VERSION "dbc-export 1 2026.26.6.5"

NS_ :

BS_:

BU_: APP APS BMS CC CMP CMPD CP DAS DI DIF DIR EPBL EPBR EVSE FC GTW HCML HCMR HVP ICR PCS PCS2 PLG PM PMF PMR PTC SCCM SCM SCS SDCR TAS UMC V2G VC VCBATT VCBATT0 VCBATT1 VCBATT2 VCFRONT VCFRONT1 VCFRONT2 VCLEFT VCRIGHT VCSEAT2L VCSEAT2R VCSEC

BO_ 1951 ADSP_audioVisualizer: 1 GTW
 SG_ ADSP_audioVisualizerBrightness : 0|8@1+ (1,0) [0|255] "" Vector__XXX

BO_ 909 APP_VC_infoMessage: 8 APP
 SG_ APP_inTunnel : 0|2@1+ (1,0) [1|3] "" Vector__XXX
 SG_ APP_windshieldHeaterOnReason : 2|4@1+ (1,0) [1|15] "" Vector__XXX
 SG_ APP_selfieCameraBlocked : 6|2@1+ (1,0) [1|3] "" Vector__XXX
 SG_ APP_selfieCameraLUX : 8|8@1+ (1,0) [0|253] "lux" Vector__XXX
 SG_ APP_sceneTagClearlyRaining : 16|2@1+ (1,0) [1|3] "" Vector__XXX
 SG_ APP_sceneTagFog : 18|2@1+ (1,0) [1|3] "" Vector__XXX
 SG_ APP_sceneTagFullyBlocked : 20|2@1+ (1,0) [1|3] "" Vector__XXX
 SG_ APP_sceneTagIndoors : 22|2@1+ (1,0) [1|3] "" Vector__XXX
 SG_ APP_sceneTagLensFlare : 24|2@1+ (1,0) [1|3] "" Vector__XXX
 SG_ APP_sceneTagRaining : 26|2@1+ (1,0) [1|3] "" Vector__XXX
 SG_ APP_sceneTagSevereWeather : 28|2@1+ (1,0) [1|3] "" Vector__XXX
 SG_ APP_sceneTagSnowing : 30|2@1+ (1,0) [1|3] "" Vector__XXX
 SG_ APP_sceneTagSnowyRoad : 32|2@1+ (1,0) [1|3] "" Vector__XXX
 SG_ APP_sceneTagSunGlare : 34|2@1+ (1,0) [1|3] "" Vector__XXX
 SG_ APP_sceneTagTunnel : 36|2@1+ (1,0) [1|3] "" Vector__XXX
 SG_ APP_sceneTagWetRoad : 38|2@1+ (1,0) [1|3] "" Vector__XXX
 SG_ APP_fisheyeInPathVisibility : 40|3@1+ (1,0) [1|7] "" Vector__XXX
 SG_ APP_fisheyeOverallVisibility : 43|3@1+ (1,0) [1|7] "" Vector__XXX
 SG_ APP_mainInPathVisibility : 46|3@1+ (1,0) [1|7] "" Vector__XXX
 SG_ APP_mainOverallVisibility : 49|3@1+ (1,0) [1|7] "" Vector__XXX
 SG_ APP_narrowInPathVisibility : 52|3@1+ (1,0) [1|7] "" Vector__XXX
 SG_ APP_narrowOverallVisibility : 55|3@1+ (1,0) [1|7] "" Vector__XXX
 SG_ APP_frontCamOcclusionType : 58|3@1+ (1,0) [0|7] "" Vector__XXX

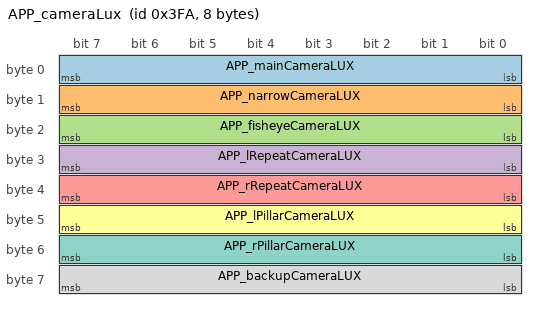
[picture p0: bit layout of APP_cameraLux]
BO_ 1018 APP_cameraLux: 8 APP
 SG_ APP_mainCameraLUX : 0|8@1+ (0.5,0) [0|127] "lux^0.5" Vector__XXX
 SG_ APP_narrowCameraLUX : 8|8@1+ (0.5,0) [0|127] "lux^0.5" Vector__XXX
 SG_ APP_fisheyeCameraLUX : 16|8@1+ (0.5,0) [0|127] "lux^0.5" Vector__XXX
 SG_ APP_lRepeatCameraLUX : 24|8@1+ (0.5,0) [0|127] "lux^0.5" Vector__XXX
 SG_ APP_rRepeatCameraLUX : 32|8@1+ (0.5,0) [0|127] "lux^0.5" Vector__XXX
 SG_ APP_lPillarCameraLUX : 40|8@1+ (0.5,0) [0|127] "lux^0.5" Vector__XXX
 SG_ APP_rPillarCameraLUX : 48|8@1+ (0.5,0) [0|127] "lux^0.5" Vector__XXX
 SG_ APP_backupCameraLUX : 56|8@1+ (0.5,0) [0|127] "lux^0.5" Vector__XXX

BO_ 1056 APS_state: 8 APS
 SG_ APS_primaryTurbo : 0|2@1+ (1,0) [0|3] "" Vector__XXX
 SG_ APS_A_arbState : 2|3@1+ (1,0) [0|7] "" Vector__XXX
 SG_ APS_A_powerState : 5|5@1+ (1,0) [0|31] "" Vector__XXX
 SG_ APS_A_sleepState : 10|4@1+ (1,0) [0|15] "" Vector__XXX
 SG_ APS_A_resetState : 14|3@1+ (1,0) [0|7] "" Vector__XXX
 SG_ APS_A_faultState : 17|5@1+ (1,0) [0|31] "" Vector__XXX
 SG_ APS_secondaryTurbo : 22|2@1+ (1,0) [0|3] "" Vector__XXX
 SG_ APS_B_arbState : 24|3@1+ (1,0) [0|7] "" Vector__XXX
 SG_ APS_B_powerState : 27|5@1+ (1,0) [0|31] "" Vector__XXX
 SG_ APS_B_sleepState : 32|4@1+ (1,0) [0|15] "" Vector__XXX
 SG_ APS_B_resetState : 36|3@1+ (1,0) [0|7] "" Vector__XXX
 SG_ APS_B_faultState : 39|5@1+ (1,0) [0|31] "" Vector__XXX
 SG_ APS_A_autosteerMonitorState : 44|3@1+ (1,0) [0|7] "" Vector__XXX
 SG_ APS_B_autosteerMonitorState : 47|3@1+ (1,0) [0|7] "" Vector__XXX
 SG_ APS_eplannerState : 50|3@1+ (1,0) [0|7] "" Vector__XXX
 SG_ APS_A_faultInduced : 53|1@1+ (1,0) [0|1] "" Vector__XXX
 SG_ APS_B_faultInduced : 54|1@1+ (1,0) [0|1] "" Vector__XXX
 SG_ APS_stateCounter : 55|4@1+ (1,0) [0|15] "" Vector__XXX

BO_ 1343 BMS_alertLog: 8 BMS
 SG_ BMS_alertID M : 0|9@1+ (1,0) [0|511] "" Vector__XXX
 SG_ BMS_alertSet : 15|1@1+ (1,0) [0|1] "" Vector__XXX
 SG_ BMS_a001_gatewayPackEnergy m1 : 16|2@1+ (1,0) [0|3] "" Vector__XXX
 SG_ BMS_a001_expectedPackEnergy m1 : 18|2@1+ (1,0) [0|3] "" Vector__XXX
 SG_ BMS_a002_gatewayPackPerformanceD m2 : 16|3@1+ (1,0) [0|7] "" Vector__XXX
 SG_ BMS_a002_expectedPackPerformance m2 : 19|3@1+ (1,0) [0|7] "" Vector__XXX
 SG_ BMS_a002_bmsPackMass m2 : 24|8@1+ (1,300) [300|555] "kg" Vector__XXX
 SG_ BMS_a003_calBlockData_0 m3 : 16|32@1+ (1,0) [0|4294967295] "" Vector__XXX
 SG_ BMS_a017_packCurrent m17 : 16|8@1+ (8,-1500) [-1500|540] "A" Vector__XXX
 SG_ BMS_a017_ovBrickVID m17 : 24|7@1+ (1,1) [1|128] "" Vector__XXX
 SG_ BMS_a017_ovBrickV m17 : 32|16@1+ (7.62939453125e-05,0) [0|4.99992370605] "V" Vector__XXX
 SG_ BMS_a018_packCurrent m18 : 16|8@1+ (8,-1496) [-1496|544] "A" Vector__XXX
 SG_ BMS_a018_uvBrickVID m18 : 24|7@1+ (1,1) [1|128] "" Vector__XXX
 SG_ BMS_a018_uvBrickV m18 : 32|16@1+ (7.62939453125e-05,0) [0|4.99992370605] "V" Vector__XXX
 SG_ BMS_a019_coolantInletT m19 : 16|8@1+ (0.4,-20) [-20|82] "C" Vector__XXX
 SG_ BMS_a019_activeCoolingTarget m19 : 24|8@1+ (0.4,-20) [-20|82] "C" Vector__XXX
 SG_ BMS_a019_maxBrickT m19 : 32|8@1+ (0.4,-20) [-20|82] "C" Vector__XXX
 SG_ BMS_a019_maxBrickTID m19 : 40|5@1+ (1,1) [1|32] "" Vector__XXX
 SG_ BMS_a021_chargeViolation m21 : 16|1@1+ (1,0) [0|1] "" Vector__XXX
 SG_ BMS_a021_currentLimit m21 : 24|8@1+ (8,-1496) [-1496|544] "A" Vector__XXX
 SG_ BMS_a021_packCurrent m21 : 32|8@1+ (8,-1496) [-1496|544] "A" Vector__XXX
 SG_ BMS_a022_chargeAccumulatorViolat m22 : 16|1@1+ (1,0) [0|1] "" Vector__XXX
 SG_ BMS_a022_chargeAccumulatorValue m22 : 17|23@1+ (10,0) [0|83886070] "A^2s" Vector__XXX
 SG_ BMS_a022_chargeAccumulatorLimit m22 : 40|23@1+ (10,0) [0|83886070] "A^2s" Vector__XXX
 SG_ BMS_a023_ovStackDeviceID m23 : 16|5@1+ (1,1) [1|32] "-" Vector__XXX
 SG_ BMS_a023_ovStackV m23 : 24|16@1+ (0.00128,0) [0|83.8848] "V" Vector__XXX
 SG_ BMS_a024_brickID m24 : 16|8@1+ (1,1) [1|256] "-" Vector__XXX
 SG_ BMS_a024_deltaV m24 : 24|16@1- (0.0001,0) [-3.2768|3.2767] "V" Vector__XXX
 SG_ BMS_a024_avgDvPrev m24 : 40|16@1- (0.0001,0) [-3.2768|3.2767] "V" Vector__XXX
 SG_ BMS_a024_packCurrent m24 : 56|8@1+ (8,-1500) [-1500|540] "A" Vector__XXX
 SG_ BMS_a027_swIsolationCount m27 : 16|8@1+ (1,0) [0|255] "" Vector__XXX
 SG_ BMS_a030_worstBrickID m30 : 16|8@1+ (1,1) [1|256] "" Vector__XXX
 SG_ BMS_a030_maxBrickImpedance m30 : 24|10@1+ (0.1,0) [0|102.3] "mOhm" Vector__XXX
 SG_ BMS_a030_maxNormalizedImpedanceD m30 : 34|7@1+ (0.04,0) [0|5.08] "Ratio" Vector__XXX
 SG_ BMS_a030_faultThreshold m30 : 41|7@1+ (0.04,0) [0|5.08] "Ratio" Vector__XXX
 SG_ BMS_a030_numBricks m30 : 48|8@1+ (1,0) [0|255] "" Vector__XXX
 SG_ BMS_a030_worstBrickSoc m30 : 56|8@1+ (0.5,0) [0|127.5] "PCT" Vector__XXX
 SG_ BMS_a035_isoR m35 : 16|9@1+ (10,0) [0|5110] "kOhm" Vector__XXX
 SG_ BMS_a035_mode m35 : 25|3@1+ (1,0) [0|7] "" Vector__XXX
 SG_ BMS_a035_activeSideVNoR m35 : 28|9@1+ (1,0) [0|511] "V" Vector__XXX
 SG_ BMS_a035_activeSideVWithR m35 : 37|9@1+ (1,0) [0|511] "V" Vector__XXX
 SG_ BMS_a035_passiveSideVNoR m35 : 46|9@1+ (1,0) [0|511] "V" Vector__XXX
 SG_ BMS_a035_passiveSideVWithR m35 : 55|9@1+ (1,0) [0|511] "V" Vector__XXX
 SG_ BMS_a039_dcLinkVoltage m39 : 16|10@1+ (1,0) [0|1023] "V" Vector__XXX
 SG_ BMS_a039_packVoltage m39 : 26|10@1+ (1,0) [0|1023] "V" Vector__XXX
 SG_ BMS_a039_packContactorState m39 : 36|4@1+ (1,0) [1|15] "" Vector__XXX
 SG_ BMS_a039_packCurrent m39 : 40|8@1+ (8,-1496) [-1496|544] "A" Vector__XXX
 SG_ BMS_a039_maxBrickV m39 : 48|8@1+ (0.01,2) [2|4.55] "V" Vector__XXX
 SG_ BMS_a039_state m39 : 56|4@1+ (1,0) [0|15] "" Vector__XXX
 SG_ BMS_a041_resetType m41 : 16|4@1+ (1,0) [0|15] "" Vector__XXX
 SG_ BMS_a050_MIA_numBadReadings m50 : 16|8@1+ (1,0) [0|255] "" Vector__XXX
 SG_ BMS_a050_MIA_numSnaReadings m50 : 24|8@1+ (1,0) [0|255] "" Vector__XXX
 SG_ BMS_a050_MIA_brickId m50 : 32|8@1+ (1,1) [1|256] "" Vector__XXX
 SG_ BMS_a051_hvp1V5Ref m51 : 16|12@1+ (0.001,0) [0|4.095] "V" Vector__XXX
 SG_ BMS_a051_hvp3V0Ref m51 : 28|12@1+ (0.001,0) [0|4.095] "V" Vector__XXX
 SG_ BMS_a051_bms3V0Ref m51 : 40|12@1+ (0.001,0) [0|4.095] "V" Vector__XXX
 SG_ BMS_a059_sumBrickVoltages m59 : 16|16@1+ (0.01,0) [0|655.35] "V" Vector__XXX
 SG_ BMS_a059_packVoltage m59 : 32|16@1+ (0.01,0) [0|655.35] "V" Vector__XXX
 SG_ BMS_a062_state m62 : 16|4@1+ (1,0) [0|15] "" Vector__XXX
 SG_ BMS_a062_minBrickVId m62 : 24|7@1+ (1,1) [1|128] "" Vector__XXX
 SG_ BMS_a062_minBrickVoltage m62 : 32|12@1+ (0.002,0) [0|8.19] "V" Vector__XXX
 SG_ BMS_a062_maxBrickVId m62 : 44|7@1+ (1,1) [1|128] "" Vector__XXX
 SG_ BMS_a062_maxBrickVoltage m62 : 51|12@1+ (0.002,0) [0|8.19] "V" Vector__XXX
 SG_ BMS_a063_cpFaultInV m63 : 16|12@1+ (0.001,0) [0|4.095] "V" Vector__XXX
 SG_ BMS_a064_minBrickSOCID m64 : 16|7@1+ (1,1) [1|128] "" Vector__XXX
 SG_ BMS_a064_minBrickSOC m64 : 24|8@1+ (0.5,0) [0|127.5] "PCT" Vector__XXX
 SG_ BMS_a064_maxBrickSOCID m64 : 32|7@1+ (1,1) [1|128] "" Vector__XXX
 SG_ BMS_a064_maxBrickSOC m64 : 40|8@1+ (0.5,0) [0|127.5] "PCT" Vector__XXX
 SG_ BMS_a064_avgBrickSOC m64 : 48|8@1+ (0.5,0) [0|127.5] "PCT" Vector__XXX
 SG_ BMS_a065_minBrickCacId m65 : 16|7@1+ (1,1) [1|128] "" Vector__XXX
 SG_ BMS_a065_minBrickCac m65 : 24|13@1+ (0.1,0) [0|819.1] "Ah" Vector__XXX
 SG_ BMS_a065_avgBrickCac m65 : 40|13@1+ (0.1,0) [0|819.1] "Ah" Vector__XXX
 SG_ BMS_a065_modCacImbalancePct m65 : 53|10@1+ (0.1,0) [0|102.3] "%" Vector__XXX
 SG_ BMS_a066_minBrickSocId m66 : 16|7@1+ (1,1) [1|128] "" Vector__XXX
 SG_ BMS_a066_minBrickSocByOcvMax m66 : 24|8@1+ (0.5,0) [0|127.5] "PCT" Vector__XXX
 SG_ BMS_a066_maxBrickSocId m66 : 32|7@1+ (1,1) [1|128] "" Vector__XXX
 SG_ BMS_a066_maxBrickSocByOcvMin m66 : 40|8@1+ (0.5,0) [0|127.5] "PCT" Vector__XXX
 SG_ BMS_a066_maxBrickSoc m66 : 48|8@1+ (0.5,0) [0|127.5] "PCT" Vector__XXX
 SG_ BMS_a066_avgBrickSoc m66 : 56|8@1+ (0.5,0) [0|127.5] "PCT" Vector__XXX
 SG_ BMS_a067_minBrickCacId m67 : 16|7@1+ (1,1) [1|128] "" Vector__XXX
 SG_ BMS_a067_minBrickCac m67 : 24|13@1+ (0.1,0) [0|819.1] "Ah" Vector__XXX
 SG_ BMS_a067_avgBrickCac m67 : 40|13@1+ (0.1,0) [0|819.1] "Ah" Vector__XXX
 SG_ BMS_a067_modCacImbalancePct m67 : 53|10@1+ (0.1,0) [0|102.3] "%" Vector__XXX
 SG_ BMS_a068_minBrickCacId m68 : 16|7@1+ (1,1) [1|128] "" Vector__XXX
 SG_ BMS_a068_minBrickCac m68 : 24|13@1+ (0.1,0) [0|819.1] "Ah" Vector__XXX
 SG_ BMS_a068_avgBrickCac m68 : 40|13@1+ (0.1,0) [0|819.1] "Ah" Vector__XXX
 SG_ BMS_a068_modCacImbalancePct m68 : 53|10@1+ (0.1,0) [0|102.3] "%" Vector__XXX
 SG_ BMS_a069_dischargePowerPackVolta m69 : 16|8@1- (0.025,-3.15) [-6.35|0.025] "kW" Vector__XXX
 SG_ BMS_a069_dischargePowerBrickVolt m69 : 24|8@1- (0.005,-0.63) [-1.27|0.005] "kW" Vector__XXX
 SG_ BMS_a069_SOC m69 : 32|8@1+ (0.05,0) [0|12.75] "PCT" Vector__XXX
 SG_ BMS_a069_minBrickT m69 : 40|8@1- (0.5,24) [-40|87.5] "DegC" Vector__XXX
 SG_ BMS_a069_minBrickVLimit m69 : 48|8@1+ (0.01,2) [2|4.55] "V" Vector__XXX
 SG_ BMS_a069_minBrickV m69 : 56|8@1+ (0.01,2) [2|4.55] "V" Vector__XXX
 SG_ BMS_a070_state m70 : 16|4@1+ (1,0) [0|15] "" Vector__XXX
 SG_ BMS_a070_minBrickVId m70 : 24|7@1+ (1,1) [1|128] "" Vector__XXX
 SG_ BMS_a070_minBrickVoltage m70 : 32|12@1+ (0.002,0) [0|8.19] "V" Vector__XXX
 SG_ BMS_a070_maxBrickVId m70 : 44|7@1+ (1,1) [1|128] "" Vector__XXX
 SG_ BMS_a070_maxBrickVoltage m70 : 51|12@1+ (0.002,0) [0|8.19] "V" Vector__XXX
 SG_ BMS_a071_stateRequest m71 : 16|4@1+ (1,0) [0|15] "" Vector__XXX
 SG_ BMS_a071_state m71 : 20|4@1+ (1,0) [0|15] "" Vector__XXX
 SG_ BMS_a071_transitionAlertId m71 : 24|10@1+ (1,0) [0|1023] "" Vector__XXX
 SG_ BMS_a074_maxBrickVTarget m74 : 16|8@1+ (0.01,2) [2|4.55] "V" Vector__XXX
 SG_ BMS_a074_maxBrickV m74 : 24|8@1+ (0.01,2) [2|4.55] "V" Vector__XXX
 SG_ BMS_a075_chargeType m75 : 16|1@1+ (1,0) [0|1] "" Vector__XXX
 SG_ BMS_a076_netAh m76 : 16|21@1- (0.01,0) [-10485.76|10485.75] "Ah" Vector__XXX
 SG_ BMS_a076_tetheringActive m76 : 37|1@1+ (1,0) [0|1] "" Vector__XXX
 SG_ BMS_a077_chargeErrType m77 : 16|1@1+ (1,0) [0|1] "" Vector__XXX
 SG_ BMS_a077_maxBrickVTarget m77 : 24|8@1+ (0.01,2) [2|4.55] "V" Vector__XXX
 SG_ BMS_a077_maxBrickV m77 : 32|8@1+ (0.01,2) [2|4.55] "V" Vector__XXX
 SG_ BMS_a077_packTargetCurrent m77 : 40|8@1+ (8,-1496) [-1496|544] "A" Vector__XXX
 SG_ BMS_a077_packCurrent m77 : 48|8@1+ (8,-1496) [-1496|544] "A" Vector__XXX
 SG_ BMS_a078_peakDchInChg m78 : 16|16@1- (0.1,0) [-3276.8|3276.7] "A" Vector__XXX
 SG_ BMS_a079_maxBrickVTarget m79 : 16|8@1+ (0.01,2) [2|4.55] "V" Vector__XXX
 SG_ BMS_a079_maxBrickV m79 : 24|8@1+ (0.01,2) [2|4.55] "V" Vector__XXX
 SG_ BMS_a081_stateRequest m81 : 16|4@1+ (1,0) [0|15] "" Vector__XXX
 SG_ BMS_a081_firstBlockingAlertId m81 : 20|9@1+ (1,0) [0|511] "" Vector__XXX
 SG_ BMS_a081_secondBlockingAlertId m81 : 29|9@1+ (1,0) [0|511] "" Vector__XXX
 SG_ BMS_a081_thirdBlockingAlertId m81 : 38|9@1+ (1,0) [0|511] "" Vector__XXX
 SG_ BMS_a081_fourthBlockingAlertId m81 : 47|9@1+ (1,0) [0|511] "" Vector__XXX
 SG_ BMS_a081_totalAlertCount m81 : 56|8@1+ (1,0) [0|255] "" Vector__XXX
 SG_ BMS_a082_stateRequest m82 : 16|4@1+ (1,0) [0|15] "" Vector__XXX
 SG_ BMS_a082_firstAlertId m82 : 20|9@1+ (1,0) [0|511] "" Vector__XXX
 SG_ BMS_a082_secondAlertId m82 : 29|9@1+ (1,0) [0|511] "" Vector__XXX
 SG_ BMS_a082_thirdAlertId m82 : 38|9@1+ (1,0) [0|511] "" Vector__XXX
 SG_ BMS_a082_fourthAlertId m82 : 47|9@1+ (1,0) [0|511] "" Vector__XXX
 SG_ BMS_a082_totalAlertCount m82 : 56|8@1+ (1,0) [0|255] "" Vector__XXX
 SG_ BMS_a083_packContactorRequest m83 : 16|3@1+ (1,0) [1|7] "" Vector__XXX
 SG_ BMS_a085_packContactorSetStatePr m85 : 16|4@1+ (1,0) [1|15] "" Vector__XXX
 SG_ BMS_a085_packContactorSetState m85 : 20|4@1+ (1,0) [1|15] "" Vector__XXX
 SG_ BMS_a085_packContactorSetRe_0001 m85 : 24|3@1+ (1,0) [1|7] "" Vector__XXX
 SG_ BMS_a085_packContactorSetRequest m85 : 27|3@1+ (1,0) [1|7] "" Vector__XXX
 SG_ BMS_a086_fcContactorSetStatePrev m86 : 16|4@1+ (1,0) [1|15] "" Vector__XXX
 SG_ BMS_a086_fcContactorSetState m86 : 20|4@1+ (1,0) [1|15] "" Vector__XXX
 SG_ BMS_a086_fcContactorSetRequestPr m86 : 24|3@1+ (1,0) [1|7] "" Vector__XXX
 SG_ BMS_a086_fcContactorSetRequest m86 : 27|3@1+ (1,0) [1|7] "" Vector__XXX
 SG_ BMS_a087_blockingAlert m87 : 16|9@1+ (1,0) [0|511] "" Vector__XXX
 SG_ BMS_a090_GTWmessageTout m90 : 16|4@1+ (1,0) [0|15] "" Vector__XXX
 SG_ BMS_a098_breakLocationA m98 : 16|5@1+ (1,0) [0|31] "" Vector__XXX
 SG_ BMS_a098_bmbCommStatusTypeA m98 : 21|2@1+ (1,0) [0|3] "" Vector__XXX
 SG_ BMS_a098_breakLocationB m98 : 24|5@1+ (1,0) [0|31] "" Vector__XXX
 SG_ BMS_a098_bmbCommStatusTypeB m98 : 29|2@1+ (1,0) [0|3] "" Vector__XXX
 SG_ BMS_a098_alertFromHvp m98 : 31|1@1+ (1,0) [0|1] "" Vector__XXX
 SG_ BMS_a099_breakLocationA m99 : 16|5@1+ (1,0) [0|31] "" Vector__XXX
 SG_ BMS_a099_bmbCommStatusTypeA m99 : 21|2@1+ (1,0) [0|3] "" Vector__XXX
 SG_ BMS_a099_breakLocationB m99 : 24|5@1+ (1,0) [0|31] "" Vector__XXX
 SG_ BMS_a099_bmbCommStatusTypeB m99 : 29|2@1+ (1,0) [0|3] "" Vector__XXX
 SG_ BMS_a099_bmbChainBreakType m99 : 32|3@1+ (1,0) [0|7] "" Vector__XXX
 SG_ BMS_a099_alertFromHvp m99 : 35|1@1+ (1,0) [0|1] "" Vector__XXX
 SG_ BMS_a100_testTrigger m100 : 16|1@1+ (1,0) [0|1] "" Vector__XXX
 SG_ BMS_a100_setFromNvm m100 : 17|1@1+ (1,0) [0|1] "" Vector__XXX
 SG_ BMS_a100_voltageDeviation m100 : 18|1@1+ (1,0) [0|1] "" Vector__XXX
 SG_ BMS_a100_voltageLoss m100 : 19|1@1+ (1,0) [0|1] "" Vector__XXX
 SG_ BMS_a105_tSenseFailedModule1 m105 : 16|1@1+ (1,0) [0|1] "" Vector__XXX
 SG_ BMS_a105_avgBrickTModule1 m105 : 17|8@1+ (0.5,0) [0|127.5] "C" Vector__XXX
 SG_ BMS_a105_tSenseFailedModule2 m105 : 25|1@1+ (1,0) [0|1] "" Vector__XXX
 SG_ BMS_a105_avgBrickTModule2 m105 : 26|8@1+ (0.5,0) [0|127.5] "C" Vector__XXX
 SG_ BMS_a105_tSenseFailedModule3 m105 : 34|1@1+ (1,0) [0|1] "" Vector__XXX
 SG_ BMS_a105_avgBrickTModule3 m105 : 35|8@1+ (0.5,0) [0|127.5] "C" Vector__XXX
 SG_ BMS_a105_tSenseFailedModule4 m105 : 43|1@1+ (1,0) [0|1] "" Vector__XXX
 SG_ BMS_a105_avgBrickTModule4 m105 : 44|8@1+ (0.5,0) [0|127.5] "C" Vector__XXX
 SG_ BMS_a105_inletTemp m105 : 52|8@1+ (0.5,0) [0|127.5] "C" Vector__XXX
 SG_ BMS_a106_minBrickT m106 : 16|8@1+ (0.5,0) [0|127.5] "C" Vector__XXX
 SG_ BMS_a106_maxBrickT m106 : 24|8@1+ (0.5,0) [0|127.5] "C" Vector__XXX
 SG_ BMS_a106_avgBrickT m106 : 32|8@1+ (0.5,0) [0|127.5] "C" Vector__XXX
 SG_ BMS_a106_inletTemp m106 : 40|8@1+ (0.5,0) [0|127.5] "C" Vector__XXX
 SG_ BMS_a107_MIA_numBadReadings m107 : 16|8@1+ (1,0) [0|255] "" Vector__XXX
 SG_ BMS_a107_MIA_numSnaReadings m107 : 24|8@1+ (1,0) [0|255] "" Vector__XXX
 SG_ BMS_a107_MIA_stackId m107 : 32|8@1+ (1,1) [1|256] "" Vector__XXX
 SG_ BMS_a109_muteMask m109 : 16|16@1+ (1,0) [0|65535] "" Vector__XXX
 SG_ BMS_a109_packInBleed m109 : 32|1@1+ (1,0) [0|1] "" Vector__XXX
 SG_ BMS_a117_brickID m117 : 16|7@1+ (1,1) [1|128] "" Vector__XXX
 SG_ BMS_a117_brickSoc2 m117 : 23|10@1+ (0.1,0) [0|102.2] "%" Vector__XXX
 SG_ BMS_a117_dSocAlertThreshold m117 : 33|5@1+ (0.125,-4) [-4|-0.125] "%" Vector__XXX
 SG_ BMS_a117_dSocAlpha m117 : 48|12@1+ (0.0030517578125,-12.4969482422) [-12.4969482422|-0.003051757825] "%" Vector__XXX
 SG_ BMS_a118_brickID m118 : 16|7@1+ (1,1) [1|128] "" Vector__XXX
 SG_ BMS_a118_brickSoc2 m118 : 23|10@1+ (0.1,0) [0|102.2] "%" Vector__XXX
 SG_ BMS_a118_dSocAlertThreshold m118 : 33|5@1+ (0.125,-4) [-4|-0.125] "%" Vector__XXX
 SG_ BMS_a118_dSocAlpha m118 : 48|12@1+ (0.0030517578125,-12.4969482422) [-12.4969482422|-0.003051757825] "%" Vector__XXX
 SG_ BMS_a122_thermistorID m122 : 16|5@1+ (1,1) [1|32] "" Vector__XXX
 SG_ BMS_a122_irrationalThermistorTem m122 : 24|8@1+ (0.5,-40) [-40|87.5] "DegC" Vector__XXX
 SG_ BMS_a122_averageRawThermistorTem m122 : 32|8@1+ (0.5,-40) [-40|87.5] "DegC" Vector__XXX
 SG_ BMS_a122_minRawThermistorTemp m122 : 40|8@1+ (0.5,-40) [-40|87.5] "DegC" Vector__XXX
 SG_ BMS_a122_maxRawThermistorTemp m122 : 48|8@1+ (0.5,-40) [-40|87.5] "DegC" Vector__XXX
 SG_ BMS_a122_numValidThermistors m122 : 56|5@1+ (1,0) [0|31] "" Vector__XXX
 SG_ BMS_a123_packPlus m123 : 32|8@1+ (4,0) [0|1020] "V" Vector__XXX
 SG_ BMS_a123_isoR m123 : 40|10@1+ (10,0) [0|10230] "kOhm" Vector__XXX
 SG_ BMS_a123_packMinus m123 : 56|8@1- (4,0) [-512|508] "V" Vector__XXX
 SG_ BMS_a129_brickID m129 : 16|8@1+ (1,1) [1|256] "-" Vector__XXX
 SG_ BMS_a129_deltaV m129 : 24|16@1- (0.0002,0) [-6.5536|6.5534] "V" Vector__XXX
 SG_ BMS_a129_retryCount m129 : 40|4@1+ (1,0) [0|15] "-" Vector__XXX
 SG_ BMS_a131_brickID m131 : 16|8@1+ (1,1) [1|256] "-" Vector__XXX
 SG_ BMS_a131_deltaV m131 : 24|16@1- (0.0002,0) [-6.5536|6.5534] "V" Vector__XXX
 SG_ BMS_a131_retryCount m131 : 40|4@1+ (1,0) [0|15] "-" Vector__XXX
 SG_ BMS_a132_multiVendorErrorMask m132 : 16|16@1+ (1,0) [0|65535] "" Vector__XXX
 SG_ BMS_a135_bmbDiagnosticsType m135 : 16|2@1+ (1,0) [0|3] "" Vector__XXX
 SG_ BMS_a135_bmbDeviceId m135 : 18|4@1+ (1,1) [1|16] "" Vector__XXX
 SG_ BMS_a135_readCVA m135 : 22|1@1+ (1,0) [0|1] "" Vector__XXX
 SG_ BMS_a135_readCVB m135 : 23|1@1+ (1,0) [0|1] "" Vector__XXX
 SG_ BMS_a135_readCVC m135 : 24|1@1+ (1,0) [0|1] "" Vector__XXX
 SG_ BMS_a135_readCVD m135 : 25|1@1+ (1,0) [0|1] "" Vector__XXX
 SG_ BMS_a135_readCVE m135 : 26|1@1+ (1,0) [0|1] "" Vector__XXX
 SG_ BMS_a135_readCVF m135 : 27|1@1+ (1,0) [0|1] "" Vector__XXX
 SG_ BMS_a135_readSNA m135 : 28|1@1+ (1,0) [0|1] "" Vector__XXX
 SG_ BMS_a135_readSNB m135 : 29|1@1+ (1,0) [0|1] "" Vector__XXX
 SG_ BMS_a135_readSNC m135 : 30|1@1+ (1,0) [0|1] "" Vector__XXX
 SG_ BMS_a135_readSND m135 : 31|1@1+ (1,0) [0|1] "" Vector__XXX
 SG_ BMS_a135_readSNE m135 : 32|1@1+ (1,0) [0|1] "" Vector__XXX
 SG_ BMS_a135_readSNF m135 : 33|1@1+ (1,0) [0|1] "" Vector__XXX
 SG_ BMS_a135_readAUXA m135 : 34|1@1+ (1,0) [0|1] "" Vector__XXX
 SG_ BMS_a135_readAUXB m135 : 35|1@1+ (1,0) [0|1] "" Vector__XXX
 SG_ BMS_a135_readSTAT m135 : 36|1@1+ (1,0) [0|1] "" Vector__XXX
 SG_ BMS_a136_maxBrickTID m136 : 16|5@1+ (1,1) [1|32] "" Vector__XXX
 SG_ BMS_a136_coolantInletT m136 : 24|8@1+ (0.4,-20) [-20|82] "C" Vector__XXX
 SG_ BMS_a136_activeCoolingTarget m136 : 32|8@1+ (0.4,-20) [-20|82] "C" Vector__XXX
 SG_ BMS_a136_maxBrickT m136 : 40|8@1+ (0.4,-20) [-20|82] "C" Vector__XXX
 SG_ BMS_a139_packVoltage m139 : 16|16@1- (0.01,0) [-327.68|327.67] "V" Vector__XXX
 SG_ BMS_a139_dcLinkVoltage m139 : 32|16@1+ (0.01,0) [0|655.35] "V" Vector__XXX
 SG_ BMS_a140_bmbDeviceMask m140 : 16|16@1+ (1,0) [0|65535] "" Vector__XXX
 SG_ BMS_a140_faultType m140 : 32|8@1+ (1,0) [0|255] "" Vector__XXX
 SG_ BMS_a142_isolationResistance m142 : 16|10@1+ (10,0) [0|10230] "kOhm" Vector__XXX
 SG_ BMS_a142_mode m142 : 32|3@1+ (1,0) [0|7] "" Vector__XXX
 SG_ BMS_a143_initialSoc m143 : 16|9@1+ (0.2,0) [0|102.2] "%" Vector__XXX
 SG_ BMS_a143_endingSoc m143 : 25|9@1+ (0.2,0) [0|102.2] "%" Vector__XXX
 SG_ BMS_a143_deltaAh m143 : 34|9@1+ (0.5,0) [0|255.5] "Ah" Vector__XXX
 SG_ BMS_a143_cacChangeBrickID m143 : 48|7@1+ (1,1) [1|128] "" Vector__XXX
 SG_ BMS_a143_cacUpdateError m143 : 56|8@1+ (0.1,0) [0|25.5] "Ah" Vector__XXX
 SG_ BMS_a144_HVP_major_version m144 : 16|16@1+ (1,0) [0|65535] "" Vector__XXX
 SG_ BMS_a144_HVP_minor_version m144 : 32|16@1+ (1,0) [0|65535] "" Vector__XXX
 SG_ BMS_a144_BMS_minor_version m144 : 48|16@1+ (1,0) [0|65535] "" Vector__XXX
 SG_ BMS_a145_maxSocChange m145 : 16|11@1- (0.1,0) [-102.4|102.3] "%" Vector__XXX
 SG_ BMS_a145_maxSocChangeBrickID m145 : 32|7@1+ (1,1) [1|128] "" Vector__XXX
 SG_ BMS_a145_numBricksChanged m145 : 40|7@1+ (1,0) [0|127] "" Vector__XXX
 SG_ BMS_a145_brickChangeHystRatio m145 : 48|10@1+ (0.001,0) [0|1.022] "Ratio" Vector__XXX
 SG_ BMS_a146_maxBrickV m146 : 16|8@1+ (0.01,2) [2|4.55] "V" Vector__XXX
 SG_ BMS_a146_state m146 : 24|4@1+ (1,0) [0|15] "" Vector__XXX
 SG_ BMS_a146_packCurrent m146 : 32|8@1+ (8,-1496) [-1496|544] "A" Vector__XXX
 SG_ BMS_a146_uvBrickVID m146 : 40|7@1+ (1,1) [1|128] "" Vector__XXX
 SG_ BMS_a146_uvBrickV m146 : 48|16@1+ (7.62939453125e-05,0) [0|4.99992370605] "V" Vector__XXX
 SG_ BMS_a151_isoPositiveR m151 : 32|10@1+ (10,0) [0|10230] "kOhm" Vector__XXX
 SG_ BMS_a151_isoNegativeR m151 : 42|10@1+ (10,0) [0|10230] "kOhm" Vector__XXX
 SG_ BMS_a152_isoR m152 : 16|9@1+ (10,0) [0|5110] "kOhm" Vector__XXX
 SG_ BMS_a152_mode m152 : 25|3@1+ (1,0) [0|7] "" Vector__XXX
 SG_ BMS_a152_activeSideVNoR m152 : 28|9@1+ (1,0) [0|511] "V" Vector__XXX
 SG_ BMS_a152_activeSideVWithR m152 : 37|9@1+ (1,0) [0|511] "V" Vector__XXX
 SG_ BMS_a152_passiveSideVNoR m152 : 46|9@1+ (1,0) [0|511] "V" Vector__XXX
 SG_ BMS_a152_passiveSideVWithR m152 : 55|9@1+ (1,0) [0|511] "V" Vector__XXX
 SG_ BMS_a154_packCurrent m154 : 16|8@1+ (4,0) [0|1020] "A" Vector__XXX
 SG_ BMS_a154_ovBrickVID m154 : 24|7@1+ (1,1) [1|128] "" Vector__XXX
 SG_ BMS_a154_ovBrickV m154 : 32|16@1+ (7.62939453125e-05,0) [0|4.99992370605] "V" Vector__XXX
 SG_ BMS_a156_VrefSample m156 : 16|16@1+ (0.0001,0) [0|6.5535] "V" Vector__XXX
 SG_ BMS_a156_bmbDeviceId m156 : 32|4@1+ (1,1) [1|16] "" Vector__XXX
 SG_ BMS_a156_VrefStatus m156 : 36|2@1+ (1,0) [0|3] "" Vector__XXX
 SG_ BMS_a158_shuntCurrentMia m158 : 16|1@1+ (1,0) [0|1] "" Vector__XXX
 SG_ BMS_a158_contactorStateMia m158 : 17|1@1+ (1,0) [0|1] "" Vector__XXX
 SG_ BMS_a158_hvpFaultsMia m158 : 18|1@1+ (1,0) [0|1] "" Vector__XXX
 SG_ BMS_a162_dischargePower_W m162 : 16|16@1- (1,0) [-32768|32767] "W" Vector__XXX
 SG_ BMS_a162_minSoc m162 : 32|16@1+ (1,0) [0|65535] "%" Vector__XXX
 SG_ BMS_a162_socThreshold m162 : 48|16@1+ (1,0) [0|65535] "%" Vector__XXX
 SG_ BMS_a164_regenPower m164 : 16|32@1+ (1,0) [0|4294967295] "W" Vector__XXX
 SG_ BMS_a165_packPositiveV m165 : 16|12@1- (0.25,0) [-512|511.75] "V" Vector__XXX
 SG_ BMS_a165_packNegativeV m165 : 28|12@1- (0.25,0) [-512|511.75] "V" Vector__XXX
 SG_ BMS_a165_dcLinkPositiveV m165 : 40|12@1- (0.25,0) [-512|511.75] "V" Vector__XXX
 SG_ BMS_a165_dcLinkNegativeV m165 : 52|12@1- (0.25,0) [-512|511.75] "V" Vector__XXX
 SG_ BMS_a166_packPositiveV m166 : 16|12@1- (0.25,0) [-512|511.75] "V" Vector__XXX
 SG_ BMS_a166_packNegativeV m166 : 28|12@1- (0.25,0) [-512|511.75] "V" Vector__XXX
 SG_ BMS_a166_dcLinkPositiveV m166 : 40|12@1- (0.25,0) [-512|511.75] "V" Vector__XXX
 SG_ BMS_a166_dcLinkNegativeV m166 : 52|12@1- (0.25,0) [-512|511.75] "V" Vector__XXX
 SG_ BMS_a167_fcContPositiveAuxOpen m167 : 16|1@1+ (1,0) [0|1] "" Vector__XXX
 SG_ BMS_a167_fcContNegativeAuxOpen m167 : 17|1@1+ (1,0) [0|1] "" Vector__XXX
 SG_ BMS_a167_dcLinkPositiveV m167 : 18|11@1- (0.5,0) [-512|511.5] "V" Vector__XXX
 SG_ BMS_a167_dcLinkNegativeV m167 : 29|11@1- (0.5,0) [-512|511.5] "V" Vector__XXX
 SG_ BMS_a167_fcLinkPositiveV m167 : 40|11@1- (0.5,0) [-512|511.5] "V" Vector__XXX
 SG_ BMS_a167_fcLinkNegativeV m167 : 51|11@1- (0.5,0) [-512|511.5] "V" Vector__XXX
 SG_ BMS_a168_fcContPositiveAuxOpen m168 : 16|1@1+ (1,0) [0|1] "" Vector__XXX
 SG_ BMS_a168_fcContNegativeAuxOpen m168 : 17|1@1+ (1,0) [0|1] "" Vector__XXX
 SG_ BMS_a168_dcLinkPositiveV m168 : 18|11@1- (0.5,0) [-512|511.5] "V" Vector__XXX
 SG_ BMS_a168_dcLinkNegativeV m168 : 29|11@1- (0.5,0) [-512|511.5] "V" Vector__XXX
 SG_ BMS_a168_fcLinkPositiveV m168 : 40|11@1- (0.5,0) [-512|511.5] "V" Vector__XXX
 SG_ BMS_a168_fcLinkNegativeV m168 : 51|11@1- (0.5,0) [-512|511.5] "V" Vector__XXX
 SG_ BMS_a169_DCAndFCContactorsWelded m169 : 16|1@1+ (1,0) [0|1] "" Vector__XXX
 SG_ BMS_a170_limpModeActive m170 : 16|1@1+ (1,0) [0|1] "" Vector__XXX
 SG_ BMS_a171_stackVoltage m171 : 16|16@1+ (0.00128,0) [0|83.8848] "V" Vector__XXX
 SG_ BMS_a171_sumBrickVoltage m171 : 32|16@1+ (0.00128,0) [0|83.8848] "V" Vector__XXX
 SG_ BMS_a171_stackId m171 : 48|8@1+ (1,1) [1|256] "" Vector__XXX
 SG_ BMS_a172_swIsolationCount m172 : 16|8@1+ (1,0) [0|255] "" Vector__XXX
 SG_ BMS_a177_energyAlertThreshold m177 : 16|10@1+ (0.1,0) [0|102.3] "KWh" Vector__XXX
 SG_ BMS_a177_energyBuffer m177 : 26|10@1+ (0.1,0) [0|102.3] "KWh" Vector__XXX
 SG_ BMS_a178_diPower m178 : 16|9@1- (4.3137254715,250.196075439) [-854.117645265|1350.19607067] "kW" Vector__XXX
 SG_ BMS_a178_energyError m178 : 25|8@1- (2,0) [-256|254] "kJ" Vector__XXX
 SG_ BMS_a178_powerError m178 : 33|9@1- (1,0) [-256|255] "kW" Vector__XXX
 SG_ BMS_a178_minPowerError m178 : 42|9@1- (1,0) [-256|255] "kW" Vector__XXX
 SG_ BMS_a178_maxPowerError m178 : 51|9@1- (1,0) [-256|255] "kW" Vector__XXX
 SG_ BMS_a178_diMiaCount m178 : 60|2@1+ (1,0) [0|3] "" Vector__XXX
 SG_ BMS_a178_diSnaCount m178 : 62|2@1+ (1,0) [0|3] "" Vector__XXX
 SG_ BMS_a188_currentTripThreshold m188 : 16|16@1+ (0.0025,0) [0|163.8375] "A" Vector__XXX
 SG_ BMS_a188_dcLinkDetectedCurrent m188 : 32|16@1+ (0.0025,0) [0|163.8375] "A" Vector__XXX
 SG_ BMS_a189_currentTripThreshold m189 : 16|16@1- (0.0025,-75) [-156.92|6.9175] "A" Vector__XXX
 SG_ BMS_a189_dcLinkDetectedCurrent m189 : 32|16@1- (0.0025,-75) [-156.92|6.9175] "A" Vector__XXX
 SG_ BMS_a190_voltageTripThreshold m190 : 16|16@1+ (0.025,0) [0|1638.375] "V" Vector__XXX
 SG_ BMS_a190_dcLinkDetectedVoltage m190 : 32|16@1+ (0.025,0) [0|1638.375] "V" Vector__XXX
 SG_ BMS_a191_voltageTripThreshold m191 : 16|16@1+ (0.025,0) [0|1638.375] "V" Vector__XXX
 SG_ BMS_a191_dcLinkDetectedVoltage m191 : 32|16@1+ (0.025,0) [0|1638.375] "V" Vector__XXX
 SG_ BMS_a192_detectedChargeCurrent m192 : 16|16@1+ (0.0025,0) [0|163.8375] "A" Vector__XXX
 SG_ BMS_a193_maxBrickVoltageLimit m193 : 16|12@1+ (0.001,1) [1|5.095] "V" Vector__XXX
 SG_ BMS_a193_detectedMaxBrickVoltage m193 : 28|12@1+ (0.001,1) [1|5.095] "V" Vector__XXX
 SG_ BMS_a201_maxBrickV m201 : 16|16@1+ (7.62939453125e-05,0) [0|4.99992370605] "V" Vector__XXX
 SG_ BMS_a201_maxBrickVIndex m201 : 32|7@1+ (1,1) [1|128] "" Vector__XXX
 SG_ BMS_a227_packCurrent m227 : 16|16@1- (0.1,0) [-3276.8|3276.7] "A" Vector__XXX
 SG_ BMS_a227_dcChargeCurrentRequest m227 : 32|16@1- (0.1,0) [-3276.8|3276.7] "A" Vector__XXX
 SG_ BMS_a256_minBrickT m256 : 16|8@1- (0.5,24) [-40|87.5] "C" Vector__XXX
 SG_ BMS_a256_maxBrickT m256 : 24|8@1- (0.5,24) [-40|87.5] "C" Vector__XXX
 SG_ BMS_a256_minBrickV m256 : 32|8@1+ (0.01,2) [2|4.55] "V" Vector__XXX
 SG_ BMS_a256_maxBrickV m256 : 40|8@1+ (0.01,2) [2|4.55] "V" Vector__XXX
 SG_ BMS_a256_packSoe m256 : 48|8@1+ (0.393700778484,0) [0|100.393698513] "%" Vector__XXX
 SG_ BMS_a256_SOC m256 : 56|8@1+ (0.05,0) [0|12.75] "%" Vector__XXX

BO_TX_BU_ 1951 : GTW;
BO_TX_BU_ 909 : APP;
BO_TX_BU_ 1018 : APP;
BO_TX_BU_ 1056 : APS;
BO_TX_BU_ 1343 : BMS;

CM_ "Tesla Model 3 / Model Y CAN bus database; bus VEH (vehicle CAN); firmware 2026.26.6.5. Decoded CAN signal definitions (layout, scaling, units, value tables).";
CM_ BU_ APP "Driver assistance computer (primary)";
CM_ BU_ APS "Driver assistance computer (secondary)";
CM_ BU_ BMS "High-voltage battery management system";
CM_ BU_ CC "Charge cable controller";
CM_ BU_ CMP "A/C compressor";
CM_ BU_ CMPD "CMPD ECU";
CM_ BU_ CP "Charge port controller";
CM_ BU_ DAS "Driver assistance computer";
CM_ BU_ DI "Drive inverter";
CM_ BU_ DIF "Front drive inverter";
CM_ BU_ DIR "Rear drive inverter";
CM_ BU_ EPBL "Left electric parking brake";
CM_ BU_ EPBR "Right electric parking brake";
CM_ BU_ EVSE "EVSE ECU";
CM_ BU_ FC "FC ECU";
CM_ BU_ GTW "Gateway";
CM_ BU_ HCML "HCML ECU";
CM_ BU_ HCMR "HCMR ECU";
CM_ BU_ HVP "High-voltage processor (pack contactor and isolation controller)";
CM_ BU_ ICR "ICR ECU";
CM_ BU_ PCS "Power conversion system (on-board charger and DC-DC converter)";
CM_ BU_ PCS2 "PCS2 ECU";
CM_ BU_ PLG "PLG ECU";
CM_ BU_ PM "PM ECU";
CM_ BU_ PMF "PMF ECU";
CM_ BU_ PMR "PMR ECU";
CM_ BU_ PTC "Cabin heater";
CM_ BU_ SCCM "Steering column control module";
CM_ BU_ SCM "SCM ECU";
CM_ BU_ SCS "SCS ECU";
CM_ BU_ SDCR "SDCR ECU";
CM_ BU_ TAS "Air suspension controller";
CM_ BU_ UMC "UMC ECU";
CM_ BU_ V2G "V2G ECU";
CM_ BU_ VC "VC ECU";
CM_ BU_ VCBATT "VCBATT ECU";
CM_ BU_ VCBATT0 "VCBATT0 ECU";
CM_ BU_ VCBATT1 "VCBATT1 ECU";
CM_ BU_ VCBATT2 "VCBATT2 ECU";
CM_ BU_ VCFRONT "Front body controller";
CM_ BU_ VCFRONT1 "VCFRONT1 ECU";
CM_ BU_ VCFRONT2 "VCFRONT2 ECU";
CM_ BU_ VCLEFT "Left body controller";
CM_ BU_ VCRIGHT "Right body controller";
CM_ BU_ VCSEAT2L "VCSEAT2L ECU";
CM_ BU_ VCSEAT2R "VCSEAT2R ECU";
CM_ BU_ VCSEC "Vehicle security controller";
CM_ BO_ 1951 "Audio amplifier message: audio visualizer; forwarded onto this bus by the gateway; frame length from the layout, not yet observed on a vehicle bus";
CM_ SG_ 1951 ADSP_audioVisualizerBrightness "Audio amplifier: audio visualizer brightness";
CM_ BO_ 909 "Driver assistance computer (primary) message: VC info message; frame length observed on a vehicle bus";
CM_ SG_ 909 APP_inTunnel "Driver assistance computer (primary): in tunnel; raw 0 = signal not available (SNA)";
CM_ SG_ 909 APP_windshieldHeaterOnReason "Reports the reason why Autopilot (AP) is turning windshield heater on; raw 0 = signal not available (SNA)";
CM_ SG_ 909 APP_selfieCameraBlocked "Indicates if the selfie camera is currently blocked, or if this selfie camera model doesn't report lux; raw 0 = signal not available (SNA)";
CM_ SG_ 909 APP_selfieCameraLUX "Reports lux reading. Note that selfie camera lux is not currently calibrated against other cameras so the range is different; raw 255 = signal not available (SNA)";
CM_ SG_ 909 APP_sceneTagClearlyRaining "Indicates if the vision scene tag is clearly raining; raw 0 = signal not available (SNA)";
CM_ SG_ 909 APP_sceneTagFog "Indicates if the vision scene tag detects fog; raw 0 = signal not available (SNA)";
CM_ SG_ 909 APP_sceneTagFullyBlocked "Indicates if the vision scene tag detects a fully blocked view; raw 0 = signal not available (SNA)";
CM_ SG_ 909 APP_sceneTagIndoors "Indicates if the vision scene tag detects an indoor environment; raw 0 = signal not available (SNA)";
CM_ SG_ 909 APP_sceneTagLensFlare "Indicates if the vision scene tag detects lens flare; raw 0 = signal not available (SNA)";
CM_ SG_ 909 APP_sceneTagRaining "Indicates if the vision scene tag detects raining conditions; raw 0 = signal not available (SNA)";
CM_ SG_ 909 APP_sceneTagSevereWeather "Indicates if the vision scene tag detects severe weather conditions; raw 0 = signal not available (SNA)";
CM_ SG_ 909 APP_sceneTagSnowing "Indicates if the vision scene tag detects snowing conditions; raw 0 = signal not available (SNA)";
CM_ SG_ 909 APP_sceneTagSnowyRoad "Indicates if the vision scene tag detects snowy road conditions; raw 0 = signal not available (SNA)";
CM_ SG_ 909 APP_sceneTagSunGlare "Indicates if the vision scene tag detects sun glare conditions; raw 0 = signal not available (SNA)";
CM_ SG_ 909 APP_sceneTagTunnel "Indicates if the vision scene tag detects a tunnel environment; raw 0 = signal not available (SNA)";
CM_ SG_ 909 APP_sceneTagWetRoad "Indicates if the vision scene tag detects wet road conditions; raw 0 = signal not available (SNA)";
CM_ SG_ 909 APP_fisheyeInPathVisibility "Driver assistance computer (primary): fisheye in path visibility; raw 0 = signal not available (SNA)";
CM_ SG_ 909 APP_fisheyeOverallVisibility "Driver assistance computer (primary): fisheye overall visibility; raw 0 = signal not available (SNA)";
CM_ SG_ 909 APP_mainInPathVisibility "Driver assistance computer (primary): main in path visibility; raw 0 = signal not available (SNA)";
CM_ SG_ 909 APP_mainOverallVisibility "Driver assistance computer (primary): main overall visibility; raw 0 = signal not available (SNA)";
CM_ SG_ 909 APP_narrowInPathVisibility "Driver assistance computer (primary): narrow in path visibility; raw 0 = signal not available (SNA)";
CM_ SG_ 909 APP_narrowOverallVisibility "Driver assistance computer (primary): narrow overall visibility; raw 0 = signal not available (SNA)";
CM_ SG_ 909 APP_frontCamOcclusionType "Reports the current type of what is obstructing the front camera vision.";
CM_ BO_ 1018 "Driver assistance computer (primary) message: camera lux; frame length observed on a vehicle bus";
CM_ SG_ 1018 APP_mainCameraLUX "Amount of illuminance seen by the main camera; raw 255 = signal not available (SNA)";
CM_ SG_ 1018 APP_narrowCameraLUX "Driver assistance computer (primary): narrow camera LUX; raw 255 = signal not available (SNA)";
CM_ SG_ 1018 APP_fisheyeCameraLUX "Driver assistance computer (primary): fisheye camera LUX; raw 255 = signal not available (SNA)";
CM_ SG_ 1018 APP_lRepeatCameraLUX "Driver assistance computer (primary): l repeat camera LUX; raw 255 = signal not available (SNA)";
CM_ SG_ 1018 APP_rRepeatCameraLUX "Driver assistance computer (primary): r repeat camera LUX; raw 255 = signal not available (SNA)";
CM_ SG_ 1018 APP_lPillarCameraLUX "Driver assistance computer (primary): l pillar camera LUX; raw 255 = signal not available (SNA)";
CM_ SG_ 1018 APP_rPillarCameraLUX "Driver assistance computer (primary): r pillar camera LUX; raw 255 = signal not available (SNA)";
CM_ SG_ 1018 APP_backupCameraLUX "Driver assistance computer (primary): backup camera LUX; raw 255 = signal not available (SNA)";
CM_ BO_ 1056 "Driver assistance computer (secondary) message: state; frame length observed on a vehicle bus";
CM_ SG_ 1056 APS_primaryTurbo "Which of the two Turbos currently holds the primary role.";
CM_ SG_ 1056 APS_A_arbState "The state of the arbitration state machine of Turbo A.";
CM_ SG_ 1056 APS_A_powerState "The state of the power state machine of Turbo A.";
CM_ SG_ 1056 APS_A_sleepState "The state of the sleep state machine of Turbo A.";
CM_ SG_ 1056 APS_A_resetState "The state of the reset state machine of Turbo A.";
CM_ SG_ 1056 APS_A_faultState "The state of the fault state machine of Turbo A.";
CM_ SG_ 1056 APS_secondaryTurbo "Which of the two Turbos currently holds the secondary role.";
CM_ SG_ 1056 APS_B_arbState "The state of the arbitration state machine of Turbo B.";
CM_ SG_ 1056 APS_B_powerState "The state of the power state machine of Turbo B.";
CM_ SG_ 1056 APS_B_sleepState "The state of the sleep state machine of Turbo B.";
CM_ SG_ 1056 APS_B_resetState "The state of the reset state machine of Turbo B.";
CM_ SG_ 1056 APS_B_faultState "The state of the fault state machine of Turbo B.";
CM_ SG_ 1056 APS_A_autosteerMonitorState "Driver assistance computer (secondary): a autosteer monitor state";
CM_ SG_ 1056 APS_B_autosteerMonitorState "Driver assistance computer (secondary): b autosteer monitor state";
CM_ SG_ 1056 APS_eplannerState "Driver assistance computer (secondary): eplanner state";
CM_ SG_ 1056 APS_A_faultInduced "Driver assistance computer (secondary): a fault induced";
CM_ SG_ 1056 APS_B_faultInduced "Driver assistance computer (secondary): b fault induced";
CM_ SG_ 1056 APS_stateCounter "Driver assistance computer (secondary): state counter";
CM_ BO_ 1343 "High-voltage battery management system message: alert log; frame length from the layout, not yet observed on a vehicle bus";
CM_ SG_ 1343 BMS_alertID "High-voltage battery management system: alert ID; raw 127 = signal not available (SNA)";
CM_ SG_ 1343 BMS_alertSet "High-voltage battery management system: alert set";
CM_ SG_ 1343 BMS_a001_gatewayPackEnergy "High-voltage battery management system: a001 gateway pack energy";
CM_ SG_ 1343 BMS_a001_expectedPackEnergy "High-voltage battery management system: a001 expected pack energy";
CM_ SG_ 1343 BMS_a002_gatewayPackPerformanceD "High-voltage battery management system: a002 gateway pack performance deviation";
CM_ SG_ 1343 BMS_a002_expectedPackPerformance "High-voltage battery management system: a002 expected pack performance deviation";
CM_ SG_ 1343 BMS_a002_bmsPackMass "High-voltage battery management system: a002 bms pack mass";
CM_ SG_ 1343 BMS_a003_calBlockData_0 "High-voltage battery management system: a003 cal block data 0";
CM_ SG_ 1343 BMS_a017_packCurrent "High-voltage battery management system: a017 pack current";
CM_ SG_ 1343 BMS_a017_ovBrickVID "High-voltage battery management system: a017 ov brick VID";
CM_ SG_ 1343 BMS_a017_ovBrickV "High-voltage battery management system: a017 ov brick v";
CM_ SG_ 1343 BMS_a018_packCurrent "High-voltage battery management system: a018 pack current";
CM_ SG_ 1343 BMS_a018_uvBrickVID "High-voltage battery management system: a018 uv brick VID";
CM_ SG_ 1343 BMS_a018_uvBrickV "High-voltage battery management system: a018 uv brick v";
CM_ SG_ 1343 BMS_a019_coolantInletT "High-voltage battery management system: a019 coolant inlet t";
CM_ SG_ 1343 BMS_a019_activeCoolingTarget "High-voltage battery management system: a019 active cooling target";
CM_ SG_ 1343 BMS_a019_maxBrickT "High-voltage battery management system: a019 max brick t";
CM_ SG_ 1343 BMS_a019_maxBrickTID "High-voltage battery management system: a019 max brick TID";
CM_ SG_ 1343 BMS_a021_chargeViolation "High-voltage battery management system: a021 charge violation";
CM_ SG_ 1343 BMS_a021_currentLimit "High-voltage battery management system: a021 current limit";
CM_ SG_ 1343 BMS_a021_packCurrent "High-voltage battery management system: a021 pack current";
CM_ SG_ 1343 BMS_a022_chargeAccumulatorViolat "High-voltage battery management system: a022 charge accumulator violation";
CM_ SG_ 1343 BMS_a022_chargeAccumulatorValue "High-voltage battery management system: a022 charge accumulator value";
CM_ SG_ 1343 BMS_a022_chargeAccumulatorLimit "High-voltage battery management system: a022 charge accumulator limit";
CM_ SG_ 1343 BMS_a023_ovStackDeviceID "High-voltage battery management system: a023 ov stack device ID";
CM_ SG_ 1343 BMS_a023_ovStackV "High-voltage battery management system: a023 ov stack v";
CM_ SG_ 1343 BMS_a024_brickID "High-voltage battery management system: a024 brick ID";
CM_ SG_ 1343 BMS_a024_deltaV "High-voltage battery management system: a024 delta v";
CM_ SG_ 1343 BMS_a024_avgDvPrev "High-voltage battery management system: a024 avg dv prev";
CM_ SG_ 1343 BMS_a024_packCurrent "High-voltage battery management system: a024 pack current";
CM_ SG_ 1343 BMS_a027_swIsolationCount "High-voltage battery management system: a027 sw isolation count";
CM_ SG_ 1343 BMS_a030_worstBrickID "High-voltage battery management system: a030 worst brick ID";
CM_ SG_ 1343 BMS_a030_maxBrickImpedance "High-voltage battery management system: a030 max brick impedance";
CM_ SG_ 1343 BMS_a030_maxNormalizedImpedanceD "High-voltage battery management system: a030 max normalized impedance dev";
CM_ SG_ 1343 BMS_a030_faultThreshold "High-voltage battery management system: a030 fault threshold";
CM_ SG_ 1343 BMS_a030_numBricks "High-voltage battery management system: a030 num bricks";
CM_ SG_ 1343 BMS_a030_worstBrickSoc "High-voltage battery management system: a030 worst brick soc";
CM_ SG_ 1343 BMS_a035_isoR "High-voltage battery management system: a035 iso r";
CM_ SG_ 1343 BMS_a035_mode "High-voltage battery management system: a035 mode";
CM_ SG_ 1343 BMS_a035_activeSideVNoR "High-voltage battery management system: a035 active side v no r";
CM_ SG_ 1343 BMS_a035_activeSideVWithR "High-voltage battery management system: a035 active side v with r";
CM_ SG_ 1343 BMS_a035_passiveSideVNoR "High-voltage battery management system: a035 passive side v no r";
CM_ SG_ 1343 BMS_a035_passiveSideVWithR "High-voltage battery management system: a035 passive side v with r";
CM_ SG_ 1343 BMS_a039_dcLinkVoltage "High-voltage battery management system: a039 dc link voltage";
CM_ SG_ 1343 BMS_a039_packVoltage "High-voltage battery management system: a039 pack voltage";
CM_ SG_ 1343 BMS_a039_packContactorState "High-voltage battery management system: a039 pack contactor state; raw 0 = signal not available (SNA)";
CM_ SG_ 1343 BMS_a039_packCurrent "High-voltage battery management system: a039 pack current";
CM_ SG_ 1343 BMS_a039_maxBrickV "High-voltage battery management system: a039 max brick v";
CM_ SG_ 1343 BMS_a039_state "High-voltage battery management system: a039 state; raw 9 = signal not available (SNA)";
CM_ SG_ 1343 BMS_a041_resetType "High-voltage battery management system: a041 reset type";
CM_ SG_ 1343 BMS_a050_MIA_numBadReadings "High-voltage battery management system: a050 MIA num bad readings";
CM_ SG_ 1343 BMS_a050_MIA_numSnaReadings "High-voltage battery management system: a050 MIA num sna readings";
CM_ SG_ 1343 BMS_a050_MIA_brickId "High-voltage battery management system: a050 MIA brick id";
CM_ SG_ 1343 BMS_a051_hvp1V5Ref "High-voltage battery management system: a051 hvp1 V5 ref";
CM_ SG_ 1343 BMS_a051_hvp3V0Ref "High-voltage battery management system: a051 hvp3 V0 ref";
CM_ SG_ 1343 BMS_a051_bms3V0Ref "High-voltage battery management system: a051 bms3 V0 ref";
CM_ SG_ 1343 BMS_a059_sumBrickVoltages "High-voltage battery management system: a059 sum brick voltages";
CM_ SG_ 1343 BMS_a059_packVoltage "High-voltage battery management system: a059 pack voltage";
CM_ SG_ 1343 BMS_a062_state "High-voltage battery management system: a062 state; raw 9 = signal not available (SNA)";
CM_ SG_ 1343 BMS_a062_minBrickVId "High-voltage battery management system: a062 min brick v id";
CM_ SG_ 1343 BMS_a062_minBrickVoltage "High-voltage battery management system: a062 min brick voltage";
CM_ SG_ 1343 BMS_a062_maxBrickVId "High-voltage battery management system: a062 max brick v id";
CM_ SG_ 1343 BMS_a062_maxBrickVoltage "High-voltage battery management system: a062 max brick voltage";
CM_ SG_ 1343 BMS_a063_cpFaultInV "High-voltage battery management system: a063 cp fault in v";
CM_ SG_ 1343 BMS_a064_minBrickSOCID "High-voltage battery management system: a064 min brick SOCID";
CM_ SG_ 1343 BMS_a064_minBrickSOC "High-voltage battery management system: a064 min brick SOC";
CM_ SG_ 1343 BMS_a064_maxBrickSOCID "High-voltage battery management system: a064 max brick SOCID";
CM_ SG_ 1343 BMS_a064_maxBrickSOC "High-voltage battery management system: a064 max brick SOC";
CM_ SG_ 1343 BMS_a064_avgBrickSOC "High-voltage battery management system: a064 avg brick SOC";
CM_ SG_ 1343 BMS_a065_minBrickCacId "High-voltage battery management system: a065 min brick cac id";
CM_ SG_ 1343 BMS_a065_minBrickCac "High-voltage battery management system: a065 min brick cac";
CM_ SG_ 1343 BMS_a065_avgBrickCac "High-voltage battery management system: a065 avg brick cac";
CM_ SG_ 1343 BMS_a065_modCacImbalancePct "High-voltage battery management system: a065 mod cac imbalance pct";
CM_ SG_ 1343 BMS_a066_minBrickSocId "High-voltage battery management system: a066 min brick soc id";
CM_ SG_ 1343 BMS_a066_minBrickSocByOcvMax "High-voltage battery management system: a066 min brick soc by ocv max";
CM_ SG_ 1343 BMS_a066_maxBrickSocId "High-voltage battery management system: a066 max brick soc id";
CM_ SG_ 1343 BMS_a066_maxBrickSocByOcvMin "High-voltage battery management system: a066 max brick soc by ocv min";
CM_ SG_ 1343 BMS_a066_maxBrickSoc "High-voltage battery management system: a066 max brick soc";
CM_ SG_ 1343 BMS_a066_avgBrickSoc "High-voltage battery management system: a066 avg brick soc";
CM_ SG_ 1343 BMS_a067_minBrickCacId "High-voltage battery management system: a067 min brick cac id";
CM_ SG_ 1343 BMS_a067_minBrickCac "High-voltage battery management system: a067 min brick cac";
CM_ SG_ 1343 BMS_a067_avgBrickCac "High-voltage battery management system: a067 avg brick cac";
CM_ SG_ 1343 BMS_a067_modCacImbalancePct "High-voltage battery management system: a067 mod cac imbalance pct";
CM_ SG_ 1343 BMS_a068_minBrickCacId "High-voltage battery management system: a068 min brick cac id";
CM_ SG_ 1343 BMS_a068_minBrickCac "High-voltage battery management system: a068 min brick cac";
CM_ SG_ 1343 BMS_a068_avgBrickCac "High-voltage battery management system: a068 avg brick cac";
CM_ SG_ 1343 BMS_a068_modCacImbalancePct "High-voltage battery management system: a068 mod cac imbalance pct";
CM_ SG_ 1343 BMS_a069_dischargePowerPackVolta "High-voltage battery management system: a069 discharge power pack voltage floor";
CM_ SG_ 1343 BMS_a069_dischargePowerBrickVolt "High-voltage battery management system: a069 discharge power brick voltage floor";
CM_ SG_ 1343 BMS_a069_SOC "High-voltage battery management system: a069 SOC";
CM_ SG_ 1343 BMS_a069_minBrickT "High-voltage battery management system: a069 min brick t";
CM_ SG_ 1343 BMS_a069_minBrickVLimit "High-voltage battery management system: a069 min brick v limit";
CM_ SG_ 1343 BMS_a069_minBrickV "High-voltage battery management system: a069 min brick v";
CM_ SG_ 1343 BMS_a070_state "High-voltage battery management system: a070 state; raw 9 = signal not available (SNA)";
CM_ SG_ 1343 BMS_a070_minBrickVId "High-voltage battery management system: a070 min brick v id";
CM_ SG_ 1343 BMS_a070_minBrickVoltage "High-voltage battery management system: a070 min brick voltage";
CM_ SG_ 1343 BMS_a070_maxBrickVId "High-voltage battery management system: a070 max brick v id";
CM_ SG_ 1343 BMS_a070_maxBrickVoltage "High-voltage battery management system: a070 max brick voltage";
CM_ SG_ 1343 BMS_a071_stateRequest "High-voltage battery management system: a071 state request; raw 9 = signal not available (SNA)";
CM_ SG_ 1343 BMS_a071_state "High-voltage battery management system: a071 state; raw 9 = signal not available (SNA)";
CM_ SG_ 1343 BMS_a071_transitionAlertId "High-voltage battery management system: a071 transition alert id";
CM_ SG_ 1343 BMS_a074_maxBrickVTarget "High-voltage battery management system: a074 max brick v target";
CM_ SG_ 1343 BMS_a074_maxBrickV "High-voltage battery management system: a074 max brick v";
CM_ SG_ 1343 BMS_a075_chargeType "High-voltage battery management system: a075 charge type";
CM_ SG_ 1343 BMS_a076_netAh "High-voltage battery management system: a076 net ah";
CM_ SG_ 1343 BMS_a076_tetheringActive "High-voltage battery management system: a076 tethering active";
CM_ SG_ 1343 BMS_a077_chargeErrType "High-voltage battery management system: a077 charge err type";
CM_ SG_ 1343 BMS_a077_maxBrickVTarget "High-voltage battery management system: a077 max brick v target";
CM_ SG_ 1343 BMS_a077_maxBrickV "High-voltage battery management system: a077 max brick v";
CM_ SG_ 1343 BMS_a077_packTargetCurrent "High-voltage battery management system: a077 pack target current";
CM_ SG_ 1343 BMS_a077_packCurrent "High-voltage battery management system: a077 pack current";
CM_ SG_ 1343 BMS_a078_peakDchInChg "High-voltage battery management system: a078 peak dch in chg; raw 32768 = signal not available (SNA)";
CM_ SG_ 1343 BMS_a079_maxBrickVTarget "High-voltage battery management system: a079 max brick v target";
CM_ SG_ 1343 BMS_a079_maxBrickV "High-voltage battery management system: a079 max brick v";
CM_ SG_ 1343 BMS_a081_stateRequest "High-voltage battery management system: a081 state request; raw 9 = signal not available (SNA)";
CM_ SG_ 1343 BMS_a081_firstBlockingAlertId "High-voltage battery management system: a081 first blocking alert id; raw 127 = signal not available (SNA)";
CM_ SG_ 1343 BMS_a081_secondBlockingAlertId "High-voltage battery management system: a081 second blocking alert id; raw 127 = signal not available (SNA)";
CM_ SG_ 1343 BMS_a081_thirdBlockingAlertId "High-voltage battery management system: a081 third blocking alert id; raw 127 = signal not available (SNA)";
CM_ SG_ 1343 BMS_a081_fourthBlockingAlertId "High-voltage battery management system: a081 fourth blocking alert id; raw 127 = signal not available (SNA)";
CM_ SG_ 1343 BMS_a081_totalAlertCount "High-voltage battery management system: a081 total alert count";
CM_ SG_ 1343 BMS_a082_stateRequest "High-voltage battery management system: a082 state request; raw 9 = signal not available (SNA)";
CM_ SG_ 1343 BMS_a082_firstAlertId "High-voltage battery management system: a082 first alert id; raw 127 = signal not available (SNA)";
CM_ SG_ 1343 BMS_a082_secondAlertId "High-voltage battery management system: a082 second alert id; raw 127 = signal not available (SNA)";
CM_ SG_ 1343 BMS_a082_thirdAlertId "High-voltage battery management system: a082 third alert id; raw 127 = signal not available (SNA)";
CM_ SG_ 1343 BMS_a082_fourthAlertId "High-voltage battery management system: a082 fourth alert id; raw 127 = signal not available (SNA)";
CM_ SG_ 1343 BMS_a082_totalAlertCount "High-voltage battery management system: a082 total alert count";
CM_ SG_ 1343 BMS_a083_packContactorRequest "High-voltage battery management system: a083 pack contactor request; raw 0 = signal not available (SNA)";
CM_ SG_ 1343 BMS_a085_packContactorSetStatePr "High-voltage battery management system: a085 pack contactor set state prev; raw 0 = signal not available (SNA)";
CM_ SG_ 1343 BMS_a085_packContactorSetState "High-voltage battery management system: a085 pack contactor set state; raw 0 = signal not available (SNA)";
CM_ SG_ 1343 BMS_a085_packContactorSetRe_0001 "High-voltage battery management system: a085 pack contactor set request prev; raw 0 = signal not available (SNA)";
CM_ SG_ 1343 BMS_a085_packContactorSetRequest "High-voltage battery management system: a085 pack contactor set request; raw 0 = signal not available (SNA)";
CM_ SG_ 1343 BMS_a086_fcContactorSetStatePrev "High-voltage battery management system: a086 fc contactor set state prev; raw 0 = signal not available (SNA)";
CM_ SG_ 1343 BMS_a086_fcContactorSetState "High-voltage battery management system: a086 fc contactor set state; raw 0 = signal not available (SNA)";
CM_ SG_ 1343 BMS_a086_fcContactorSetRequestPr "High-voltage battery management system: a086 fc contactor set request prev; raw 0 = signal not available (SNA)";
CM_ SG_ 1343 BMS_a086_fcContactorSetRequest "High-voltage battery management system: a086 fc contactor set request; raw 0 = signal not available (SNA)";
CM_ SG_ 1343 BMS_a087_blockingAlert "High-voltage battery management system: a087 blocking alert; raw 127 = signal not available (SNA)";
CM_ SG_ 1343 BMS_a090_GTWmessageTout "High-voltage battery management system: a090 GT wmessage tout";
CM_ SG_ 1343 BMS_a098_breakLocationA "High-voltage battery management system: a098 break location a";
CM_ SG_ 1343 BMS_a098_bmbCommStatusTypeA "High-voltage battery management system: a098 bmb comm status type a";
CM_ SG_ 1343 BMS_a098_breakLocationB "High-voltage battery management system: a098 break location b";
CM_ SG_ 1343 BMS_a098_bmbCommStatusTypeB "High-voltage battery management system: a098 bmb comm status type b";
CM_ SG_ 1343 BMS_a098_alertFromHvp "High-voltage battery management system: a098 alert from hvp";
CM_ SG_ 1343 BMS_a099_breakLocationA "High-voltage battery management system: a099 break location a";
CM_ SG_ 1343 BMS_a099_bmbCommStatusTypeA "High-voltage battery management system: a099 bmb comm status type a";
CM_ SG_ 1343 BMS_a099_breakLocationB "High-voltage battery management system: a099 break location b";
CM_ SG_ 1343 BMS_a099_bmbCommStatusTypeB "High-voltage battery management system: a099 bmb comm status type b";
CM_ SG_ 1343 BMS_a099_bmbChainBreakType "High-voltage battery management system: a099 bmb chain break type";
CM_ SG_ 1343 BMS_a099_alertFromHvp "High-voltage battery management system: a099 alert from hvp";
CM_ SG_ 1343 BMS_a100_testTrigger "High-voltage battery management system: a100 test trigger";
CM_ SG_ 1343 BMS_a100_setFromNvm "High-voltage battery management system: a100 set from nvm";
CM_ SG_ 1343 BMS_a100_voltageDeviation "High-voltage battery management system: a100 voltage deviation";
CM_ SG_ 1343 BMS_a100_voltageLoss "High-voltage battery management system: a100 voltage loss";
CM_ SG_ 1343 BMS_a105_tSenseFailedModule1 "High-voltage battery management system: a105 t sense failed module1";
CM_ SG_ 1343 BMS_a105_avgBrickTModule1 "High-voltage battery management system: a105 avg brick t module1";
CM_ SG_ 1343 BMS_a105_tSenseFailedModule2 "High-voltage battery management system: a105 t sense failed module2";
CM_ SG_ 1343 BMS_a105_avgBrickTModule2 "High-voltage battery management system: a105 avg brick t module2";
CM_ SG_ 1343 BMS_a105_tSenseFailedModule3 "High-voltage battery management system: a105 t sense failed module3";
CM_ SG_ 1343 BMS_a105_avgBrickTModule3 "High-voltage battery management system: a105 avg brick t module3";
CM_ SG_ 1343 BMS_a105_tSenseFailedModule4 "High-voltage battery management system: a105 t sense failed module4";
CM_ SG_ 1343 BMS_a105_avgBrickTModule4 "High-voltage battery management system: a105 avg brick t module4";
CM_ SG_ 1343 BMS_a105_inletTemp "High-voltage battery management system: a105 inlet temp";
CM_ SG_ 1343 BMS_a106_minBrickT "High-voltage battery management system: a106 min brick t";
CM_ SG_ 1343 BMS_a106_maxBrickT "High-voltage battery management system: a106 max brick t";
CM_ SG_ 1343 BMS_a106_avgBrickT "High-voltage battery management system: a106 avg brick t";
CM_ SG_ 1343 BMS_a106_inletTemp "High-voltage battery management system: a106 inlet temp";
CM_ SG_ 1343 BMS_a107_MIA_numBadReadings "High-voltage battery management system: a107 MIA num bad readings";
CM_ SG_ 1343 BMS_a107_MIA_numSnaReadings "High-voltage battery management system: a107 MIA num sna readings";
CM_ SG_ 1343 BMS_a107_MIA_stackId "High-voltage battery management system: a107 MIA stack id";
CM_ SG_ 1343 BMS_a109_muteMask "High-voltage battery management system: a109 mute mask";
CM_ SG_ 1343 BMS_a109_packInBleed "High-voltage battery management system: a109 pack in bleed";
CM_ SG_ 1343 BMS_a117_brickID "High-voltage battery management system: a117 brick ID";
CM_ SG_ 1343 BMS_a117_brickSoc2 "High-voltage battery management system: a117 brick soc2; raw 1023 = signal not available (SNA)";
CM_ SG_ 1343 BMS_a117_dSocAlertThreshold "High-voltage battery management system: a117 d soc alert threshold";
CM_ SG_ 1343 BMS_a117_dSocAlpha "High-voltage battery management system: a117 d soc alpha; raw 4095 = signal not available (SNA)";
CM_ SG_ 1343 BMS_a118_brickID "High-voltage battery management system: a118 brick ID";
CM_ SG_ 1343 BMS_a118_brickSoc2 "High-voltage battery management system: a118 brick soc2; raw 1023 = signal not available (SNA)";
CM_ SG_ 1343 BMS_a118_dSocAlertThreshold "High-voltage battery management system: a118 d soc alert threshold";
CM_ SG_ 1343 BMS_a118_dSocAlpha "High-voltage battery management system: a118 d soc alpha; raw 4095 = signal not available (SNA)";
CM_ SG_ 1343 BMS_a122_thermistorID "High-voltage battery management system: a122 thermistor ID";
CM_ SG_ 1343 BMS_a122_irrationalThermistorTem "High-voltage battery management system: a122 irrational thermistor temp";
CM_ SG_ 1343 BMS_a122_averageRawThermistorTem "High-voltage battery management system: a122 average raw thermistor temp";
CM_ SG_ 1343 BMS_a122_minRawThermistorTemp "High-voltage battery management system: a122 min raw thermistor temp";
CM_ SG_ 1343 BMS_a122_maxRawThermistorTemp "High-voltage battery management system: a122 max raw thermistor temp";
CM_ SG_ 1343 BMS_a122_numValidThermistors "High-voltage battery management system: a122 num valid thermistors";
CM_ SG_ 1343 BMS_a123_packPlus "High-voltage battery management system: a123 pack plus";
CM_ SG_ 1343 BMS_a123_isoR "High-voltage battery management system: a123 iso r";
CM_ SG_ 1343 BMS_a123_packMinus "High-voltage battery management system: a123 pack minus";
CM_ SG_ 1343 BMS_a129_brickID "High-voltage battery management system: a129 brick ID";
CM_ SG_ 1343 BMS_a129_deltaV "High-voltage battery management system: a129 delta v";
CM_ SG_ 1343 BMS_a129_retryCount "High-voltage battery management system: a129 retry count";
CM_ SG_ 1343 BMS_a131_brickID "High-voltage battery management system: a131 brick ID";
CM_ SG_ 1343 BMS_a131_deltaV "High-voltage battery management system: a131 delta v";
CM_ SG_ 1343 BMS_a131_retryCount "High-voltage battery management system: a131 retry count";
CM_ SG_ 1343 BMS_a132_multiVendorErrorMask "High-voltage battery management system: a132 multi vendor error mask";
CM_ SG_ 1343 BMS_a135_bmbDiagnosticsType "High-voltage battery management system: a135 bmb diagnostics type";
CM_ SG_ 1343 BMS_a135_bmbDeviceId "High-voltage battery management system: a135 bmb device id";
CM_ SG_ 1343 BMS_a135_readCVA "High-voltage battery management system: a135 read CVA";
CM_ SG_ 1343 BMS_a135_readCVB "High-voltage battery management system: a135 read CVB";
CM_ SG_ 1343 BMS_a135_readCVC "High-voltage battery management system: a135 read CVC";
CM_ SG_ 1343 BMS_a135_readCVD "High-voltage battery management system: a135 read CVD";
CM_ SG_ 1343 BMS_a135_readCVE "High-voltage battery management system: a135 read CVE";
CM_ SG_ 1343 BMS_a135_readCVF "High-voltage battery management system: a135 read CVF";
CM_ SG_ 1343 BMS_a135_readSNA "High-voltage battery management system: a135 read SNA";
CM_ SG_ 1343 BMS_a135_readSNB "High-voltage battery management system: a135 read SNB";
CM_ SG_ 1343 BMS_a135_readSNC "High-voltage battery management system: a135 read SNC";
CM_ SG_ 1343 BMS_a135_readSND "High-voltage battery management system: a135 read SND";
CM_ SG_ 1343 BMS_a135_readSNE "High-voltage battery management system: a135 read SNE";
CM_ SG_ 1343 BMS_a135_readSNF "High-voltage battery management system: a135 read SNF";
CM_ SG_ 1343 BMS_a135_readAUXA "High-voltage battery management system: a135 read AUXA";
CM_ SG_ 1343 BMS_a135_readAUXB "High-voltage battery management system: a135 read AUXB";
CM_ SG_ 1343 BMS_a135_readSTAT "High-voltage battery management system: a135 read STAT";
CM_ SG_ 1343 BMS_a136_maxBrickTID "High-voltage battery management system: a136 max brick TID";
CM_ SG_ 1343 BMS_a136_coolantInletT "High-voltage battery management system: a136 coolant inlet t";
CM_ SG_ 1343 BMS_a136_activeCoolingTarget "High-voltage battery management system: a136 active cooling target";
CM_ SG_ 1343 BMS_a136_maxBrickT "High-voltage battery management system: a136 max brick t";
CM_ SG_ 1343 BMS_a139_packVoltage "High-voltage battery management system: a139 pack voltage";
CM_ SG_ 1343 BMS_a139_dcLinkVoltage "High-voltage battery management system: a139 dc link voltage";
CM_ SG_ 1343 BMS_a140_bmbDeviceMask "High-voltage battery management system: a140 bmb device mask";
CM_ SG_ 1343 BMS_a140_faultType "High-voltage battery management system: a140 fault type";
CM_ SG_ 1343 BMS_a142_isolationResistance "High-voltage battery management system: a142 isolation resistance";
CM_ SG_ 1343 BMS_a142_mode "High-voltage battery management system: a142 mode";
CM_ SG_ 1343 BMS_a143_initialSoc "High-voltage battery management system: a143 initial soc";
CM_ SG_ 1343 BMS_a143_endingSoc "High-voltage battery management system: a143 ending soc";
CM_ SG_ 1343 BMS_a143_deltaAh "High-voltage battery management system: a143 delta ah";
CM_ SG_ 1343 BMS_a143_cacChangeBrickID "High-voltage battery management system: a143 cac change brick ID";
CM_ SG_ 1343 BMS_a143_cacUpdateError "High-voltage battery management system: a143 cac update error";
CM_ SG_ 1343 BMS_a144_HVP_major_version "High-voltage battery management system: a144 HVP major version";
CM_ SG_ 1343 BMS_a144_HVP_minor_version "High-voltage battery management system: a144 HVP minor version";
CM_ SG_ 1343 BMS_a144_BMS_minor_version "High-voltage battery management system: a144 BMS minor version";
CM_ SG_ 1343 BMS_a145_maxSocChange "High-voltage battery management system: a145 max soc change";
CM_ SG_ 1343 BMS_a145_maxSocChangeBrickID "High-voltage battery management system: a145 max soc change brick ID";
CM_ SG_ 1343 BMS_a145_numBricksChanged "High-voltage battery management system: a145 num bricks changed";
CM_ SG_ 1343 BMS_a145_brickChangeHystRatio "High-voltage battery management system: a145 brick change hyst ratio; raw 1023 = signal not available (SNA)";
CM_ SG_ 1343 BMS_a146_maxBrickV "High-voltage battery management system: a146 max brick v";
CM_ SG_ 1343 BMS_a146_state "High-voltage battery management system: a146 state; raw 9 = signal not available (SNA)";
CM_ SG_ 1343 BMS_a146_packCurrent "High-voltage battery management system: a146 pack current";
CM_ SG_ 1343 BMS_a146_uvBrickVID "High-voltage battery management system: a146 uv brick VID";
CM_ SG_ 1343 BMS_a146_uvBrickV "High-voltage battery management system: a146 uv brick v";
CM_ SG_ 1343 BMS_a151_isoPositiveR "High-voltage battery management system: a151 iso positive r";
CM_ SG_ 1343 BMS_a151_isoNegativeR "High-voltage battery management system: a151 iso negative r";
CM_ SG_ 1343 BMS_a152_isoR "High-voltage battery management system: a152 iso r";
CM_ SG_ 1343 BMS_a152_mode "High-voltage battery management system: a152 mode";
CM_ SG_ 1343 BMS_a152_activeSideVNoR "High-voltage battery management system: a152 active side v no r";
CM_ SG_ 1343 BMS_a152_activeSideVWithR "High-voltage battery management system: a152 active side v with r";
CM_ SG_ 1343 BMS_a152_passiveSideVNoR "High-voltage battery management system: a152 passive side v no r";
CM_ SG_ 1343 BMS_a152_passiveSideVWithR "High-voltage battery management system: a152 passive side v with r";
CM_ SG_ 1343 BMS_a154_packCurrent "High-voltage battery management system: a154 pack current";
CM_ SG_ 1343 BMS_a154_ovBrickVID "High-voltage battery management system: a154 ov brick VID";
CM_ SG_ 1343 BMS_a154_ovBrickV "High-voltage battery management system: a154 ov brick v";
CM_ SG_ 1343 BMS_a156_VrefSample "High-voltage battery management system: a156 vref sample";
CM_ SG_ 1343 BMS_a156_bmbDeviceId "High-voltage battery management system: a156 bmb device id";
CM_ SG_ 1343 BMS_a156_VrefStatus "High-voltage battery management system: a156 vref status";
CM_ SG_ 1343 BMS_a158_shuntCurrentMia "High-voltage battery management system: a158 shunt current mia";
CM_ SG_ 1343 BMS_a158_contactorStateMia "High-voltage battery management system: a158 contactor state mia";
CM_ SG_ 1343 BMS_a158_hvpFaultsMia "High-voltage battery management system: a158 hvp faults mia";
CM_ SG_ 1343 BMS_a162_dischargePower_W "High-voltage battery management system: a162 discharge power w";
CM_ SG_ 1343 BMS_a162_minSoc "High-voltage battery management system: a162 min soc";
CM_ SG_ 1343 BMS_a162_socThreshold "High-voltage battery management system: a162 soc threshold";
CM_ SG_ 1343 BMS_a164_regenPower "High-voltage battery management system: a164 regen power";
CM_ SG_ 1343 BMS_a165_packPositiveV "High-voltage battery management system: a165 pack positive v";
CM_ SG_ 1343 BMS_a165_packNegativeV "High-voltage battery management system: a165 pack negative v";
CM_ SG_ 1343 BMS_a165_dcLinkPositiveV "High-voltage battery management system: a165 dc link positive v";
CM_ SG_ 1343 BMS_a165_dcLinkNegativeV "High-voltage battery management system: a165 dc link negative v";
CM_ SG_ 1343 BMS_a166_packPositiveV "High-voltage battery management system: a166 pack positive v";
CM_ SG_ 1343 BMS_a166_packNegativeV "High-voltage battery management system: a166 pack negative v";
CM_ SG_ 1343 BMS_a166_dcLinkPositiveV "High-voltage battery management system: a166 dc link positive v";
CM_ SG_ 1343 BMS_a166_dcLinkNegativeV "High-voltage battery management system: a166 dc link negative v";
CM_ SG_ 1343 BMS_a167_fcContPositiveAuxOpen "High-voltage battery management system: a167 fc cont positive aux open";
CM_ SG_ 1343 BMS_a167_fcContNegativeAuxOpen "High-voltage battery management system: a167 fc cont negative aux open";
CM_ SG_ 1343 BMS_a167_dcLinkPositiveV "High-voltage battery management system: a167 dc link positive v";
CM_ SG_ 1343 BMS_a167_dcLinkNegativeV "High-voltage battery management system: a167 dc link negative v";
CM_ SG_ 1343 BMS_a167_fcLinkPositiveV "High-voltage battery management system: a167 fc link positive v";
CM_ SG_ 1343 BMS_a167_fcLinkNegativeV "High-voltage battery management system: a167 fc link negative v";
CM_ SG_ 1343 BMS_a168_fcContPositiveAuxOpen "High-voltage battery management system: a168 fc cont positive aux open";
CM_ SG_ 1343 BMS_a168_fcContNegativeAuxOpen "High-voltage battery management system: a168 fc cont negative aux open";
CM_ SG_ 1343 BMS_a168_dcLinkPositiveV "High-voltage battery management system: a168 dc link positive v";
CM_ SG_ 1343 BMS_a168_dcLinkNegativeV "High-voltage battery management system: a168 dc link negative v";
CM_ SG_ 1343 BMS_a168_fcLinkPositiveV "High-voltage battery management system: a168 fc link positive v";
CM_ SG_ 1343 BMS_a168_fcLinkNegativeV "High-voltage battery management system: a168 fc link negative v";
CM_ SG_ 1343 BMS_a169_DCAndFCContactorsWelded "High-voltage battery management system: a169 DC and FC contactors welded";
CM_ SG_ 1343 BMS_a170_limpModeActive "High-voltage battery management system: a170 limp mode active";
CM_ SG_ 1343 BMS_a171_stackVoltage "High-voltage battery management system: a171 stack voltage";
CM_ SG_ 1343 BMS_a171_sumBrickVoltage "High-voltage battery management system: a171 sum brick voltage";
CM_ SG_ 1343 BMS_a171_stackId "High-voltage battery management system: a171 stack id";
CM_ SG_ 1343 BMS_a172_swIsolationCount "High-voltage battery management system: a172 sw isolation count";
CM_ SG_ 1343 BMS_a177_energyAlertThreshold "High-voltage battery management system: a177 energy alert threshold";
CM_ SG_ 1343 BMS_a177_energyBuffer "High-voltage battery management system: a177 energy buffer";
CM_ SG_ 1343 BMS_a178_diPower "High-voltage battery management system: a178 di power";
CM_ SG_ 1343 BMS_a178_energyError "High-voltage battery management system: a178 energy error";
CM_ SG_ 1343 BMS_a178_powerError "High-voltage battery management system: a178 power error";
CM_ SG_ 1343 BMS_a178_minPowerError "High-voltage battery management system: a178 min power error";
CM_ SG_ 1343 BMS_a178_maxPowerError "High-voltage battery management system: a178 max power error";
CM_ SG_ 1343 BMS_a178_diMiaCount "High-voltage battery management system: a178 di mia count";
CM_ SG_ 1343 BMS_a178_diSnaCount "High-voltage battery management system: a178 di sna count";
CM_ SG_ 1343 BMS_a188_currentTripThreshold "High-voltage battery management system: a188 current trip threshold";
CM_ SG_ 1343 BMS_a188_dcLinkDetectedCurrent "High-voltage battery management system: a188 dc link detected current";
CM_ SG_ 1343 BMS_a189_currentTripThreshold "High-voltage battery management system: a189 current trip threshold";
CM_ SG_ 1343 BMS_a189_dcLinkDetectedCurrent "High-voltage battery management system: a189 dc link detected current";
CM_ SG_ 1343 BMS_a190_voltageTripThreshold "High-voltage battery management system: a190 voltage trip threshold";
CM_ SG_ 1343 BMS_a190_dcLinkDetectedVoltage "High-voltage battery management system: a190 dc link detected voltage";
CM_ SG_ 1343 BMS_a191_voltageTripThreshold "High-voltage battery management system: a191 voltage trip threshold";
CM_ SG_ 1343 BMS_a191_dcLinkDetectedVoltage "High-voltage battery management system: a191 dc link detected voltage";
CM_ SG_ 1343 BMS_a192_detectedChargeCurrent "High-voltage battery management system: a192 detected charge current";
CM_ SG_ 1343 BMS_a193_maxBrickVoltageLimit "High-voltage battery management system: a193 max brick voltage limit";
CM_ SG_ 1343 BMS_a193_detectedMaxBrickVoltage "High-voltage battery management system: a193 detected max brick voltage";
CM_ SG_ 1343 BMS_a201_maxBrickV "High-voltage battery management system: a201 max brick v";
CM_ SG_ 1343 BMS_a201_maxBrickVIndex "High-voltage battery management system: a201 max brick v index";
CM_ SG_ 1343 BMS_a227_packCurrent "High-voltage battery management system: a227 pack current; raw 32768 = signal not available (SNA)";
CM_ SG_ 1343 BMS_a227_dcChargeCurrentRequest "High-voltage battery management system: a227 dc charge current request; raw 32768 = signal not available (SNA)";
CM_ SG_ 1343 BMS_a256_minBrickT "High-voltage battery management system: a256 min brick t";
CM_ SG_ 1343 BMS_a256_maxBrickT "High-voltage battery management system: a256 max brick t";
CM_ SG_ 1343 BMS_a256_minBrickV "High-voltage battery management system: a256 min brick v";
CM_ SG_ 1343 BMS_a256_maxBrickV "High-voltage battery management system: a256 max brick v";
CM_ SG_ 1343 BMS_a256_packSoe "High-voltage battery management system: a256 pack soe";
CM_ SG_ 1343 BMS_a256_SOC "High-voltage battery management system: a256 SOC";
BA_DEF_ "BusType" STRING;
BA_DEF_ "DBName" STRING;
BA_DEF_ "Baudrate" INT 0 1000000;
BA_DEF_ "BaudrateCANFD" INT 0 16000000;
BA_DEF_ "Manufacturer" STRING;
BA_DEF_ "FirmwareVersion" STRING;
BA_DEF_ "VehicleModel" STRING;
BA_DEF_ BU_ "ECU" STRING;
BA_DEF_ BO_ "GenMsgCycleTime" INT 0 3600000;
BA_DEF_ BO_ "GenMsgSendType" ENUM "Cyclic","NotUsed","NotUsed","NotUsed","NotUsed","NotUsed","NotUsed","IfActive","NoMsgSendType","NotUsed";
BA_DEF_ BO_ "VFrameFormat" ENUM "StandardCAN","ExtendedCAN","reserved","J1939PG","reserved","reserved","reserved","reserved","reserved","reserved","reserved","reserved","reserved","reserved","StandardCAN_FD","ExtendedCAN_FD";
BA_DEF_ BO_ "CANFD_BRS" ENUM "0","1";
BA_DEF_ SG_ "GenSigSNA" STRING;
BA_DEF_ SG_ "SystemSignalLongSymbol" STRING;
BA_DEF_ SG_ "Confidence" ENUM "validated","plausible","layout-only","contradicted";
BA_DEF_DEF_ "BusType" "CAN";
BA_DEF_DEF_ "DBName" "";
BA_DEF_DEF_ "Baudrate" 500000;
BA_DEF_DEF_ "BaudrateCANFD" 2000000;
BA_DEF_DEF_ "Manufacturer" "";
BA_DEF_DEF_ "FirmwareVersion" "";
BA_DEF_DEF_ "VehicleModel" "";
BA_DEF_DEF_ "ECU" "";
BA_DEF_DEF_ "GenMsgCycleTime" 0;
BA_DEF_DEF_ "GenMsgSendType" "NoMsgSendType";
BA_DEF_DEF_ "VFrameFormat" "StandardCAN";
BA_DEF_DEF_ "CANFD_BRS" "1";
BA_DEF_DEF_ "GenSigSNA" "";
BA_DEF_DEF_ "SystemSignalLongSymbol" "";
BA_DEF_DEF_ "Confidence" "layout-only";
BA_ "DBName" "AllModels_VEH";
BA_ "Manufacturer" "Tesla";
BA_ "FirmwareVersion" "2026.26.6.5";
BA_ "VehicleModel" "Model 3 / Model Y";
BA_ "ECU" BU_ APP "APP";
BA_ "ECU" BU_ APS "APS";
BA_ "ECU" BU_ BMS "BMS";
BA_ "ECU" BU_ CC "CC";
BA_ "ECU" BU_ CMP "CMP";
BA_ "ECU" BU_ CMPD "CMPD";
BA_ "ECU" BU_ CP "CP";
BA_ "ECU" BU_ DAS "DAS";
BA_ "ECU" BU_ DI "DI";
BA_ "ECU" BU_ DIF "DIF";
BA_ "ECU" BU_ DIR "DIR";
BA_ "ECU" BU_ EPBL "EPBL";
BA_ "ECU" BU_ EPBR "EPBR";
BA_ "ECU" BU_ EVSE "EVSE";
BA_ "ECU" BU_ FC "FC";
BA_ "ECU" BU_ GTW "GTW";
BA_ "ECU" BU_ HCML "HCML";
BA_ "ECU" BU_ HCMR "HCMR";
BA_ "ECU" BU_ HVP "HVP";
BA_ "ECU" BU_ ICR "ICR";
BA_ "ECU" BU_ PCS "PCS";
BA_ "ECU" BU_ PCS2 "PCS2";
BA_ "ECU" BU_ PLG "PLG";
BA_ "ECU" BU_ PM "PM";
BA_ "ECU" BU_ PMF "PMF";
BA_ "ECU" BU_ PMR "PMR";
BA_ "ECU" BU_ PTC "PTC";
BA_ "ECU" BU_ SCCM "SCCM";
BA_ "ECU" BU_ SCM "SCM";
BA_ "ECU" BU_ SCS "SCS";
BA_ "ECU" BU_ SDCR "SDCR";
BA_ "ECU" BU_ TAS "TAS";
BA_ "ECU" BU_ UMC "UMC";
BA_ "ECU" BU_ V2G "V2G";
BA_ "ECU" BU_ VC "VC";
BA_ "ECU" BU_ VCBATT "VCBATT";
BA_ "ECU" BU_ VCBATT0 "VCBATT0";
BA_ "ECU" BU_ VCBATT1 "VCBATT1";
BA_ "ECU" BU_ VCBATT2 "VCBATT2";
BA_ "ECU" BU_ VCFRONT "VCFRONT";
BA_ "ECU" BU_ VCFRONT1 "VCFRONT1";
BA_ "ECU" BU_ VCFRONT2 "VCFRONT2";
BA_ "ECU" BU_ VCLEFT "VCLEFT";
BA_ "ECU" BU_ VCRIGHT "VCRIGHT";
BA_ "ECU" BU_ VCSEAT2L "VCSEAT2L";
BA_ "ECU" BU_ VCSEAT2R "VCSEAT2R";
BA_ "ECU" BU_ VCSEC "VCSEC";
BA_ "GenMsgCycleTime" BO_ 1951 20;
BA_ "GenMsgSendType" BO_ 1951 0;
BA_ "GenMsgCycleTime" BO_ 909 1000;
BA_ "GenMsgSendType" BO_ 909 0;
BA_ "GenMsgCycleTime" BO_ 1018 500;
BA_ "GenMsgSendType" BO_ 1018 0;
BA_ "GenMsgCycleTime" BO_ 1056 100;
BA_ "GenMsgSendType" BO_ 1056 0;
BA_ "Confidence" SG_ 1951 ADSP_audioVisualizerBrightness 0;
BA_ "Confidence" SG_ 909 APP_inTunnel 0;
BA_ "GenSigSNA" SG_ 909 APP_inTunnel "0";
BA_ "Confidence" SG_ 909 APP_windshieldHeaterOnReason 0;
BA_ "GenSigSNA" SG_ 909 APP_windshieldHeaterOnReason "0";
BA_ "Confidence" SG_ 909 APP_selfieCameraBlocked 0;
BA_ "GenSigSNA" SG_ 909 APP_selfieCameraBlocked "0";
BA_ "Confidence" SG_ 909 APP_selfieCameraLUX 0;
BA_ "GenSigSNA" SG_ 909 APP_selfieCameraLUX "255";
BA_ "Confidence" SG_ 909 APP_sceneTagClearlyRaining 0;
BA_ "GenSigSNA" SG_ 909 APP_sceneTagClearlyRaining "0";
BA_ "Confidence" SG_ 909 APP_sceneTagFog 0;
BA_ "GenSigSNA" SG_ 909 APP_sceneTagFog "0";
BA_ "Confidence" SG_ 909 APP_sceneTagFullyBlocked 0;
BA_ "GenSigSNA" SG_ 909 APP_sceneTagFullyBlocked "0";
BA_ "Confidence" SG_ 909 APP_sceneTagIndoors 0;
BA_ "GenSigSNA" SG_ 909 APP_sceneTagIndoors "0";
BA_ "Confidence" SG_ 909 APP_sceneTagLensFlare 0;
BA_ "GenSigSNA" SG_ 909 APP_sceneTagLensFlare "0";
BA_ "Confidence" SG_ 909 APP_sceneTagRaining 0;
BA_ "GenSigSNA" SG_ 909 APP_sceneTagRaining "0";
BA_ "Confidence" SG_ 909 APP_sceneTagSevereWeather 0;
BA_ "GenSigSNA" SG_ 909 APP_sceneTagSevereWeather "0";
BA_ "Confidence" SG_ 909 APP_sceneTagSnowing 0;
BA_ "GenSigSNA" SG_ 909 APP_sceneTagSnowing "0";
BA_ "Confidence" SG_ 909 APP_sceneTagSnowyRoad 0;
BA_ "GenSigSNA" SG_ 909 APP_sceneTagSnowyRoad "0";
BA_ "Confidence" SG_ 909 APP_sceneTagSunGlare 0;
BA_ "GenSigSNA" SG_ 909 APP_sceneTagSunGlare "0";
BA_ "Confidence" SG_ 909 APP_sceneTagTunnel 0;
BA_ "GenSigSNA" SG_ 909 APP_sceneTagTunnel "0";
BA_ "Confidence" SG_ 909 APP_sceneTagWetRoad 0;
BA_ "GenSigSNA" SG_ 909 APP_sceneTagWetRoad "0";
BA_ "Confidence" SG_ 909 APP_fisheyeInPathVisibility 0;
BA_ "GenSigSNA" SG_ 909 APP_fisheyeInPathVisibility "0";
BA_ "Confidence" SG_ 909 APP_fisheyeOverallVisibility 0;
BA_ "GenSigSNA" SG_ 909 APP_fisheyeOverallVisibility "0";
BA_ "Confidence" SG_ 909 APP_mainInPathVisibility 0;
BA_ "GenSigSNA" SG_ 909 APP_mainInPathVisibility "0";
BA_ "Confidence" SG_ 909 APP_mainOverallVisibility 0;
BA_ "GenSigSNA" SG_ 909 APP_mainOverallVisibility "0";
BA_ "Confidence" SG_ 909 APP_narrowInPathVisibility 0;
BA_ "GenSigSNA" SG_ 909 APP_narrowInPathVisibility "0";
BA_ "Confidence" SG_ 909 APP_narrowOverallVisibility 0;
BA_ "GenSigSNA" SG_ 909 APP_narrowOverallVisibility "0";
BA_ "Confidence" SG_ 909 APP_frontCamOcclusionType 0;
BA_ "Confidence" SG_ 1018 APP_mainCameraLUX 1;
BA_ "GenSigSNA" SG_ 1018 APP_mainCameraLUX "255";
BA_ "Confidence" SG_ 1018 APP_narrowCameraLUX 1;
BA_ "GenSigSNA" SG_ 1018 APP_narrowCameraLUX "255";
BA_ "Confidence" SG_ 1018 APP_fisheyeCameraLUX 1;
BA_ "GenSigSNA" SG_ 1018 APP_fisheyeCameraLUX "255";
BA_ "Confidence" SG_ 1018 APP_lRepeatCameraLUX 1;
BA_ "GenSigSNA" SG_ 1018 APP_lRepeatCameraLUX "255";
BA_ "Confidence" SG_ 1018 APP_rRepeatCameraLUX 1;
BA_ "GenSigSNA" SG_ 1018 APP_rRepeatCameraLUX "255";
BA_ "Confidence" SG_ 1018 APP_lPillarCameraLUX 1;
BA_ "GenSigSNA" SG_ 1018 APP_lPillarCameraLUX "255";
BA_ "Confidence" SG_ 1018 APP_rPillarCameraLUX 1;
BA_ "GenSigSNA" SG_ 1018 APP_rPillarCameraLUX "255";
BA_ "Confidence" SG_ 1018 APP_backupCameraLUX 1;
BA_ "GenSigSNA" SG_ 1018 APP_backupCameraLUX "255";
BA_ "Confidence" SG_ 1056 APS_primaryTurbo 1;
BA_ "Confidence" SG_ 1056 APS_A_arbState 1;
BA_ "Confidence" SG_ 1056 APS_A_powerState 1;
BA_ "Confidence" SG_ 1056 APS_A_sleepState 1;
BA_ "Confidence" SG_ 1056 APS_A_resetState 1;
BA_ "Confidence" SG_ 1056 APS_A_faultState 1;
BA_ "Confidence" SG_ 1056 APS_secondaryTurbo 1;
BA_ "Confidence" SG_ 1056 APS_B_arbState 1;
BA_ "Confidence" SG_ 1056 APS_B_powerState 1;
BA_ "Confidence" SG_ 1056 APS_B_sleepState 1;
BA_ "Confidence" SG_ 1056 APS_B_resetState 1;
BA_ "Confidence" SG_ 1056 APS_B_faultState 1;
BA_ "Confidence" SG_ 1056 APS_A_autosteerMonitorState 1;
BA_ "Confidence" SG_ 1056 APS_B_autosteerMonitorState 1;
BA_ "Confidence" SG_ 1056 APS_eplannerState 1;
BA_ "Confidence" SG_ 1343 BMS_alertID 1;
BA_ "GenSigSNA" SG_ 1343 BMS_alertID "127";
BA_ "Confidence" SG_ 1343 BMS_alertSet 1;
BA_ "Confidence" SG_ 1343 BMS_a001_gatewayPackEnergy 1;
BA_ "Confidence" SG_ 1343 BMS_a001_expectedPackEnergy 1;
BA_ "Confidence" SG_ 1343 BMS_a002_gatewayPackPerformanceD 1;
BA_ "SystemSignalLongSymbol" SG_ 1343 BMS_a002_gatewayPackPerformanceD "BMS_a002_gatewayPackPerformanceDeviation";
BA_ "Confidence" SG_ 1343 BMS_a002_expectedPackPerformance 1;
BA_ "SystemSignalLongSymbol" SG_ 1343 BMS_a002_expectedPackPerformance "BMS_a002_expectedPackPerformanceDeviation";
BA_ "Confidence" SG_ 1343 BMS_a002_bmsPackMass 1;
BA_ "Confidence" SG_ 1343 BMS_a017_packCurrent 1;
BA_ "Confidence" SG_ 1343 BMS_a017_ovBrickV 1;
BA_ "Confidence" SG_ 1343 BMS_a018_packCurrent 1;
BA_ "Confidence" SG_ 1343 BMS_a018_uvBrickV 1;
BA_ "Confidence" SG_ 1343 BMS_a019_coolantInletT 1;
BA_ "Confidence" SG_ 1343 BMS_a019_activeCoolingTarget 1;
BA_ "Confidence" SG_ 1343 BMS_a019_maxBrickT 1;
BA_ "Confidence" SG_ 1343 BMS_a021_currentLimit 1;
BA_ "Confidence" SG_ 1343 BMS_a021_packCurrent 1;
BA_ "SystemSignalLongSymbol" SG_ 1343 BMS_a022_chargeAccumulatorViolat "BMS_a022_chargeAccumulatorViolation";
BA_ "Confidence" SG_ 1343 BMS_a022_chargeAccumulatorValue 1;
BA_ "Confidence" SG_ 1343 BMS_a022_chargeAccumulatorLimit 1;
BA_ "Confidence" SG_ 1343 BMS_a023_ovStackDeviceID 1;
BA_ "Confidence" SG_ 1343 BMS_a023_ovStackV 1;
BA_ "Confidence" SG_ 1343 BMS_a024_brickID 1;
BA_ "Confidence" SG_ 1343 BMS_a024_deltaV 1;
BA_ "Confidence" SG_ 1343 BMS_a024_avgDvPrev 1;
BA_ "Confidence" SG_ 1343 BMS_a024_packCurrent 1;
BA_ "Confidence" SG_ 1343 BMS_a030_maxBrickImpedance 1;
BA_ "Confidence" SG_ 1343 BMS_a030_maxNormalizedImpedanceD 1;
BA_ "SystemSignalLongSymbol" SG_ 1343 BMS_a030_maxNormalizedImpedanceD "BMS_a030_maxNormalizedImpedanceDev";
BA_ "Confidence" SG_ 1343 BMS_a030_faultThreshold 1;
BA_ "Confidence" SG_ 1343 BMS_a030_worstBrickSoc 1;
BA_ "Confidence" SG_ 1343 BMS_a035_isoR 1;
BA_ "Confidence" SG_ 1343 BMS_a035_mode 1;
BA_ "Confidence" SG_ 1343 BMS_a035_activeSideVNoR 1;
BA_ "Confidence" SG_ 1343 BMS_a035_activeSideVWithR 1;
BA_ "Confidence" SG_ 1343 BMS_a035_passiveSideVNoR 1;
BA_ "Confidence" SG_ 1343 BMS_a035_passiveSideVWithR 1;
BA_ "Confidence" SG_ 1343 BMS_a039_dcLinkVoltage 1;
BA_ "Confidence" SG_ 1343 BMS_a039_packVoltage 1;
BA_ "Confidence" SG_ 1343 BMS_a039_packContactorState 1;
BA_ "GenSigSNA" SG_ 1343 BMS_a039_packContactorState "0";
BA_ "Confidence" SG_ 1343 BMS_a039_packCurrent 1;
BA_ "Confidence" SG_ 1343 BMS_a039_maxBrickV 1;
BA_ "Confidence" SG_ 1343 BMS_a039_state 1;
BA_ "GenSigSNA" SG_ 1343 BMS_a039_state "9";
BA_ "Confidence" SG_ 1343 BMS_a041_resetType 1;
BA_ "Confidence" SG_ 1343 BMS_a051_hvp1V5Ref 1;
BA_ "Confidence" SG_ 1343 BMS_a051_hvp3V0Ref 1;
BA_ "Confidence" SG_ 1343 BMS_a051_bms3V0Ref 1;
BA_ "Confidence" SG_ 1343 BMS_a059_sumBrickVoltages 1;
BA_ "Confidence" SG_ 1343 BMS_a059_packVoltage 1;
BA_ "Confidence" SG_ 1343 BMS_a062_state 1;
BA_ "GenSigSNA" SG_ 1343 BMS_a062_state "9";
BA_ "Confidence" SG_ 1343 BMS_a062_minBrickVoltage 1;
BA_ "Confidence" SG_ 1343 BMS_a062_maxBrickVoltage 1;
BA_ "Confidence" SG_ 1343 BMS_a063_cpFaultInV 1;
BA_ "Confidence" SG_ 1343 BMS_a064_minBrickSOC 1;
BA_ "Confidence" SG_ 1343 BMS_a064_maxBrickSOC 1;
BA_ "Confidence" SG_ 1343 BMS_a064_avgBrickSOC 1;
BA_ "Confidence" SG_ 1343 BMS_a065_minBrickCac 1;
BA_ "Confidence" SG_ 1343 BMS_a065_avgBrickCac 1;
BA_ "Confidence" SG_ 1343 BMS_a065_modCacImbalancePct 1;
BA_ "Confidence" SG_ 1343 BMS_a066_minBrickSocByOcvMax 1;
BA_ "Confidence" SG_ 1343 BMS_a066_maxBrickSocByOcvMin 1;
BA_ "Confidence" SG_ 1343 BMS_a066_maxBrickSoc 1;
BA_ "Confidence" SG_ 1343 BMS_a066_avgBrickSoc 1;
BA_ "Confidence" SG_ 1343 BMS_a067_minBrickCac 1;
BA_ "Confidence" SG_ 1343 BMS_a067_avgBrickCac 1;
BA_ "Confidence" SG_ 1343 BMS_a067_modCacImbalancePct 1;
BA_ "Confidence" SG_ 1343 BMS_a068_minBrickCac 1;
BA_ "Confidence" SG_ 1343 BMS_a068_avgBrickCac 1;
BA_ "Confidence" SG_ 1343 BMS_a068_modCacImbalancePct 1;
BA_ "Confidence" SG_ 1343 BMS_a069_dischargePowerPackVolta 1;
BA_ "SystemSignalLongSymbol" SG_ 1343 BMS_a069_dischargePowerPackVolta "BMS_a069_dischargePowerPackVoltageFloor";
BA_ "Confidence" SG_ 1343 BMS_a069_dischargePowerBrickVolt 1;
BA_ "SystemSignalLongSymbol" SG_ 1343 BMS_a069_dischargePowerBrickVolt "BMS_a069_dischargePowerBrickVoltageFloor";
BA_ "Confidence" SG_ 1343 BMS_a069_SOC 1;
BA_ "Confidence" SG_ 1343 BMS_a069_minBrickT 1;
BA_ "Confidence" SG_ 1343 BMS_a069_minBrickVLimit 1;
BA_ "Confidence" SG_ 1343 BMS_a069_minBrickV 1;
BA_ "Confidence" SG_ 1343 BMS_a070_state 1;
BA_ "GenSigSNA" SG_ 1343 BMS_a070_state "9";
BA_ "Confidence" SG_ 1343 BMS_a070_minBrickVoltage 1;
BA_ "Confidence" SG_ 1343 BMS_a070_maxBrickVoltage 1;
BA_ "Confidence" SG_ 1343 BMS_a071_stateRequest 1;
BA_ "GenSigSNA" SG_ 1343 BMS_a071_stateRequest "9";
BA_ "Confidence" SG_ 1343 BMS_a071_state 1;
BA_ "GenSigSNA" SG_ 1343 BMS_a071_state "9";
BA_ "Confidence" SG_ 1343 BMS_a074_maxBrickVTarget 1;
BA_ "Confidence" SG_ 1343 BMS_a074_maxBrickV 1;
BA_ "Confidence" SG_ 1343 BMS_a075_chargeType 1;
BA_ "Confidence" SG_ 1343 BMS_a076_netAh 1;
BA_ "Confidence" SG_ 1343 BMS_a077_chargeErrType 1;
BA_ "Confidence" SG_ 1343 BMS_a077_maxBrickVTarget 1;
BA_ "Confidence" SG_ 1343 BMS_a077_maxBrickV 1;
BA_ "Confidence" SG_ 1343 BMS_a077_packTargetCurrent 1;
BA_ "Confidence" SG_ 1343 BMS_a077_packCurrent 1;
BA_ "Confidence" SG_ 1343 BMS_a078_peakDchInChg 1;
BA_ "GenSigSNA" SG_ 1343 BMS_a078_peakDchInChg "32768";
BA_ "Confidence" SG_ 1343 BMS_a079_maxBrickVTarget 1;
BA_ "Confidence" SG_ 1343 BMS_a079_maxBrickV 1;
BA_ "Confidence" SG_ 1343 BMS_a081_stateRequest 1;
BA_ "GenSigSNA" SG_ 1343 BMS_a081_stateRequest "9";
BA_ "Confidence" SG_ 1343 BMS_a081_firstBlockingAlertId 1;
BA_ "GenSigSNA" SG_ 1343 BMS_a081_firstBlockingAlertId "127";
BA_ "Confidence" SG_ 1343 BMS_a081_secondBlockingAlertId 1;
BA_ "GenSigSNA" SG_ 1343 BMS_a081_secondBlockingAlertId "127";
BA_ "Confidence" SG_ 1343 BMS_a081_thirdBlockingAlertId 1;
BA_ "GenSigSNA" SG_ 1343 BMS_a081_thirdBlockingAlertId "127";
BA_ "Confidence" SG_ 1343 BMS_a081_fourthBlockingAlertId 1;
BA_ "GenSigSNA" SG_ 1343 BMS_a081_fourthBlockingAlertId "127";
BA_ "Confidence" SG_ 1343 BMS_a082_stateRequest 1;
BA_ "GenSigSNA" SG_ 1343 BMS_a082_stateRequest "9";
BA_ "Confidence" SG_ 1343 BMS_a082_firstAlertId 1;
BA_ "GenSigSNA" SG_ 1343 BMS_a082_firstAlertId "127";
BA_ "Confidence" SG_ 1343 BMS_a082_secondAlertId 1;
BA_ "GenSigSNA" SG_ 1343 BMS_a082_secondAlertId "127";
BA_ "Confidence" SG_ 1343 BMS_a082_thirdAlertId 1;
BA_ "GenSigSNA" SG_ 1343 BMS_a082_thirdAlertId "127";
BA_ "Confidence" SG_ 1343 BMS_a082_fourthAlertId 1;
BA_ "GenSigSNA" SG_ 1343 BMS_a082_fourthAlertId "127";
BA_ "Confidence" SG_ 1343 BMS_a083_packContactorRequest 1;
BA_ "GenSigSNA" SG_ 1343 BMS_a083_packContactorRequest "0";
BA_ "Confidence" SG_ 1343 BMS_a085_packContactorSetStatePr 1;
BA_ "GenSigSNA" SG_ 1343 BMS_a085_packContactorSetStatePr "0";
BA_ "SystemSignalLongSymbol" SG_ 1343 BMS_a085_packContactorSetStatePr "BMS_a085_packContactorSetStatePrev";
BA_ "Confidence" SG_ 1343 BMS_a085_packContactorSetState 1;
BA_ "GenSigSNA" SG_ 1343 BMS_a085_packContactorSetState "0";
BA_ "Confidence" SG_ 1343 BMS_a085_packContactorSetRe_0001 1;
BA_ "GenSigSNA" SG_ 1343 BMS_a085_packContactorSetRe_0001 "0";
BA_ "SystemSignalLongSymbol" SG_ 1343 BMS_a085_packContactorSetRe_0001 "BMS_a085_packContactorSetRequestPrev";
BA_ "Confidence" SG_ 1343 BMS_a085_packContactorSetRequest 1;
BA_ "GenSigSNA" SG_ 1343 BMS_a085_packContactorSetRequest "0";
BA_ "Confidence" SG_ 1343 BMS_a086_fcContactorSetStatePrev 1;
BA_ "GenSigSNA" SG_ 1343 BMS_a086_fcContactorSetStatePrev "0";
BA_ "Confidence" SG_ 1343 BMS_a086_fcContactorSetState 1;
BA_ "GenSigSNA" SG_ 1343 BMS_a086_fcContactorSetState "0";
BA_ "Confidence" SG_ 1343 BMS_a086_fcContactorSetRequestPr 1;
BA_ "GenSigSNA" SG_ 1343 BMS_a086_fcContactorSetRequestPr "0";
BA_ "SystemSignalLongSymbol" SG_ 1343 BMS_a086_fcContactorSetRequestPr "BMS_a086_fcContactorSetRequestPrev";
BA_ "Confidence" SG_ 1343 BMS_a086_fcContactorSetRequest 1;
BA_ "GenSigSNA" SG_ 1343 BMS_a086_fcContactorSetRequest "0";
BA_ "Confidence" SG_ 1343 BMS_a087_blockingAlert 1;
BA_ "GenSigSNA" SG_ 1343 BMS_a087_blockingAlert "127";
BA_ "Confidence" SG_ 1343 BMS_a090_GTWmessageTout 1;
BA_ "Confidence" SG_ 1343 BMS_a098_bmbCommStatusTypeA 1;
BA_ "Confidence" SG_ 1343 BMS_a098_bmbCommStatusTypeB 1;
BA_ "Confidence" SG_ 1343 BMS_a099_bmbCommStatusTypeA 1;
BA_ "Confidence" SG_ 1343 BMS_a099_bmbCommStatusTypeB 1;
BA_ "Confidence" SG_ 1343 BMS_a099_bmbChainBreakType 1;
BA_ "Confidence" SG_ 1343 BMS_a105_avgBrickTModule1 1;
BA_ "Confidence" SG_ 1343 BMS_a105_avgBrickTModule2 1;
BA_ "Confidence" SG_ 1343 BMS_a105_avgBrickTModule3 1;
BA_ "Confidence" SG_ 1343 BMS_a105_avgBrickTModule4 1;
BA_ "Confidence" SG_ 1343 BMS_a105_inletTemp 1;
BA_ "Confidence" SG_ 1343 BMS_a106_minBrickT 1;
BA_ "Confidence" SG_ 1343 BMS_a106_maxBrickT 1;
BA_ "Confidence" SG_ 1343 BMS_a106_avgBrickT 1;
BA_ "Confidence" SG_ 1343 BMS_a106_inletTemp 1;
BA_ "Confidence" SG_ 1343 BMS_a117_brickSoc2 1;
BA_ "GenSigSNA" SG_ 1343 BMS_a117_brickSoc2 "1023";
BA_ "Confidence" SG_ 1343 BMS_a117_dSocAlertThreshold 1;
BA_ "Confidence" SG_ 1343 BMS_a117_dSocAlpha 1;
BA_ "GenSigSNA" SG_ 1343 BMS_a117_dSocAlpha "4095";
BA_ "Confidence" SG_ 1343 BMS_a118_brickSoc2 1;
BA_ "GenSigSNA" SG_ 1343 BMS_a118_brickSoc2 "1023";
BA_ "Confidence" SG_ 1343 BMS_a118_dSocAlertThreshold 1;
BA_ "Confidence" SG_ 1343 BMS_a118_dSocAlpha 1;
BA_ "GenSigSNA" SG_ 1343 BMS_a118_dSocAlpha "4095";
BA_ "Confidence" SG_ 1343 BMS_a122_irrationalThermistorTem 1;
BA_ "SystemSignalLongSymbol" SG_ 1343 BMS_a122_irrationalThermistorTem "BMS_a122_irrationalThermistorTemp";
BA_ "Confidence" SG_ 1343 BMS_a122_averageRawThermistorTem 1;
BA_ "SystemSignalLongSymbol" SG_ 1343 BMS_a122_averageRawThermistorTem "BMS_a122_averageRawThermistorTemp";
BA_ "Confidence" SG_ 1343 BMS_a122_minRawThermistorTemp 1;
BA_ "Confidence" SG_ 1343 BMS_a122_maxRawThermistorTemp 1;
BA_ "Confidence" SG_ 1343 BMS_a123_packPlus 1;
BA_ "Confidence" SG_ 1343 BMS_a123_isoR 1;
BA_ "Confidence" SG_ 1343 BMS_a123_packMinus 1;
BA_ "Confidence" SG_ 1343 BMS_a129_brickID 1;
BA_ "Confidence" SG_ 1343 BMS_a129_deltaV 1;
BA_ "Confidence" SG_ 1343 BMS_a129_retryCount 1;
BA_ "Confidence" SG_ 1343 BMS_a131_brickID 1;
BA_ "Confidence" SG_ 1343 BMS_a131_deltaV 1;
BA_ "Confidence" SG_ 1343 BMS_a131_retryCount 1;
BA_ "Confidence" SG_ 1343 BMS_a135_bmbDiagnosticsType 1;
BA_ "Confidence" SG_ 1343 BMS_a136_coolantInletT 1;
BA_ "Confidence" SG_ 1343 BMS_a136_activeCoolingTarget 1;
BA_ "Confidence" SG_ 1343 BMS_a136_maxBrickT 1;
BA_ "Confidence" SG_ 1343 BMS_a139_packVoltage 1;
BA_ "Confidence" SG_ 1343 BMS_a139_dcLinkVoltage 1;
BA_ "Confidence" SG_ 1343 BMS_a140_faultType 1;
BA_ "Confidence" SG_ 1343 BMS_a142_isolationResistance 1;
BA_ "Confidence" SG_ 1343 BMS_a142_mode 1;
BA_ "Confidence" SG_ 1343 BMS_a143_initialSoc 1;
BA_ "Confidence" SG_ 1343 BMS_a143_endingSoc 1;
BA_ "Confidence" SG_ 1343 BMS_a143_deltaAh 1;
BA_ "Confidence" SG_ 1343 BMS_a143_cacUpdateError 1;
BA_ "Confidence" SG_ 1343 BMS_a145_maxSocChange 1;
BA_ "Confidence" SG_ 1343 BMS_a145_brickChangeHystRatio 1;
BA_ "GenSigSNA" SG_ 1343 BMS_a145_brickChangeHystRatio "1023";
BA_ "Confidence" SG_ 1343 BMS_a146_maxBrickV 1;
BA_ "Confidence" SG_ 1343 BMS_a146_state 1;
BA_ "GenSigSNA" SG_ 1343 BMS_a146_state "9";
BA_ "Confidence" SG_ 1343 BMS_a146_packCurrent 1;
BA_ "Confidence" SG_ 1343 BMS_a146_uvBrickV 1;
BA_ "Confidence" SG_ 1343 BMS_a151_isoPositiveR 1;
BA_ "Confidence" SG_ 1343 BMS_a151_isoNegativeR 1;
BA_ "Confidence" SG_ 1343 BMS_a152_isoR 1;
BA_ "Confidence" SG_ 1343 BMS_a152_mode 1;
BA_ "Confidence" SG_ 1343 BMS_a152_activeSideVNoR 1;
BA_ "Confidence" SG_ 1343 BMS_a152_activeSideVWithR 1;
BA_ "Confidence" SG_ 1343 BMS_a152_passiveSideVNoR 1;
BA_ "Confidence" SG_ 1343 BMS_a152_passiveSideVWithR 1;
BA_ "Confidence" SG_ 1343 BMS_a154_packCurrent 1;
BA_ "Confidence" SG_ 1343 BMS_a154_ovBrickV 1;
BA_ "Confidence" SG_ 1343 BMS_a156_VrefSample 1;
BA_ "Confidence" SG_ 1343 BMS_a156_VrefStatus 1;
BA_ "Confidence" SG_ 1343 BMS_a162_dischargePower_W 1;
BA_ "Confidence" SG_ 1343 BMS_a162_minSoc 1;
BA_ "Confidence" SG_ 1343 BMS_a162_socThreshold 1;
BA_ "Confidence" SG_ 1343 BMS_a164_regenPower 1;
BA_ "Confidence" SG_ 1343 BMS_a165_packPositiveV 1;
BA_ "Confidence" SG_ 1343 BMS_a165_packNegativeV 1;
BA_ "Confidence" SG_ 1343 BMS_a165_dcLinkPositiveV 1;
BA_ "Confidence" SG_ 1343 BMS_a165_dcLinkNegativeV 1;
BA_ "Confidence" SG_ 1343 BMS_a166_packPositiveV 1;
BA_ "Confidence" SG_ 1343 BMS_a166_packNegativeV 1;
BA_ "Confidence" SG_ 1343 BMS_a166_dcLinkPositiveV 1;
BA_ "Confidence" SG_ 1343 BMS_a166_dcLinkNegativeV 1;
BA_ "Confidence" SG_ 1343 BMS_a167_dcLinkPositiveV 1;
BA_ "Confidence" SG_ 1343 BMS_a167_dcLinkNegativeV 1;
BA_ "Confidence" SG_ 1343 BMS_a167_fcLinkPositiveV 1;
BA_ "Confidence" SG_ 1343 BMS_a167_fcLinkNegativeV 1;
BA_ "Confidence" SG_ 1343 BMS_a168_dcLinkPositiveV 1;
BA_ "Confidence" SG_ 1343 BMS_a168_dcLinkNegativeV 1;
BA_ "Confidence" SG_ 1343 BMS_a168_fcLinkPositiveV 1;
BA_ "Confidence" SG_ 1343 BMS_a168_fcLinkNegativeV 1;
BA_ "Confidence" SG_ 1343 BMS_a171_stackVoltage 1;
BA_ "Confidence" SG_ 1343 BMS_a171_sumBrickVoltage 1;
BA_ "Confidence" SG_ 1343 BMS_a177_energyAlertThreshold 1;
BA_ "Confidence" SG_ 1343 BMS_a177_energyBuffer 1;
BA_ "Confidence" SG_ 1343 BMS_a178_diPower 1;
BA_ "Confidence" SG_ 1343 BMS_a178_energyError 1;
BA_ "Confidence" SG_ 1343 BMS_a178_powerError 1;
BA_ "Confidence" SG_ 1343 BMS_a178_minPowerError 1;
BA_ "Confidence" SG_ 1343 BMS_a178_maxPowerError 1;
BA_ "Confidence" SG_ 1343 BMS_a188_currentTripThreshold 1;
BA_ "Confidence" SG_ 1343 BMS_a188_dcLinkDetectedCurrent 1;
BA_ "Confidence" SG_ 1343 BMS_a189_currentTripThreshold 1;
BA_ "Confidence" SG_ 1343 BMS_a189_dcLinkDetectedCurrent 1;
BA_ "Confidence" SG_ 1343 BMS_a190_voltageTripThreshold 1;
BA_ "Confidence" SG_ 1343 BMS_a190_dcLinkDetectedVoltage 1;
BA_ "Confidence" SG_ 1343 BMS_a191_voltageTripThreshold 1;
BA_ "Confidence" SG_ 1343 BMS_a191_dcLinkDetectedVoltage 1;
BA_ "Confidence" SG_ 1343 BMS_a192_detectedChargeCurrent 1;
BA_ "Confidence" SG_ 1343 BMS_a193_maxBrickVoltageLimit 1;
BA_ "Confidence" SG_ 1343 BMS_a193_detectedMaxBrickVoltage 1;
BA_ "Confidence" SG_ 1343 BMS_a201_maxBrickV 1;
BA_ "Confidence" SG_ 1343 BMS_a227_packCurrent 1;
BA_ "GenSigSNA" SG_ 1343 BMS_a227_packCurrent "32768";
BA_ "Confidence" SG_ 1343 BMS_a227_dcChargeCurrentRequest 1;
BA_ "GenSigSNA" SG_ 1343 BMS_a227_dcChargeCurrentRequest "32768";
BA_ "Confidence" SG_ 1343 BMS_a256_minBrickT 1;
BA_ "Confidence" SG_ 1343 BMS_a256_maxBrickT 1;
BA_ "Confidence" SG_ 1343 BMS_a256_minBrickV 1;
BA_ "Confidence" SG_ 1343 BMS_a256_maxBrickV 1;
BA_ "Confidence" SG_ 1343 BMS_a256_packSoe 1;
BA_ "Confidence" SG_ 1343 BMS_a256_SOC 1;
VAL_ 909 APP_inTunnel 2 "NOT_IN_TUNNEL" 1 "IN_TUNNEL" 0 "IN_TUNNEL_SNA" ;
VAL_ 909 APP_windshieldHeaterOnReason 8 "WINDSHIELD_HEATER_ON_REASON_WIPERS_ACTIVE" 7 "WINDSHIELD_HEATER_ON_REASON_HVAC_REQUESTED" 6 "WINDSHIELD_HEATER_ON_REASON_OVERRIDE" 5 "WINDSHIELD_HEATER_ON_REASON_OFF" 4 "WINDSHIELD_HEATER_ON_REASON_STARTUP" 3 "WINDSHIELD_HEATER_ON_REASON_CONDENSATION_LIKELY" 2 "WINDSHIELD_HEATER_ON_REASON_OCCLUDED" 1 "WINDSHIELD_HEATER_ON_REASON_DEFROST" 0 "WINDSHIELD_HEATER_ON_REASON_SNA" ;
VAL_ 909 APP_selfieCameraBlocked 2 "SELFIE_CAMERA_BLOCKED" 1 "SELFIE_CAMERA_NOT_BLOCKED" 0 "SELFIE_CAMERA_BLOCKED_SNA" ;
VAL_ 909 APP_selfieCameraLUX 255 "SNA" 254 "SATURATED" ;
VAL_ 909 APP_sceneTagClearlyRaining 2 "NOT_ACTIVATED" 1 "ACTIVATED" 0 "SNA" ;
VAL_ 909 APP_sceneTagFog 2 "NOT_ACTIVATED" 1 "ACTIVATED" 0 "SNA" ;
VAL_ 909 APP_sceneTagFullyBlocked 2 "NOT_ACTIVATED" 1 "ACTIVATED" 0 "SNA" ;
VAL_ 909 APP_sceneTagIndoors 2 "NOT_ACTIVATED" 1 "ACTIVATED" 0 "SNA" ;
VAL_ 909 APP_sceneTagLensFlare 2 "NOT_ACTIVATED" 1 "ACTIVATED" 0 "SNA" ;
VAL_ 909 APP_sceneTagRaining 2 "NOT_ACTIVATED" 1 "ACTIVATED" 0 "SNA" ;
VAL_ 909 APP_sceneTagSevereWeather 2 "NOT_ACTIVATED" 1 "ACTIVATED" 0 "SNA" ;
VAL_ 909 APP_sceneTagSnowing 2 "NOT_ACTIVATED" 1 "ACTIVATED" 0 "SNA" ;
VAL_ 909 APP_sceneTagSnowyRoad 2 "NOT_ACTIVATED" 1 "ACTIVATED" 0 "SNA" ;
VAL_ 909 APP_sceneTagSunGlare 2 "NOT_ACTIVATED" 1 "ACTIVATED" 0 "SNA" ;
VAL_ 909 APP_sceneTagTunnel 2 "NOT_ACTIVATED" 1 "ACTIVATED" 0 "SNA" ;
VAL_ 909 APP_sceneTagWetRoad 2 "NOT_ACTIVATED" 1 "ACTIVATED" 0 "SNA" ;
VAL_ 909 APP_fisheyeInPathVisibility 4 "VISIBILITY_CONDITION_NOMINAL" 3 "VISIBILITY_OCCLUDED_LOW_SEVERITY" 2 "VISIBILITY_OCCLUDED_MEDIUM_SEVERITY" 1 "VISIBILITY_OCCLUDED_HIGH_SEVERITY" 0 "VISIBILITY_CONDITION_SNA" ;
VAL_ 909 APP_fisheyeOverallVisibility 4 "VISIBILITY_CONDITION_NOMINAL" 3 "VISIBILITY_OCCLUDED_LOW_SEVERITY" 2 "VISIBILITY_OCCLUDED_MEDIUM_SEVERITY" 1 "VISIBILITY_OCCLUDED_HIGH_SEVERITY" 0 "VISIBILITY_CONDITION_SNA" ;
VAL_ 909 APP_mainInPathVisibility 4 "VISIBILITY_CONDITION_NOMINAL" 3 "VISIBILITY_OCCLUDED_LOW_SEVERITY" 2 "VISIBILITY_OCCLUDED_MEDIUM_SEVERITY" 1 "VISIBILITY_OCCLUDED_HIGH_SEVERITY" 0 "VISIBILITY_CONDITION_SNA" ;
VAL_ 909 APP_mainOverallVisibility 4 "VISIBILITY_CONDITION_NOMINAL" 3 "VISIBILITY_OCCLUDED_LOW_SEVERITY" 2 "VISIBILITY_OCCLUDED_MEDIUM_SEVERITY" 1 "VISIBILITY_OCCLUDED_HIGH_SEVERITY" 0 "VISIBILITY_CONDITION_SNA" ;
VAL_ 909 APP_narrowInPathVisibility 4 "VISIBILITY_CONDITION_NOMINAL" 3 "VISIBILITY_OCCLUDED_LOW_SEVERITY" 2 "VISIBILITY_OCCLUDED_MEDIUM_SEVERITY" 1 "VISIBILITY_OCCLUDED_HIGH_SEVERITY" 0 "VISIBILITY_CONDITION_SNA" ;
VAL_ 909 APP_narrowOverallVisibility 4 "VISIBILITY_CONDITION_NOMINAL" 3 "VISIBILITY_OCCLUDED_LOW_SEVERITY" 2 "VISIBILITY_OCCLUDED_MEDIUM_SEVERITY" 1 "VISIBILITY_OCCLUDED_HIGH_SEVERITY" 0 "VISIBILITY_CONDITION_SNA" ;
VAL_ 909 APP_frontCamOcclusionType 6 "UNKNOWN_OCCLUSION" 5 "DEW" 4 "STREAK" 3 "SUN_GLARE" 2 "DIRTY_OR_BLOCKED" 1 "CONDENSATION" 0 "OFFGASSING" ;
VAL_ 1018 APP_mainCameraLUX 255 "SNA" 254 "SATURATED" ;
VAL_ 1018 APP_narrowCameraLUX 255 "SNA" 254 "SATURATED" ;
VAL_ 1018 APP_fisheyeCameraLUX 255 "SNA" 254 "SATURATED" ;
VAL_ 1018 APP_lRepeatCameraLUX 255 "SNA" 254 "SATURATED" ;
VAL_ 1018 APP_rRepeatCameraLUX 255 "SNA" 254 "SATURATED" ;
VAL_ 1018 APP_lPillarCameraLUX 255 "SNA" 254 "SATURATED" ;
VAL_ 1018 APP_rPillarCameraLUX 255 "SNA" 254 "SATURATED" ;
VAL_ 1018 APP_backupCameraLUX 255 "SNA" 254 "SATURATED" ;
VAL_ 1056 APS_primaryTurbo 2 "TURBO_UNKNOWN" 1 "TURBO_B" 0 "TURBO_A" ;
VAL_ 1056 APS_A_arbState 7 "ARB_STATE_COUNT" 6 "ARB_STATE_UNKNOWN" 5 "ARB_STATE_MIA" 4 "ARB_STATE_FAULT" 3 "ARB_STATE_SECONDARY" 2 "ARB_STATE_PRIMARY" 1 "ARB_STATE_IDLE" 0 "ARB_STATE_INIT" ;
VAL_ 1056 APS_A_powerState 28 "POWER_STATE_AP_FORCE_POWER_OFF" 27 "POWER_STATE_AP_WAIT_FOR_SHUTDOWN_ABORT" 26 "POWER_STATE_AP_IN_LINUX" 25 "POWER_STATE_AP_IDLE" 24 "POWER_STATE_VEH_BOOTING" 23 "POWER_STATE_UNKNOWN" 22 "POWER_STATE_MIA" 21 "POWER_STATE_FAULT" 20 "POWER_STATE_SOC_OFF_ABORT" 19 "POWER_STATE_SOC_OFF" 18 "POWER_STATE_SOC_OFF_READY" 17 "POWER_STATE_AP_SUSPENDED" 16 "POWER_STATE_AP_OFF_ABORT_WAIT_FOR_ACK" 15 "POWER_STATE_AP_OFF_ABORT" 14 "POWER_STATE_AP_OFF_READY_WAIT_FOR_RESPONSE" 13 "POWER_STATE_AP_OFF_READY_WAIT_FOR_ACK" 12 "POWER_STATE_AP_OFF_READY" 11 "POWER_STATE_AP_OFF_PREPARE" 10 "POWER_STATE_AP_WAIT_FOR_SHUTDOWN" 9 "POWER_STATE_AP_ON" 8 "POWER_STATE_AP_IN_COREBOOT" 7 "POWER_STATE_AP_BOOTING" 6 "POWER_STATE_AP_ON_READY_WAIT_FOR_RESPONSE" 5 "POWER_STATE_AP_ON_READY_WAIT_FOR_ACK" 4 "POWER_STATE_AP_ON_READY" 3 "POWER_STATE_AP_ON_PREPARE_WAIT_FOR_RESPONSE" 2 "POWER_STATE_AP_ON_PREPARE_WAIT_FOR_ACK" 1 "POWER_STATE_AP_ON_PREPARE" 0 "POWER_STATE_IDLE" ;
VAL_ 1056 APS_A_sleepState 9 "SLEEP_STATE_COUNT" 8 "SLEEP_STATE_UNKNOWN" 7 "SLEEP_STATE_MIA" 6 "SLEEP_STATE_FAULT" 5 "SLEEP_STATE_ABORT" 4 "SLEEP_STATE_SLEEPING" 3 "SLEEP_STATE_GOING_TO_SLEEP" 2 "SLEEP_STATE_READY" 1 "SLEEP_STATE_WAIT_FOR_BUS_SILENCE" 0 "SLEEP_STATE_IDLE" ;
VAL_ 1056 APS_A_resetState 5 "RESET_STATE_COUNT" 4 "RESET_STATE_UNKNOWN" 3 "RESET_STATE_MIA" 2 "RESET_STATE_FAULT" 1 "RESET_STATE_RESETTING" 0 "RESET_STATE_NOT_RESETTING" ;
VAL_ 1056 APS_A_faultState 27 "FAULT_STATE_COUNT" 26 "FAULT_STATE_UNKNOWN" 25 "FAULT_STATE_MIA" 24 "FAULT_STATE_UNEXPECTED" 23 "FAULT_STATE_SCS" 22 "FAULT_STATE_SOFTWARE_FAULT" 21 "FAULT_STATE_TRIP1_FAULT" 20 "FAULT_STATE_TRIP0_FAULT" 19 "FAULT_STATE_WDT" 18 "FAULT_STATE_CPU_FAULT" 17 "FAULT_STATE_DROOP_TRIP" 16 "FAULT_STATE_DROOP_GPU" 15 "FAULT_STATE_DROOP_CPUCL2" 14 "FAULT_STATE_DROOP_CPUCL1" 13 "FAULT_STATE_DROOP_CPUCL0" 12 "FAULT_STATE_MIF_ECC_AP" 11 "FAULT_STATE_MIF7_DFI_ALERT" 10 "FAULT_STATE_MIF6_DFI_ALERT" 9 "FAULT_STATE_MIF5_DFI_ALERT" 8 "FAULT_STATE_MIF4_DFI_ALERT" 7 "FAULT_STATE_MIF3_DFI_ALERT" 6 "FAULT_STATE_MIF2_DFI_ALERT" 5 "FAULT_STATE_MIF1_DFI_ALERT" 4 "FAULT_STATE_MIF0_DFI_ALERT" 3 "FAULT_STATE_MIF_ECC_UNCORRECTED" 2 "FAULT_STATE_MIF_ECC_CORRECTED" 1 "FAULT_STATE_GIC" 0 "FAULT_STATE_NONE" ;
VAL_ 1056 APS_secondaryTurbo 2 "TURBO_UNKNOWN" 1 "TURBO_B" 0 "TURBO_A" ;
VAL_ 1056 APS_B_arbState 7 "ARB_STATE_COUNT" 6 "ARB_STATE_UNKNOWN" 5 "ARB_STATE_MIA" 4 "ARB_STATE_FAULT" 3 "ARB_STATE_SECONDARY" 2 "ARB_STATE_PRIMARY" 1 "ARB_STATE_IDLE" 0 "ARB_STATE_INIT" ;
VAL_ 1056 APS_B_powerState 28 "POWER_STATE_AP_FORCE_POWER_OFF" 27 "POWER_STATE_AP_WAIT_FOR_SHUTDOWN_ABORT" 26 "POWER_STATE_AP_IN_LINUX" 25 "POWER_STATE_AP_IDLE" 24 "POWER_STATE_VEH_BOOTING" 23 "POWER_STATE_UNKNOWN" 22 "POWER_STATE_MIA" 21 "POWER_STATE_FAULT" 20 "POWER_STATE_SOC_OFF_ABORT" 19 "POWER_STATE_SOC_OFF" 18 "POWER_STATE_SOC_OFF_READY" 17 "POWER_STATE_AP_SUSPENDED" 16 "POWER_STATE_AP_OFF_ABORT_WAIT_FOR_ACK" 15 "POWER_STATE_AP_OFF_ABORT" 14 "POWER_STATE_AP_OFF_READY_WAIT_FOR_RESPONSE" 13 "POWER_STATE_AP_OFF_READY_WAIT_FOR_ACK" 12 "POWER_STATE_AP_OFF_READY" 11 "POWER_STATE_AP_OFF_PREPARE" 10 "POWER_STATE_AP_WAIT_FOR_SHUTDOWN" 9 "POWER_STATE_AP_ON" 8 "POWER_STATE_AP_IN_COREBOOT" 7 "POWER_STATE_AP_BOOTING" 6 "POWER_STATE_AP_ON_READY_WAIT_FOR_RESPONSE" 5 "POWER_STATE_AP_ON_READY_WAIT_FOR_ACK" 4 "POWER_STATE_AP_ON_READY" 3 "POWER_STATE_AP_ON_PREPARE_WAIT_FOR_RESPONSE" 2 "POWER_STATE_AP_ON_PREPARE_WAIT_FOR_ACK" 1 "POWER_STATE_AP_ON_PREPARE" 0 "POWER_STATE_IDLE" ;
VAL_ 1056 APS_B_sleepState 9 "SLEEP_STATE_COUNT" 8 "SLEEP_STATE_UNKNOWN" 7 "SLEEP_STATE_MIA" 6 "SLEEP_STATE_FAULT" 5 "SLEEP_STATE_ABORT" 4 "SLEEP_STATE_SLEEPING" 3 "SLEEP_STATE_GOING_TO_SLEEP" 2 "SLEEP_STATE_READY" 1 "SLEEP_STATE_WAIT_FOR_BUS_SILENCE" 0 "SLEEP_STATE_IDLE" ;
VAL_ 1056 APS_B_resetState 5 "RESET_STATE_COUNT" 4 "RESET_STATE_UNKNOWN" 3 "RESET_STATE_MIA" 2 "RESET_STATE_FAULT" 1 "RESET_STATE_RESETTING" 0 "RESET_STATE_NOT_RESETTING" ;
VAL_ 1056 APS_B_faultState 27 "FAULT_STATE_COUNT" 26 "FAULT_STATE_UNKNOWN" 25 "FAULT_STATE_MIA" 24 "FAULT_STATE_UNEXPECTED" 23 "FAULT_STATE_SCS" 22 "FAULT_STATE_SOFTWARE_FAULT" 21 "FAULT_STATE_TRIP1_FAULT" 20 "FAULT_STATE_TRIP0_FAULT" 19 "FAULT_STATE_WDT" 18 "FAULT_STATE_CPU_FAULT" 17 "FAULT_STATE_DROOP_TRIP" 16 "FAULT_STATE_DROOP_GPU" 15 "FAULT_STATE_DROOP_CPUCL2" 14 "FAULT_STATE_DROOP_CPUCL1" 13 "FAULT_STATE_DROOP_CPUCL0" 12 "FAULT_STATE_MIF_ECC_AP" 11 "FAULT_STATE_MIF7_DFI_ALERT" 10 "FAULT_STATE_MIF6_DFI_ALERT" 9 "FAULT_STATE_MIF5_DFI_ALERT" 8 "FAULT_STATE_MIF4_DFI_ALERT" 7 "FAULT_STATE_MIF3_DFI_ALERT" 6 "FAULT_STATE_MIF2_DFI_ALERT" 5 "FAULT_STATE_MIF1_DFI_ALERT" 4 "FAULT_STATE_MIF0_DFI_ALERT" 3 "FAULT_STATE_MIF_ECC_UNCORRECTED" 2 "FAULT_STATE_MIF_ECC_CORRECTED" 1 "FAULT_STATE_GIC" 0 "FAULT_STATE_NONE" ;
VAL_ 1056 APS_A_autosteerMonitorState 5 "AUTOSTEER_MONITOR_COUNT" 4 "AUTOSTEER_MONITOR_MIA" 3 "AUTOSTEER_MONITOR_TOI_TRIGGER" 2 "AUTOSTEER_MONITOR_WAIT_FOR_MIA" 1 "AUTOSTEER_MONITOR_ACTIVE" 0 "AUTOSTEER_MONITOR_IDLE" ;
VAL_ 1056 APS_B_autosteerMonitorState 5 "AUTOSTEER_MONITOR_COUNT" 4 "AUTOSTEER_MONITOR_MIA" 3 "AUTOSTEER_MONITOR_TOI_TRIGGER" 2 "AUTOSTEER_MONITOR_WAIT_FOR_MIA" 1 "AUTOSTEER_MONITOR_ACTIVE" 0 "AUTOSTEER_MONITOR_IDLE" ;
VAL_ 1056 APS_eplannerState 6 "APS_EPLANNER_NUM_STATES" 5 "APS_EPLANNER_STATE_EXECUTING_BOOT_FIXED_TRAJ" 4 "APS_EPLANNER_STATE_EXECUTING_FIXED_TRAJ" 3 "APS_EPLANNER_STATE_EXECUTING_PLAN_TRAJ" 2 "APS_EPLANNER_STATE_VALID_PLAN" 1 "APS_EPLANNER_STATE_READY" 0 "APS_EPLANNER_STATE_INIT" ;
VAL_ 1343 BMS_alertID 299 "a299_PowershareFailure" 291 "a291_SOC_Imbalance_By_Delta_Voltage_Over_Delta_SOC" 290 "d290_batteryPackTempSensorACircuitFailure" 289 "d289_batteryPackAOverTemperature" 288 "d288_batteryPackCellVoltageLow" 287 "d287_systemIsolationWarning" 286 "d286_dcLinkVoltageHigh" 285 "d285_packVoltageSensorACircuitFailure" 284 "d284_fastChargeNegContactorAStuckOpen" 283 "d283_fastChargeNegContactorAStuckClosed" 282 "d282_fastChargeNegContactorACircuitFailure" 281 "d281_fastChargePosContactorAStuckOpen" 280 "d280_fastChargePosContactorAStuckClosed" 279 "d279_fastChargePosContactorACircuitFailure" 278 "d278_packNegContactorAStuckClosed" 277 "d277_packNegContactorACircuitFailure" 276 "d276_packPosContactorAStuckClosed" 275 "d275_packPosContactorACircuitFailure" 274 "d274_packCurrentSensorACircuitFailure" 273 "d273_vcFrontCommsLost" 272 "d272_batteryPackSensorCommsLost" 271 "d271_batteryPackSensorFailure" 270 "d270_hvpCommsLost" 269 "d269_highVoltageFuseABlown" 268 "d268_hvpInvalidFirmwareConfig" 267 "d267_batteryPackCellVoltageSenseHarnessFailure" 266 "d266_energyReserveVoltageLow" 265 "d265_replaceBatteryPack" 264 "d264_invalidFirmwareConfig" 263 "d263_batterySystemCurrentHigh" 262 "d262_batteryPackLowStateOfCharge" 261 "d261_batteryPackCellVoltageHigh" 260 "d260_chargePortInterlockFailure" 259 "d259_highVoltageInterlockFailure" 258 "d258_externalIsolationFault" 257 "d257_internalIsolationFault" 256 "a256_SW_Low_Power_Warning" 255 "a255_EstimatedRangeReduced" 254 "a254_LdcsCacImbalance" 227 "a227_ExcessChargeCurrentInCharge" 221 "a221_PcsEmergencyShutdownRequested" 214 "a214_AcChargeAborted" 204 "a204_AcCpEmergencyShutdownRequested" 202 "a202_AcChargeFaulted" 201 "a201_SW_Brick_OV_During_Charge" 200 "a200_GridFollowFaulted" 199 "a199_GridFollowAborted" 198 "a198_SW_SOC_Abrupt_Change" 197 "a197_SW_High_SOC_OV" 196 "a196_SW_PackVoltageUnderThreshold" 195 "a195_SW_DeltaTempOverThreshold" 194 "a194_PowershareLimitViolation" 193 "a193_PowershareMaxBrickVoltageViolation" 192 "a192_PowershareExternalChargeRegulation" 191 "a191_PowershareMinVoltageViolation" 190 "a190_PowershareMaxVoltageViolation" 189 "a189_PowershareDischargeCurrentViolation" 188 "a188_PowershareChargeCurrentViolation" 187 "a187_RippleHeatingEmergencyShutdown" 186 "a186_RippleHeatingChargeFault" 185 "a185_LifeModel_CyclingDcrGrowth_Change" 184 "a184_LifeModel_CyclingLoss_Change" 183 "a183_LifeModel_StoDcrGrowth_Change" 182 "a182_LifeModel_NoCurrentLoss_Change" 181 "a181_SW_Shunt_Over_Temperature" 180 "a180_SW_ECU_reset_blocked" 179 "a179_HvpGpoRequestActive" 178 "a178_SW_Uncontrolled_Regen_PwrB" 177 "a177_SW_Energy_Buffer_Size" 176 "a176_SW_GracefulPowerOff" 175 "a175_Charge_Failure_External" 174 "a174_SW_Charge_Failure" 173 "a173_FullPackEnergyDegraded" 172 "a172_SW_Isolation_Failure_In_Drive_Warning" 171 "a171_SW_Stack_Voltage_Sense" 170 "a170_SW_Limp_Mode" 169 "a169_SW_FC_Pack_Weld" 168 "a168_SW_FC_Full_Weld" 167 "a167_SW_FC_Partial_Weld" 166 "a166_SW_Pack_Full_Weld" 165 "a165_SW_Pack_Partial_Weld" 164 "a164_SW_Uncontrolled_Regen" 163 "a163_GridFormAborted" 162 "a162_SW_No_Power_For_Support" 161 "a161_SW_BMB_Vref_warning" 160 "a160_SW_FC_Ctr_Clean_Failed" 159 "a159_SW_HVP_ECU_Error" 158 "a158_SW_HVP_HVI_Comms" 157 "a157_SW_Hist_Update_Missed" 156 "a156_SW_BMB_Vref_bad" 155 "a155_SW_Weak_short_impedence" 154 "a154_SW_Brick_OV_Warning_Stop_Charge" 153 "a153_GridFormFaulted" 152 "a152_Isolation_In_Dc_Charge" 151 "a151_SW_external_isolation" 150 "a150_SW_Missing_Part_Number" 149 "a149_SW_Missing_Config_Block" 148 "a148_SW_Unsupported_BMB_ASIC_Type" 147 "a147_SW_SOC_High_Ah_Error" 146 "a146_SW_Brick_Overdischarged" 145 "a145_SW_SOC_Change" 144 "a144_Hvp_Config_Mismatch" 143 "a143_SW_CAC_Change" 142 "a142_SW_Isolation_Degradation" 141 "a141_SW_BMB_Status_Warning" 140 "a140_HW_BMB_Status_Fault" 139 "a139_SW_DC_Link_V_Irrational" 138 "a138_SW_Brick_OV_Warning" 137 "a137_SW_Brick_UV_Warning" 136 "a136_SW_Module_OT_Warning" 135 "a135_HW_BMB_Diagnostics_Failure" 134 "a134_SW_Delayed_Ctr_Off" 133 "a133_IO_CAN_Bus_Off" 132 "a132_HW_BMB_OTP_Uncorrctbl" 131 "a131_Bleed_FET_Failure" 130 "a130_IO_CAN_Error" 129 "a129_SW_VSH_Failure" 128 "a128_SW_shunt_MIA" 127 "a127_SW_shunt_SNA" 126 "a126_SW_Thermistor_Failure" 124 "a124_Battery_Coolant_Flood" 123 "a123_SW_Internal_Isolation" 122 "a122_SW_BMS_Therm_Irrational" 121 "a121_SW_NVRAM_Config_Error" 120 "a120_SW_Delta_SOC_User_Warning" 119 "a119_Fast_Open_Vsh_Detected" 118 "a118_SW_Delta_SOC_Weak_Short_Warning" 117 "a117_SW_Delta_SOC_Weak_Short" 115 "a115_Energy_Rubberbanding_Reset" 112 "a112_LifeModel_Discontinuity" 111 "a111_LifeModel_Spread_Change" 110 "a110_LifeModel_AvgOffset_Change" 109 "a109_HW_BMB_Mute_Status_Mismatch" 108 "a108_SW_BMB_Device_OT" 107 "a107_SW_Stack_Voltage_MIA" 106 "a106_SW_All_Module_Tsense" 105 "a105_SW_One_Module_Tsense" 100 "a100_ThermalEventSuspected" 99 "a099_SW_BMB_Communication" 98 "a098_SW_BMB_Data_Integrity_Loss" 97 "a097_SW_BMB_Over_CAN_Communication" 95 "a095_SW_UI_MIA" 94 "a094_SW_Drive_Inverter_MIA" 92 "a092_SW_ChargePort_Mia_On_Hvs" 91 "a091_SW_ChargePort_MIA" 90 "a090_SW_Gateway_MIA" 89 "a089_SW_VcFront_MIA" 88 "a088_SW_VcFront_MIA_InDrive" 87 "a087_SW_Feim_Test_Blocked" 86 "a086_SW_FC_Contactor_Mismatch" 85 "a085_SW_Pack_Contactor_Mismatch" 84 "a084_SW_Sleep_Wake_Aborted" 83 "a083_SW_Ctr_Close_Failure" 82 "a082_SW_Ctr_Force_Open" 81 "a081_SW_Ctr_Close_Blocked" 80 "a080_SW_Pack_Ctr_Impedance" 79 "a079_Max_Charge_Level_Exceeded" 78 "a078_Rapid_Dch_While_Charging" 77 "a077_SW_Charger_Regulation" 76 "a076_SW_Dch_While_Charging" 75 "a075_SW_Chg_Disable_Failure" 74 "a074_Max_Charge_Level_Reduced" 73 "a073_Unexpected_Loss_Of_Lv" 72 "a072_Module_Brick_Split" 71 "a071_SW_SM_TransCon_Not_Met" 70 "a070_BrickV_Imbalance_Limiting" 69 "a069_SW_Low_Power" 68 "a068_CAC_Imbalance_Limp" 67 "a067_CAC_Imbalance_Limiting" 66 "a066_SOC_Imbalance_Warning" 65 "a065_SW_CAC_Imbalance" 64 "a064_SW_SOC_Imbalance" 63 "a063_SW_ChargePort_Fault" 62 "a062_SW_BrickV_Imbalance" 61 "a061_SW_BrickV_Change" 60 "a060_SW_Leakage_Test_Failure" 59 "a059_SW_Pack_Voltage_Sensing" 58 "a058_SW_Bandolier_Model_Reset" 57 "a057_SW_Bandolier_Model_Warning" 56 "a056_SW_Standby_Supply_Fault" 55 "a055_SW_HvChain_Model_Fault" 54 "a054_SW_Ver_Supply_Fault" 52 "a052_SW_PCS_MIA" 51 "a051_SW_HVC_Vref_Bad" 50 "a050_SW_Brick_Voltage_MIA" 49 "a049_SW_Thermal_Event" 48 "a048_SW_Watch_Dog_Warning" 47 "a047_SW_Task_Stack_Overflow" 46 "a046_SW_Task_Stack_Usage" 45 "a045_SW_Exception" 44 "a044_SW_Assertion" 43 "a043_SW_Watch_Dog_Reset" 42 "a042_SW_MPU_Error" 41 "a041_SW_Destructive_Reset_Source" 40 "a040_SW_Watch_Dog_HW_Triggered" 39 "a039_SW_DC_Link_Over_Voltage" 37 "a037_SW_Flood_Port_Open" 36 "a036_SW_HvpHvilFault" 35 "a035_SW_Isolation" 34 "a034_SW_Passive_Isolation" 33 "a033_VoltageDeviation" 32 "a032_VoltageLoss" 31 "a031_AlertsSetDuringSleep" 30 "a030_Impedance_Deviation" 29 "a029_dSoc_Limiting" 28 "a028_ShuntAsicCurrentOffsetDeviation" 27 "a027_SW_Repeated_Isolation_Failure_In_Drive" 26 "a026_SW_HFCurrent_Anomaly" 25 "a025_SW_PwrBalance_Anomaly" 24 "a024_SW_Islanded_Brick" 23 "a023_SW_Stack_OV" 22 "a022_SW_Over_Current" 21 "a021_SW_Dr_Limits_Regulation" 20 "a020_SW_Brick_Instability" 19 "a019_SW_Module_OT" 18 "a018_SW_Brick_UV" 17 "a017_SW_Brick_OV" 16 "a016_Pack_Module_Id_Mismatch" 4 "a004_Cal_Vs_Serial_Birth_Date_Mismatch" 3 "a003_SW_Pack_Birth_Date_Missing" 2 "a002_Pack_Performance_Config_Mismatch" 1 "a001_Pack_Config_Mismatch" 0 "ALERT_DO_NOT_USE_ZERO" ;
VAL_ 1343 BMS_alertSet 1 "SET" 0 "CLEARED" ;
VAL_ 1343 BMS_a001_gatewayPackEnergy 2 "MR" 1 "LR" 0 "SR" ;
VAL_ 1343 BMS_a001_expectedPackEnergy 2 "MR" 1 "LR" 0 "SR" ;
VAL_ 1343 BMS_a002_gatewayPackPerformanceD 5 "PACK_POWER_DEVIATION_2" 4 "PACK_MASS_DEVIATION_2" 3 "PACK_STRUCTURAL_DEVIATION_1" 2 "PACK_POWER_DEVIATION_1" 1 "PACK_MASS_DEVIATION_1" 0 "NO_DEVIATION" ;
VAL_ 1343 BMS_a002_expectedPackPerformance 5 "PACK_POWER_DEVIATION_2" 4 "PACK_MASS_DEVIATION_2" 3 "PACK_STRUCTURAL_DEVIATION_1" 2 "PACK_POWER_DEVIATION_1" 1 "PACK_MASS_DEVIATION_1" 0 "NO_DEVIATION" ;
VAL_ 1343 BMS_a035_mode 4 "VOLTAGE_SETTLING_MODE" 3 "FEIM_POSITIVE_MODE" 2 "FEIM_NEGATIVE_MODE" 1 "VEHICLE_ISOLATION_MODE" 0 "MODE_RESET" ;
VAL_ 1343 BMS_a039_packContactorState 9 "NEGATIVE_CLOSED" 8 "POSITIVE_CLOSED" 7 "WELDED" 6 "PARTIAL_WELD" 5 "CLOSED" 4 "OPENING" 3 "BLOCKED" 2 "CLOSING" 1 "OPEN" 0 "SNA" ;
VAL_ 1343 BMS_a039_state 10 "DIAG" 9 "SNA" 8 "TEST" 7 "WELD" 6 "FAULT" 5 "CLEAR_FAULT" 4 "FEIM" 3 "CHARGE" 2 "SUPPORT" 1 "DRIVE" 0 "STANDBY" ;
VAL_ 1343 BMS_a041_resetType 8 "SWT1_RES" 7 "SWT0_RES" 6 "SUF" 5 "FUNC_ESC" 4 "SSCM_SEC" 3 "SOFT_DEST" 2 "HSM_DEST" 1 "POR" 0 "NONE" ;
VAL_ 1343 BMS_a062_state 10 "DIAG" 9 "SNA" 8 "TEST" 7 "WELD" 6 "FAULT" 5 "CLEAR_FAULT" 4 "FEIM" 3 "CHARGE" 2 "SUPPORT" 1 "DRIVE" 0 "STANDBY" ;
VAL_ 1343 BMS_a070_state 10 "DIAG" 9 "SNA" 8 "TEST" 7 "WELD" 6 "FAULT" 5 "CLEAR_FAULT" 4 "FEIM" 3 "CHARGE" 2 "SUPPORT" 1 "DRIVE" 0 "STANDBY" ;
VAL_ 1343 BMS_a071_stateRequest 10 "DIAG" 9 "SNA" 8 "TEST" 7 "WELD" 6 "FAULT" 5 "CLEAR_FAULT" 4 "FEIM" 3 "CHARGE" 2 "SUPPORT" 1 "DRIVE" 0 "STANDBY" ;
VAL_ 1343 BMS_a071_state 10 "DIAG" 9 "SNA" 8 "TEST" 7 "WELD" 6 "FAULT" 5 "CLEAR_FAULT" 4 "FEIM" 3 "CHARGE" 2 "SUPPORT" 1 "DRIVE" 0 "STANDBY" ;
VAL_ 1343 BMS_a075_chargeType 1 "AC_CHARGE_SESSION" 0 "DC_CHARGE_SESSION" ;
VAL_ 1343 BMS_a077_chargeErrType 1 "OVERCHARGE" 0 "CURRENT_HIGH" ;
VAL_ 1343 BMS_a078_peakDchInChg -32768 "SNA" ;
VAL_ 1343 BMS_a081_stateRequest 10 "DIAG" 9 "SNA" 8 "TEST" 7 "WELD" 6 "FAULT" 5 "CLEAR_FAULT" 4 "FEIM" 3 "CHARGE" 2 "SUPPORT" 1 "DRIVE" 0 "STANDBY" ;
VAL_ 1343 BMS_a081_firstBlockingAlertId 299 "a299_PowershareFailure" 291 "a291_SOC_Imbalance_By_Delta_Voltage_Over_Delta_SOC" 290 "d290_batteryPackTempSensorACircuitFailure" 289 "d289_batteryPackAOverTemperature" 288 "d288_batteryPackCellVoltageLow" 287 "d287_systemIsolationWarning" 286 "d286_dcLinkVoltageHigh" 285 "d285_packVoltageSensorACircuitFailure" 284 "d284_fastChargeNegContactorAStuckOpen" 283 "d283_fastChargeNegContactorAStuckClosed" 282 "d282_fastChargeNegContactorACircuitFailure" 281 "d281_fastChargePosContactorAStuckOpen" 280 "d280_fastChargePosContactorAStuckClosed" 279 "d279_fastChargePosContactorACircuitFailure" 278 "d278_packNegContactorAStuckClosed" 277 "d277_packNegContactorACircuitFailure" 276 "d276_packPosContactorAStuckClosed" 275 "d275_packPosContactorACircuitFailure" 274 "d274_packCurrentSensorACircuitFailure" 273 "d273_vcFrontCommsLost" 272 "d272_batteryPackSensorCommsLost" 271 "d271_batteryPackSensorFailure" 270 "d270_hvpCommsLost" 269 "d269_highVoltageFuseABlown" 268 "d268_hvpInvalidFirmwareConfig" 267 "d267_batteryPackCellVoltageSenseHarnessFailure" 266 "d266_energyReserveVoltageLow" 265 "d265_replaceBatteryPack" 264 "d264_invalidFirmwareConfig" 263 "d263_batterySystemCurrentHigh" 262 "d262_batteryPackLowStateOfCharge" 261 "d261_batteryPackCellVoltageHigh" 260 "d260_chargePortInterlockFailure" 259 "d259_highVoltageInterlockFailure" 258 "d258_externalIsolationFault" 257 "d257_internalIsolationFault" 256 "a256_SW_Low_Power_Warning" 255 "a255_EstimatedRangeReduced" 254 "a254_LdcsCacImbalance" 227 "a227_ExcessChargeCurrentInCharge" 221 "a221_PcsEmergencyShutdownRequested" 214 "a214_AcChargeAborted" 204 "a204_AcCpEmergencyShutdownRequested" 202 "a202_AcChargeFaulted" 201 "a201_SW_Brick_OV_During_Charge" 200 "a200_GridFollowFaulted" 199 "a199_GridFollowAborted" 198 "a198_SW_SOC_Abrupt_Change" 197 "a197_SW_High_SOC_OV" 196 "a196_SW_PackVoltageUnderThreshold" 195 "a195_SW_DeltaTempOverThreshold" 194 "a194_PowershareLimitViolation" 193 "a193_PowershareMaxBrickVoltageViolation" 192 "a192_PowershareExternalChargeRegulation" 191 "a191_PowershareMinVoltageViolation" 190 "a190_PowershareMaxVoltageViolation" 189 "a189_PowershareDischargeCurrentViolation" 188 "a188_PowershareChargeCurrentViolation" 187 "a187_RippleHeatingEmergencyShutdown" 186 "a186_RippleHeatingChargeFault" 185 "a185_LifeModel_CyclingDcrGrowth_Change" 184 "a184_LifeModel_CyclingLoss_Change" 183 "a183_LifeModel_StoDcrGrowth_Change" 182 "a182_LifeModel_NoCurrentLoss_Change" 181 "a181_SW_Shunt_Over_Temperature" 180 "a180_SW_ECU_reset_blocked" 179 "a179_HvpGpoRequestActive" 178 "a178_SW_Uncontrolled_Regen_PwrB" 177 "a177_SW_Energy_Buffer_Size" 176 "a176_SW_GracefulPowerOff" 175 "a175_Charge_Failure_External" 174 "a174_SW_Charge_Failure" 173 "a173_FullPackEnergyDegraded" 172 "a172_SW_Isolation_Failure_In_Drive_Warning" 171 "a171_SW_Stack_Voltage_Sense" 170 "a170_SW_Limp_Mode" 169 "a169_SW_FC_Pack_Weld" 168 "a168_SW_FC_Full_Weld" 167 "a167_SW_FC_Partial_Weld" 166 "a166_SW_Pack_Full_Weld" 165 "a165_SW_Pack_Partial_Weld" 164 "a164_SW_Uncontrolled_Regen" 163 "a163_GridFormAborted" 162 "a162_SW_No_Power_For_Support" 161 "a161_SW_BMB_Vref_warning" 160 "a160_SW_FC_Ctr_Clean_Failed" 159 "a159_SW_HVP_ECU_Error" 158 "a158_SW_HVP_HVI_Comms" 157 "a157_SW_Hist_Update_Missed" 156 "a156_SW_BMB_Vref_bad" 155 "a155_SW_Weak_short_impedence" 154 "a154_SW_Brick_OV_Warning_Stop_Charge" 153 "a153_GridFormFaulted" 152 "a152_Isolation_In_Dc_Charge" 151 "a151_SW_external_isolation" 150 "a150_SW_Missing_Part_Number" 149 "a149_SW_Missing_Config_Block" 148 "a148_SW_Unsupported_BMB_ASIC_Type" 147 "a147_SW_SOC_High_Ah_Error" 146 "a146_SW_Brick_Overdischarged" 145 "a145_SW_SOC_Change" 144 "a144_Hvp_Config_Mismatch" 143 "a143_SW_CAC_Change" 142 "a142_SW_Isolation_Degradation" 141 "a141_SW_BMB_Status_Warning" 140 "a140_HW_BMB_Status_Fault" 139 "a139_SW_DC_Link_V_Irrational" 138 "a138_SW_Brick_OV_Warning" 137 "a137_SW_Brick_UV_Warning" 136 "a136_SW_Module_OT_Warning" 135 "a135_HW_BMB_Diagnostics_Failure" 134 "a134_SW_Delayed_Ctr_Off" 133 "a133_IO_CAN_Bus_Off" 132 "a132_HW_BMB_OTP_Uncorrctbl" 131 "a131_Bleed_FET_Failure" 130 "a130_IO_CAN_Error" 129 "a129_SW_VSH_Failure" 128 "a128_SW_shunt_MIA" 127 "a127_SW_shunt_SNA" 126 "a126_SW_Thermistor_Failure" 124 "a124_Battery_Coolant_Flood" 123 "a123_SW_Internal_Isolation" 122 "a122_SW_BMS_Therm_Irrational" 121 "a121_SW_NVRAM_Config_Error" 120 "a120_SW_Delta_SOC_User_Warning" 119 "a119_Fast_Open_Vsh_Detected" 118 "a118_SW_Delta_SOC_Weak_Short_Warning" 117 "a117_SW_Delta_SOC_Weak_Short" 115 "a115_Energy_Rubberbanding_Reset" 112 "a112_LifeModel_Discontinuity" 111 "a111_LifeModel_Spread_Change" 110 "a110_LifeModel_AvgOffset_Change" 109 "a109_HW_BMB_Mute_Status_Mismatch" 108 "a108_SW_BMB_Device_OT" 107 "a107_SW_Stack_Voltage_MIA" 106 "a106_SW_All_Module_Tsense" 105 "a105_SW_One_Module_Tsense" 100 "a100_ThermalEventSuspected" 99 "a099_SW_BMB_Communication" 98 "a098_SW_BMB_Data_Integrity_Loss" 97 "a097_SW_BMB_Over_CAN_Communication" 95 "a095_SW_UI_MIA" 94 "a094_SW_Drive_Inverter_MIA" 92 "a092_SW_ChargePort_Mia_On_Hvs" 91 "a091_SW_ChargePort_MIA" 90 "a090_SW_Gateway_MIA" 89 "a089_SW_VcFront_MIA" 88 "a088_SW_VcFront_MIA_InDrive" 87 "a087_SW_Feim_Test_Blocked" 86 "a086_SW_FC_Contactor_Mismatch" 85 "a085_SW_Pack_Contactor_Mismatch" 84 "a084_SW_Sleep_Wake_Aborted" 83 "a083_SW_Ctr_Close_Failure" 82 "a082_SW_Ctr_Force_Open" 81 "a081_SW_Ctr_Close_Blocked" 80 "a080_SW_Pack_Ctr_Impedance" 79 "a079_Max_Charge_Level_Exceeded" 78 "a078_Rapid_Dch_While_Charging" 77 "a077_SW_Charger_Regulation" 76 "a076_SW_Dch_While_Charging" 75 "a075_SW_Chg_Disable_Failure" 74 "a074_Max_Charge_Level_Reduced" 73 "a073_Unexpected_Loss_Of_Lv" 72 "a072_Module_Brick_Split" 71 "a071_SW_SM_TransCon_Not_Met" 70 "a070_BrickV_Imbalance_Limiting" 69 "a069_SW_Low_Power" 68 "a068_CAC_Imbalance_Limp" 67 "a067_CAC_Imbalance_Limiting" 66 "a066_SOC_Imbalance_Warning" 65 "a065_SW_CAC_Imbalance" 64 "a064_SW_SOC_Imbalance" 63 "a063_SW_ChargePort_Fault" 62 "a062_SW_BrickV_Imbalance" 61 "a061_SW_BrickV_Change" 60 "a060_SW_Leakage_Test_Failure" 59 "a059_SW_Pack_Voltage_Sensing" 58 "a058_SW_Bandolier_Model_Reset" 57 "a057_SW_Bandolier_Model_Warning" 56 "a056_SW_Standby_Supply_Fault" 55 "a055_SW_HvChain_Model_Fault" 54 "a054_SW_Ver_Supply_Fault" 52 "a052_SW_PCS_MIA" 51 "a051_SW_HVC_Vref_Bad" 50 "a050_SW_Brick_Voltage_MIA" 49 "a049_SW_Thermal_Event" 48 "a048_SW_Watch_Dog_Warning" 47 "a047_SW_Task_Stack_Overflow" 46 "a046_SW_Task_Stack_Usage" 45 "a045_SW_Exception" 44 "a044_SW_Assertion" 43 "a043_SW_Watch_Dog_Reset" 42 "a042_SW_MPU_Error" 41 "a041_SW_Destructive_Reset_Source" 40 "a040_SW_Watch_Dog_HW_Triggered" 39 "a039_SW_DC_Link_Over_Voltage" 37 "a037_SW_Flood_Port_Open" 36 "a036_SW_HvpHvilFault" 35 "a035_SW_Isolation" 34 "a034_SW_Passive_Isolation" 33 "a033_VoltageDeviation" 32 "a032_VoltageLoss" 31 "a031_AlertsSetDuringSleep" 30 "a030_Impedance_Deviation" 29 "a029_dSoc_Limiting" 28 "a028_ShuntAsicCurrentOffsetDeviation" 27 "a027_SW_Repeated_Isolation_Failure_In_Drive" 26 "a026_SW_HFCurrent_Anomaly" 25 "a025_SW_PwrBalance_Anomaly" 24 "a024_SW_Islanded_Brick" 23 "a023_SW_Stack_OV" 22 "a022_SW_Over_Current" 21 "a021_SW_Dr_Limits_Regulation" 20 "a020_SW_Brick_Instability" 19 "a019_SW_Module_OT" 18 "a018_SW_Brick_UV" 17 "a017_SW_Brick_OV" 16 "a016_Pack_Module_Id_Mismatch" 4 "a004_Cal_Vs_Serial_Birth_Date_Mismatch" 3 "a003_SW_Pack_Birth_Date_Missing" 2 "a002_Pack_Performance_Config_Mismatch" 1 "a001_Pack_Config_Mismatch" 0 "ALERT_DO_NOT_USE_ZERO" ;
VAL_ 1343 BMS_a081_secondBlockingAlertId 299 "a299_PowershareFailure" 291 "a291_SOC_Imbalance_By_Delta_Voltage_Over_Delta_SOC" 290 "d290_batteryPackTempSensorACircuitFailure" 289 "d289_batteryPackAOverTemperature" 288 "d288_batteryPackCellVoltageLow" 287 "d287_systemIsolationWarning" 286 "d286_dcLinkVoltageHigh" 285 "d285_packVoltageSensorACircuitFailure" 284 "d284_fastChargeNegContactorAStuckOpen" 283 "d283_fastChargeNegContactorAStuckClosed" 282 "d282_fastChargeNegContactorACircuitFailure" 281 "d281_fastChargePosContactorAStuckOpen" 280 "d280_fastChargePosContactorAStuckClosed" 279 "d279_fastChargePosContactorACircuitFailure" 278 "d278_packNegContactorAStuckClosed" 277 "d277_packNegContactorACircuitFailure" 276 "d276_packPosContactorAStuckClosed" 275 "d275_packPosContactorACircuitFailure" 274 "d274_packCurrentSensorACircuitFailure" 273 "d273_vcFrontCommsLost" 272 "d272_batteryPackSensorCommsLost" 271 "d271_batteryPackSensorFailure" 270 "d270_hvpCommsLost" 269 "d269_highVoltageFuseABlown" 268 "d268_hvpInvalidFirmwareConfig" 267 "d267_batteryPackCellVoltageSenseHarnessFailure" 266 "d266_energyReserveVoltageLow" 265 "d265_replaceBatteryPack" 264 "d264_invalidFirmwareConfig" 263 "d263_batterySystemCurrentHigh" 262 "d262_batteryPackLowStateOfCharge" 261 "d261_batteryPackCellVoltageHigh" 260 "d260_chargePortInterlockFailure" 259 "d259_highVoltageInterlockFailure" 258 "d258_externalIsolationFault" 257 "d257_internalIsolationFault" 256 "a256_SW_Low_Power_Warning" 255 "a255_EstimatedRangeReduced" 254 "a254_LdcsCacImbalance" 227 "a227_ExcessChargeCurrentInCharge" 221 "a221_PcsEmergencyShutdownRequested" 214 "a214_AcChargeAborted" 204 "a204_AcCpEmergencyShutdownRequested" 202 "a202_AcChargeFaulted" 201 "a201_SW_Brick_OV_During_Charge" 200 "a200_GridFollowFaulted" 199 "a199_GridFollowAborted" 198 "a198_SW_SOC_Abrupt_Change" 197 "a197_SW_High_SOC_OV" 196 "a196_SW_PackVoltageUnderThreshold" 195 "a195_SW_DeltaTempOverThreshold" 194 "a194_PowershareLimitViolation" 193 "a193_PowershareMaxBrickVoltageViolation" 192 "a192_PowershareExternalChargeRegulation" 191 "a191_PowershareMinVoltageViolation" 190 "a190_PowershareMaxVoltageViolation" 189 "a189_PowershareDischargeCurrentViolation" 188 "a188_PowershareChargeCurrentViolation" 187 "a187_RippleHeatingEmergencyShutdown" 186 "a186_RippleHeatingChargeFault" 185 "a185_LifeModel_CyclingDcrGrowth_Change" 184 "a184_LifeModel_CyclingLoss_Change" 183 "a183_LifeModel_StoDcrGrowth_Change" 182 "a182_LifeModel_NoCurrentLoss_Change" 181 "a181_SW_Shunt_Over_Temperature" 180 "a180_SW_ECU_reset_blocked" 179 "a179_HvpGpoRequestActive" 178 "a178_SW_Uncontrolled_Regen_PwrB" 177 "a177_SW_Energy_Buffer_Size" 176 "a176_SW_GracefulPowerOff" 175 "a175_Charge_Failure_External" 174 "a174_SW_Charge_Failure" 173 "a173_FullPackEnergyDegraded" 172 "a172_SW_Isolation_Failure_In_Drive_Warning" 171 "a171_SW_Stack_Voltage_Sense" 170 "a170_SW_Limp_Mode" 169 "a169_SW_FC_Pack_Weld" 168 "a168_SW_FC_Full_Weld" 167 "a167_SW_FC_Partial_Weld" 166 "a166_SW_Pack_Full_Weld" 165 "a165_SW_Pack_Partial_Weld" 164 "a164_SW_Uncontrolled_Regen" 163 "a163_GridFormAborted" 162 "a162_SW_No_Power_For_Support" 161 "a161_SW_BMB_Vref_warning" 160 "a160_SW_FC_Ctr_Clean_Failed" 159 "a159_SW_HVP_ECU_Error" 158 "a158_SW_HVP_HVI_Comms" 157 "a157_SW_Hist_Update_Missed" 156 "a156_SW_BMB_Vref_bad" 155 "a155_SW_Weak_short_impedence" 154 "a154_SW_Brick_OV_Warning_Stop_Charge" 153 "a153_GridFormFaulted" 152 "a152_Isolation_In_Dc_Charge" 151 "a151_SW_external_isolation" 150 "a150_SW_Missing_Part_Number" 149 "a149_SW_Missing_Config_Block" 148 "a148_SW_Unsupported_BMB_ASIC_Type" 147 "a147_SW_SOC_High_Ah_Error" 146 "a146_SW_Brick_Overdischarged" 145 "a145_SW_SOC_Change" 144 "a144_Hvp_Config_Mismatch" 143 "a143_SW_CAC_Change" 142 "a142_SW_Isolation_Degradation" 141 "a141_SW_BMB_Status_Warning" 140 "a140_HW_BMB_Status_Fault" 139 "a139_SW_DC_Link_V_Irrational" 138 "a138_SW_Brick_OV_Warning" 137 "a137_SW_Brick_UV_Warning" 136 "a136_SW_Module_OT_Warning" 135 "a135_HW_BMB_Diagnostics_Failure" 134 "a134_SW_Delayed_Ctr_Off" 133 "a133_IO_CAN_Bus_Off" 132 "a132_HW_BMB_OTP_Uncorrctbl" 131 "a131_Bleed_FET_Failure" 130 "a130_IO_CAN_Error" 129 "a129_SW_VSH_Failure" 128 "a128_SW_shunt_MIA" 127 "a127_SW_shunt_SNA" 126 "a126_SW_Thermistor_Failure" 124 "a124_Battery_Coolant_Flood" 123 "a123_SW_Internal_Isolation" 122 "a122_SW_BMS_Therm_Irrational" 121 "a121_SW_NVRAM_Config_Error" 120 "a120_SW_Delta_SOC_User_Warning" 119 "a119_Fast_Open_Vsh_Detected" 118 "a118_SW_Delta_SOC_Weak_Short_Warning" 117 "a117_SW_Delta_SOC_Weak_Short" 115 "a115_Energy_Rubberbanding_Reset" 112 "a112_LifeModel_Discontinuity" 111 "a111_LifeModel_Spread_Change" 110 "a110_LifeModel_AvgOffset_Change" 109 "a109_HW_BMB_Mute_Status_Mismatch" 108 "a108_SW_BMB_Device_OT" 107 "a107_SW_Stack_Voltage_MIA" 106 "a106_SW_All_Module_Tsense" 105 "a105_SW_One_Module_Tsense" 100 "a100_ThermalEventSuspected" 99 "a099_SW_BMB_Communication" 98 "a098_SW_BMB_Data_Integrity_Loss" 97 "a097_SW_BMB_Over_CAN_Communication" 95 "a095_SW_UI_MIA" 94 "a094_SW_Drive_Inverter_MIA" 92 "a092_SW_ChargePort_Mia_On_Hvs" 91 "a091_SW_ChargePort_MIA" 90 "a090_SW_Gateway_MIA" 89 "a089_SW_VcFront_MIA" 88 "a088_SW_VcFront_MIA_InDrive" 87 "a087_SW_Feim_Test_Blocked" 86 "a086_SW_FC_Contactor_Mismatch" 85 "a085_SW_Pack_Contactor_Mismatch" 84 "a084_SW_Sleep_Wake_Aborted" 83 "a083_SW_Ctr_Close_Failure" 82 "a082_SW_Ctr_Force_Open" 81 "a081_SW_Ctr_Close_Blocked" 80 "a080_SW_Pack_Ctr_Impedance" 79 "a079_Max_Charge_Level_Exceeded" 78 "a078_Rapid_Dch_While_Charging" 77 "a077_SW_Charger_Regulation" 76 "a076_SW_Dch_While_Charging" 75 "a075_SW_Chg_Disable_Failure" 74 "a074_Max_Charge_Level_Reduced" 73 "a073_Unexpected_Loss_Of_Lv" 72 "a072_Module_Brick_Split" 71 "a071_SW_SM_TransCon_Not_Met" 70 "a070_BrickV_Imbalance_Limiting" 69 "a069_SW_Low_Power" 68 "a068_CAC_Imbalance_Limp" 67 "a067_CAC_Imbalance_Limiting" 66 "a066_SOC_Imbalance_Warning" 65 "a065_SW_CAC_Imbalance" 64 "a064_SW_SOC_Imbalance" 63 "a063_SW_ChargePort_Fault" 62 "a062_SW_BrickV_Imbalance" 61 "a061_SW_BrickV_Change" 60 "a060_SW_Leakage_Test_Failure" 59 "a059_SW_Pack_Voltage_Sensing" 58 "a058_SW_Bandolier_Model_Reset" 57 "a057_SW_Bandolier_Model_Warning" 56 "a056_SW_Standby_Supply_Fault" 55 "a055_SW_HvChain_Model_Fault" 54 "a054_SW_Ver_Supply_Fault" 52 "a052_SW_PCS_MIA" 51 "a051_SW_HVC_Vref_Bad" 50 "a050_SW_Brick_Voltage_MIA" 49 "a049_SW_Thermal_Event" 48 "a048_SW_Watch_Dog_Warning" 47 "a047_SW_Task_Stack_Overflow" 46 "a046_SW_Task_Stack_Usage" 45 "a045_SW_Exception" 44 "a044_SW_Assertion" 43 "a043_SW_Watch_Dog_Reset" 42 "a042_SW_MPU_Error" 41 "a041_SW_Destructive_Reset_Source" 40 "a040_SW_Watch_Dog_HW_Triggered" 39 "a039_SW_DC_Link_Over_Voltage" 37 "a037_SW_Flood_Port_Open" 36 "a036_SW_HvpHvilFault" 35 "a035_SW_Isolation" 34 "a034_SW_Passive_Isolation" 33 "a033_VoltageDeviation" 32 "a032_VoltageLoss" 31 "a031_AlertsSetDuringSleep" 30 "a030_Impedance_Deviation" 29 "a029_dSoc_Limiting" 28 "a028_ShuntAsicCurrentOffsetDeviation" 27 "a027_SW_Repeated_Isolation_Failure_In_Drive" 26 "a026_SW_HFCurrent_Anomaly" 25 "a025_SW_PwrBalance_Anomaly" 24 "a024_SW_Islanded_Brick" 23 "a023_SW_Stack_OV" 22 "a022_SW_Over_Current" 21 "a021_SW_Dr_Limits_Regulation" 20 "a020_SW_Brick_Instability" 19 "a019_SW_Module_OT" 18 "a018_SW_Brick_UV" 17 "a017_SW_Brick_OV" 16 "a016_Pack_Module_Id_Mismatch" 4 "a004_Cal_Vs_Serial_Birth_Date_Mismatch" 3 "a003_SW_Pack_Birth_Date_Missing" 2 "a002_Pack_Performance_Config_Mismatch" 1 "a001_Pack_Config_Mismatch" 0 "ALERT_DO_NOT_USE_ZERO" ;
VAL_ 1343 BMS_a081_thirdBlockingAlertId 299 "a299_PowershareFailure" 291 "a291_SOC_Imbalance_By_Delta_Voltage_Over_Delta_SOC" 290 "d290_batteryPackTempSensorACircuitFailure" 289 "d289_batteryPackAOverTemperature" 288 "d288_batteryPackCellVoltageLow" 287 "d287_systemIsolationWarning" 286 "d286_dcLinkVoltageHigh" 285 "d285_packVoltageSensorACircuitFailure" 284 "d284_fastChargeNegContactorAStuckOpen" 283 "d283_fastChargeNegContactorAStuckClosed" 282 "d282_fastChargeNegContactorACircuitFailure" 281 "d281_fastChargePosContactorAStuckOpen" 280 "d280_fastChargePosContactorAStuckClosed" 279 "d279_fastChargePosContactorACircuitFailure" 278 "d278_packNegContactorAStuckClosed" 277 "d277_packNegContactorACircuitFailure" 276 "d276_packPosContactorAStuckClosed" 275 "d275_packPosContactorACircuitFailure" 274 "d274_packCurrentSensorACircuitFailure" 273 "d273_vcFrontCommsLost" 272 "d272_batteryPackSensorCommsLost" 271 "d271_batteryPackSensorFailure" 270 "d270_hvpCommsLost" 269 "d269_highVoltageFuseABlown" 268 "d268_hvpInvalidFirmwareConfig" 267 "d267_batteryPackCellVoltageSenseHarnessFailure" 266 "d266_energyReserveVoltageLow" 265 "d265_replaceBatteryPack" 264 "d264_invalidFirmwareConfig" 263 "d263_batterySystemCurrentHigh" 262 "d262_batteryPackLowStateOfCharge" 261 "d261_batteryPackCellVoltageHigh" 260 "d260_chargePortInterlockFailure" 259 "d259_highVoltageInterlockFailure" 258 "d258_externalIsolationFault" 257 "d257_internalIsolationFault" 256 "a256_SW_Low_Power_Warning" 255 "a255_EstimatedRangeReduced" 254 "a254_LdcsCacImbalance" 227 "a227_ExcessChargeCurrentInCharge" 221 "a221_PcsEmergencyShutdownRequested" 214 "a214_AcChargeAborted" 204 "a204_AcCpEmergencyShutdownRequested" 202 "a202_AcChargeFaulted" 201 "a201_SW_Brick_OV_During_Charge" 200 "a200_GridFollowFaulted" 199 "a199_GridFollowAborted" 198 "a198_SW_SOC_Abrupt_Change" 197 "a197_SW_High_SOC_OV" 196 "a196_SW_PackVoltageUnderThreshold" 195 "a195_SW_DeltaTempOverThreshold" 194 "a194_PowershareLimitViolation" 193 "a193_PowershareMaxBrickVoltageViolation" 192 "a192_PowershareExternalChargeRegulation" 191 "a191_PowershareMinVoltageViolation" 190 "a190_PowershareMaxVoltageViolation" 189 "a189_PowershareDischargeCurrentViolation" 188 "a188_PowershareChargeCurrentViolation" 187 "a187_RippleHeatingEmergencyShutdown" 186 "a186_RippleHeatingChargeFault" 185 "a185_LifeModel_CyclingDcrGrowth_Change" 184 "a184_LifeModel_CyclingLoss_Change" 183 "a183_LifeModel_StoDcrGrowth_Change" 182 "a182_LifeModel_NoCurrentLoss_Change" 181 "a181_SW_Shunt_Over_Temperature" 180 "a180_SW_ECU_reset_blocked" 179 "a179_HvpGpoRequestActive" 178 "a178_SW_Uncontrolled_Regen_PwrB" 177 "a177_SW_Energy_Buffer_Size" 176 "a176_SW_GracefulPowerOff" 175 "a175_Charge_Failure_External" 174 "a174_SW_Charge_Failure" 173 "a173_FullPackEnergyDegraded" 172 "a172_SW_Isolation_Failure_In_Drive_Warning" 171 "a171_SW_Stack_Voltage_Sense" 170 "a170_SW_Limp_Mode" 169 "a169_SW_FC_Pack_Weld" 168 "a168_SW_FC_Full_Weld" 167 "a167_SW_FC_Partial_Weld" 166 "a166_SW_Pack_Full_Weld" 165 "a165_SW_Pack_Partial_Weld" 164 "a164_SW_Uncontrolled_Regen" 163 "a163_GridFormAborted" 162 "a162_SW_No_Power_For_Support" 161 "a161_SW_BMB_Vref_warning" 160 "a160_SW_FC_Ctr_Clean_Failed" 159 "a159_SW_HVP_ECU_Error" 158 "a158_SW_HVP_HVI_Comms" 157 "a157_SW_Hist_Update_Missed" 156 "a156_SW_BMB_Vref_bad" 155 "a155_SW_Weak_short_impedence" 154 "a154_SW_Brick_OV_Warning_Stop_Charge" 153 "a153_GridFormFaulted" 152 "a152_Isolation_In_Dc_Charge" 151 "a151_SW_external_isolation" 150 "a150_SW_Missing_Part_Number" 149 "a149_SW_Missing_Config_Block" 148 "a148_SW_Unsupported_BMB_ASIC_Type" 147 "a147_SW_SOC_High_Ah_Error" 146 "a146_SW_Brick_Overdischarged" 145 "a145_SW_SOC_Change" 144 "a144_Hvp_Config_Mismatch" 143 "a143_SW_CAC_Change" 142 "a142_SW_Isolation_Degradation" 141 "a141_SW_BMB_Status_Warning" 140 "a140_HW_BMB_Status_Fault" 139 "a139_SW_DC_Link_V_Irrational" 138 "a138_SW_Brick_OV_Warning" 137 "a137_SW_Brick_UV_Warning" 136 "a136_SW_Module_OT_Warning" 135 "a135_HW_BMB_Diagnostics_Failure" 134 "a134_SW_Delayed_Ctr_Off" 133 "a133_IO_CAN_Bus_Off" 132 "a132_HW_BMB_OTP_Uncorrctbl" 131 "a131_Bleed_FET_Failure" 130 "a130_IO_CAN_Error" 129 "a129_SW_VSH_Failure" 128 "a128_SW_shunt_MIA" 127 "a127_SW_shunt_SNA" 126 "a126_SW_Thermistor_Failure" 124 "a124_Battery_Coolant_Flood" 123 "a123_SW_Internal_Isolation" 122 "a122_SW_BMS_Therm_Irrational" 121 "a121_SW_NVRAM_Config_Error" 120 "a120_SW_Delta_SOC_User_Warning" 119 "a119_Fast_Open_Vsh_Detected" 118 "a118_SW_Delta_SOC_Weak_Short_Warning" 117 "a117_SW_Delta_SOC_Weak_Short" 115 "a115_Energy_Rubberbanding_Reset" 112 "a112_LifeModel_Discontinuity" 111 "a111_LifeModel_Spread_Change" 110 "a110_LifeModel_AvgOffset_Change" 109 "a109_HW_BMB_Mute_Status_Mismatch" 108 "a108_SW_BMB_Device_OT" 107 "a107_SW_Stack_Voltage_MIA" 106 "a106_SW_All_Module_Tsense" 105 "a105_SW_One_Module_Tsense" 100 "a100_ThermalEventSuspected" 99 "a099_SW_BMB_Communication" 98 "a098_SW_BMB_Data_Integrity_Loss" 97 "a097_SW_BMB_Over_CAN_Communication" 95 "a095_SW_UI_MIA" 94 "a094_SW_Drive_Inverter_MIA" 92 "a092_SW_ChargePort_Mia_On_Hvs" 91 "a091_SW_ChargePort_MIA" 90 "a090_SW_Gateway_MIA" 89 "a089_SW_VcFront_MIA" 88 "a088_SW_VcFront_MIA_InDrive" 87 "a087_SW_Feim_Test_Blocked" 86 "a086_SW_FC_Contactor_Mismatch" 85 "a085_SW_Pack_Contactor_Mismatch" 84 "a084_SW_Sleep_Wake_Aborted" 83 "a083_SW_Ctr_Close_Failure" 82 "a082_SW_Ctr_Force_Open" 81 "a081_SW_Ctr_Close_Blocked" 80 "a080_SW_Pack_Ctr_Impedance" 79 "a079_Max_Charge_Level_Exceeded" 78 "a078_Rapid_Dch_While_Charging" 77 "a077_SW_Charger_Regulation" 76 "a076_SW_Dch_While_Charging" 75 "a075_SW_Chg_Disable_Failure" 74 "a074_Max_Charge_Level_Reduced" 73 "a073_Unexpected_Loss_Of_Lv" 72 "a072_Module_Brick_Split" 71 "a071_SW_SM_TransCon_Not_Met" 70 "a070_BrickV_Imbalance_Limiting" 69 "a069_SW_Low_Power" 68 "a068_CAC_Imbalance_Limp" 67 "a067_CAC_Imbalance_Limiting" 66 "a066_SOC_Imbalance_Warning" 65 "a065_SW_CAC_Imbalance" 64 "a064_SW_SOC_Imbalance" 63 "a063_SW_ChargePort_Fault" 62 "a062_SW_BrickV_Imbalance" 61 "a061_SW_BrickV_Change" 60 "a060_SW_Leakage_Test_Failure" 59 "a059_SW_Pack_Voltage_Sensing" 58 "a058_SW_Bandolier_Model_Reset" 57 "a057_SW_Bandolier_Model_Warning" 56 "a056_SW_Standby_Supply_Fault" 55 "a055_SW_HvChain_Model_Fault" 54 "a054_SW_Ver_Supply_Fault" 52 "a052_SW_PCS_MIA" 51 "a051_SW_HVC_Vref_Bad" 50 "a050_SW_Brick_Voltage_MIA" 49 "a049_SW_Thermal_Event" 48 "a048_SW_Watch_Dog_Warning" 47 "a047_SW_Task_Stack_Overflow" 46 "a046_SW_Task_Stack_Usage" 45 "a045_SW_Exception" 44 "a044_SW_Assertion" 43 "a043_SW_Watch_Dog_Reset" 42 "a042_SW_MPU_Error" 41 "a041_SW_Destructive_Reset_Source" 40 "a040_SW_Watch_Dog_HW_Triggered" 39 "a039_SW_DC_Link_Over_Voltage" 37 "a037_SW_Flood_Port_Open" 36 "a036_SW_HvpHvilFault" 35 "a035_SW_Isolation" 34 "a034_SW_Passive_Isolation" 33 "a033_VoltageDeviation" 32 "a032_VoltageLoss" 31 "a031_AlertsSetDuringSleep" 30 "a030_Impedance_Deviation" 29 "a029_dSoc_Limiting" 28 "a028_ShuntAsicCurrentOffsetDeviation" 27 "a027_SW_Repeated_Isolation_Failure_In_Drive" 26 "a026_SW_HFCurrent_Anomaly" 25 "a025_SW_PwrBalance_Anomaly" 24 "a024_SW_Islanded_Brick" 23 "a023_SW_Stack_OV" 22 "a022_SW_Over_Current" 21 "a021_SW_Dr_Limits_Regulation" 20 "a020_SW_Brick_Instability" 19 "a019_SW_Module_OT" 18 "a018_SW_Brick_UV" 17 "a017_SW_Brick_OV" 16 "a016_Pack_Module_Id_Mismatch" 4 "a004_Cal_Vs_Serial_Birth_Date_Mismatch" 3 "a003_SW_Pack_Birth_Date_Missing" 2 "a002_Pack_Performance_Config_Mismatch" 1 "a001_Pack_Config_Mismatch" 0 "ALERT_DO_NOT_USE_ZERO" ;
VAL_ 1343 BMS_a081_fourthBlockingAlertId 299 "a299_PowershareFailure" 291 "a291_SOC_Imbalance_By_Delta_Voltage_Over_Delta_SOC" 290 "d290_batteryPackTempSensorACircuitFailure" 289 "d289_batteryPackAOverTemperature" 288 "d288_batteryPackCellVoltageLow" 287 "d287_systemIsolationWarning" 286 "d286_dcLinkVoltageHigh" 285 "d285_packVoltageSensorACircuitFailure" 284 "d284_fastChargeNegContactorAStuckOpen" 283 "d283_fastChargeNegContactorAStuckClosed" 282 "d282_fastChargeNegContactorACircuitFailure" 281 "d281_fastChargePosContactorAStuckOpen" 280 "d280_fastChargePosContactorAStuckClosed" 279 "d279_fastChargePosContactorACircuitFailure" 278 "d278_packNegContactorAStuckClosed" 277 "d277_packNegContactorACircuitFailure" 276 "d276_packPosContactorAStuckClosed" 275 "d275_packPosContactorACircuitFailure" 274 "d274_packCurrentSensorACircuitFailure" 273 "d273_vcFrontCommsLost" 272 "d272_batteryPackSensorCommsLost" 271 "d271_batteryPackSensorFailure" 270 "d270_hvpCommsLost" 269 "d269_highVoltageFuseABlown" 268 "d268_hvpInvalidFirmwareConfig" 267 "d267_batteryPackCellVoltageSenseHarnessFailure" 266 "d266_energyReserveVoltageLow" 265 "d265_replaceBatteryPack" 264 "d264_invalidFirmwareConfig" 263 "d263_batterySystemCurrentHigh" 262 "d262_batteryPackLowStateOfCharge" 261 "d261_batteryPackCellVoltageHigh" 260 "d260_chargePortInterlockFailure" 259 "d259_highVoltageInterlockFailure" 258 "d258_externalIsolationFault" 257 "d257_internalIsolationFault" 256 "a256_SW_Low_Power_Warning" 255 "a255_EstimatedRangeReduced" 254 "a254_LdcsCacImbalance" 227 "a227_ExcessChargeCurrentInCharge" 221 "a221_PcsEmergencyShutdownRequested" 214 "a214_AcChargeAborted" 204 "a204_AcCpEmergencyShutdownRequested" 202 "a202_AcChargeFaulted" 201 "a201_SW_Brick_OV_During_Charge" 200 "a200_GridFollowFaulted" 199 "a199_GridFollowAborted" 198 "a198_SW_SOC_Abrupt_Change" 197 "a197_SW_High_SOC_OV" 196 "a196_SW_PackVoltageUnderThreshold" 195 "a195_SW_DeltaTempOverThreshold" 194 "a194_PowershareLimitViolation" 193 "a193_PowershareMaxBrickVoltageViolation" 192 "a192_PowershareExternalChargeRegulation" 191 "a191_PowershareMinVoltageViolation" 190 "a190_PowershareMaxVoltageViolation" 189 "a189_PowershareDischargeCurrentViolation" 188 "a188_PowershareChargeCurrentViolation" 187 "a187_RippleHeatingEmergencyShutdown" 186 "a186_RippleHeatingChargeFault" 185 "a185_LifeModel_CyclingDcrGrowth_Change" 184 "a184_LifeModel_CyclingLoss_Change" 183 "a183_LifeModel_StoDcrGrowth_Change" 182 "a182_LifeModel_NoCurrentLoss_Change" 181 "a181_SW_Shunt_Over_Temperature" 180 "a180_SW_ECU_reset_blocked" 179 "a179_HvpGpoRequestActive" 178 "a178_SW_Uncontrolled_Regen_PwrB" 177 "a177_SW_Energy_Buffer_Size" 176 "a176_SW_GracefulPowerOff" 175 "a175_Charge_Failure_External" 174 "a174_SW_Charge_Failure" 173 "a173_FullPackEnergyDegraded" 172 "a172_SW_Isolation_Failure_In_Drive_Warning" 171 "a171_SW_Stack_Voltage_Sense" 170 "a170_SW_Limp_Mode" 169 "a169_SW_FC_Pack_Weld" 168 "a168_SW_FC_Full_Weld" 167 "a167_SW_FC_Partial_Weld" 166 "a166_SW_Pack_Full_Weld" 165 "a165_SW_Pack_Partial_Weld" 164 "a164_SW_Uncontrolled_Regen" 163 "a163_GridFormAborted" 162 "a162_SW_No_Power_For_Support" 161 "a161_SW_BMB_Vref_warning" 160 "a160_SW_FC_Ctr_Clean_Failed" 159 "a159_SW_HVP_ECU_Error" 158 "a158_SW_HVP_HVI_Comms" 157 "a157_SW_Hist_Update_Missed" 156 "a156_SW_BMB_Vref_bad" 155 "a155_SW_Weak_short_impedence" 154 "a154_SW_Brick_OV_Warning_Stop_Charge" 153 "a153_GridFormFaulted" 152 "a152_Isolation_In_Dc_Charge" 151 "a151_SW_external_isolation" 150 "a150_SW_Missing_Part_Number" 149 "a149_SW_Missing_Config_Block" 148 "a148_SW_Unsupported_BMB_ASIC_Type" 147 "a147_SW_SOC_High_Ah_Error" 146 "a146_SW_Brick_Overdischarged" 145 "a145_SW_SOC_Change" 144 "a144_Hvp_Config_Mismatch" 143 "a143_SW_CAC_Change" 142 "a142_SW_Isolation_Degradation" 141 "a141_SW_BMB_Status_Warning" 140 "a140_HW_BMB_Status_Fault" 139 "a139_SW_DC_Link_V_Irrational" 138 "a138_SW_Brick_OV_Warning" 137 "a137_SW_Brick_UV_Warning" 136 "a136_SW_Module_OT_Warning" 135 "a135_HW_BMB_Diagnostics_Failure" 134 "a134_SW_Delayed_Ctr_Off" 133 "a133_IO_CAN_Bus_Off" 132 "a132_HW_BMB_OTP_Uncorrctbl" 131 "a131_Bleed_FET_Failure" 130 "a130_IO_CAN_Error" 129 "a129_SW_VSH_Failure" 128 "a128_SW_shunt_MIA" 127 "a127_SW_shunt_SNA" 126 "a126_SW_Thermistor_Failure" 124 "a124_Battery_Coolant_Flood" 123 "a123_SW_Internal_Isolation" 122 "a122_SW_BMS_Therm_Irrational" 121 "a121_SW_NVRAM_Config_Error" 120 "a120_SW_Delta_SOC_User_Warning" 119 "a119_Fast_Open_Vsh_Detected" 118 "a118_SW_Delta_SOC_Weak_Short_Warning" 117 "a117_SW_Delta_SOC_Weak_Short" 115 "a115_Energy_Rubberbanding_Reset" 112 "a112_LifeModel_Discontinuity" 111 "a111_LifeModel_Spread_Change" 110 "a110_LifeModel_AvgOffset_Change" 109 "a109_HW_BMB_Mute_Status_Mismatch" 108 "a108_SW_BMB_Device_OT" 107 "a107_SW_Stack_Voltage_MIA" 106 "a106_SW_All_Module_Tsense" 105 "a105_SW_One_Module_Tsense" 100 "a100_ThermalEventSuspected" 99 "a099_SW_BMB_Communication" 98 "a098_SW_BMB_Data_Integrity_Loss" 97 "a097_SW_BMB_Over_CAN_Communication" 95 "a095_SW_UI_MIA" 94 "a094_SW_Drive_Inverter_MIA" 92 "a092_SW_ChargePort_Mia_On_Hvs" 91 "a091_SW_ChargePort_MIA" 90 "a090_SW_Gateway_MIA" 89 "a089_SW_VcFront_MIA" 88 "a088_SW_VcFront_MIA_InDrive" 87 "a087_SW_Feim_Test_Blocked" 86 "a086_SW_FC_Contactor_Mismatch" 85 "a085_SW_Pack_Contactor_Mismatch" 84 "a084_SW_Sleep_Wake_Aborted" 83 "a083_SW_Ctr_Close_Failure" 82 "a082_SW_Ctr_Force_Open" 81 "a081_SW_Ctr_Close_Blocked" 80 "a080_SW_Pack_Ctr_Impedance" 79 "a079_Max_Charge_Level_Exceeded" 78 "a078_Rapid_Dch_While_Charging" 77 "a077_SW_Charger_Regulation" 76 "a076_SW_Dch_While_Charging" 75 "a075_SW_Chg_Disable_Failure" 74 "a074_Max_Charge_Level_Reduced" 73 "a073_Unexpected_Loss_Of_Lv" 72 "a072_Module_Brick_Split" 71 "a071_SW_SM_TransCon_Not_Met" 70 "a070_BrickV_Imbalance_Limiting" 69 "a069_SW_Low_Power" 68 "a068_CAC_Imbalance_Limp" 67 "a067_CAC_Imbalance_Limiting" 66 "a066_SOC_Imbalance_Warning" 65 "a065_SW_CAC_Imbalance" 64 "a064_SW_SOC_Imbalance" 63 "a063_SW_ChargePort_Fault" 62 "a062_SW_BrickV_Imbalance" 61 "a061_SW_BrickV_Change" 60 "a060_SW_Leakage_Test_Failure" 59 "a059_SW_Pack_Voltage_Sensing" 58 "a058_SW_Bandolier_Model_Reset" 57 "a057_SW_Bandolier_Model_Warning" 56 "a056_SW_Standby_Supply_Fault" 55 "a055_SW_HvChain_Model_Fault" 54 "a054_SW_Ver_Supply_Fault" 52 "a052_SW_PCS_MIA" 51 "a051_SW_HVC_Vref_Bad" 50 "a050_SW_Brick_Voltage_MIA" 49 "a049_SW_Thermal_Event" 48 "a048_SW_Watch_Dog_Warning" 47 "a047_SW_Task_Stack_Overflow" 46 "a046_SW_Task_Stack_Usage" 45 "a045_SW_Exception" 44 "a044_SW_Assertion" 43 "a043_SW_Watch_Dog_Reset" 42 "a042_SW_MPU_Error" 41 "a041_SW_Destructive_Reset_Source" 40 "a040_SW_Watch_Dog_HW_Triggered" 39 "a039_SW_DC_Link_Over_Voltage" 37 "a037_SW_Flood_Port_Open" 36 "a036_SW_HvpHvilFault" 35 "a035_SW_Isolation" 34 "a034_SW_Passive_Isolation" 33 "a033_VoltageDeviation" 32 "a032_VoltageLoss" 31 "a031_AlertsSetDuringSleep" 30 "a030_Impedance_Deviation" 29 "a029_dSoc_Limiting" 28 "a028_ShuntAsicCurrentOffsetDeviation" 27 "a027_SW_Repeated_Isolation_Failure_In_Drive" 26 "a026_SW_HFCurrent_Anomaly" 25 "a025_SW_PwrBalance_Anomaly" 24 "a024_SW_Islanded_Brick" 23 "a023_SW_Stack_OV" 22 "a022_SW_Over_Current" 21 "a021_SW_Dr_Limits_Regulation" 20 "a020_SW_Brick_Instability" 19 "a019_SW_Module_OT" 18 "a018_SW_Brick_UV" 17 "a017_SW_Brick_OV" 16 "a016_Pack_Module_Id_Mismatch" 4 "a004_Cal_Vs_Serial_Birth_Date_Mismatch" 3 "a003_SW_Pack_Birth_Date_Missing" 2 "a002_Pack_Performance_Config_Mismatch" 1 "a001_Pack_Config_Mismatch" 0 "ALERT_DO_NOT_USE_ZERO" ;
VAL_ 1343 BMS_a082_stateRequest 10 "DIAG" 9 "SNA" 8 "TEST" 7 "WELD" 6 "FAULT" 5 "CLEAR_FAULT" 4 "FEIM" 3 "CHARGE" 2 "SUPPORT" 1 "DRIVE" 0 "STANDBY" ;
VAL_ 1343 BMS_a082_firstAlertId 299 "a299_PowershareFailure" 291 "a291_SOC_Imbalance_By_Delta_Voltage_Over_Delta_SOC" 290 "d290_batteryPackTempSensorACircuitFailure" 289 "d289_batteryPackAOverTemperature" 288 "d288_batteryPackCellVoltageLow" 287 "d287_systemIsolationWarning" 286 "d286_dcLinkVoltageHigh" 285 "d285_packVoltageSensorACircuitFailure" 284 "d284_fastChargeNegContactorAStuckOpen" 283 "d283_fastChargeNegContactorAStuckClosed" 282 "d282_fastChargeNegContactorACircuitFailure" 281 "d281_fastChargePosContactorAStuckOpen" 280 "d280_fastChargePosContactorAStuckClosed" 279 "d279_fastChargePosContactorACircuitFailure" 278 "d278_packNegContactorAStuckClosed" 277 "d277_packNegContactorACircuitFailure" 276 "d276_packPosContactorAStuckClosed" 275 "d275_packPosContactorACircuitFailure" 274 "d274_packCurrentSensorACircuitFailure" 273 "d273_vcFrontCommsLost" 272 "d272_batteryPackSensorCommsLost" 271 "d271_batteryPackSensorFailure" 270 "d270_hvpCommsLost" 269 "d269_highVoltageFuseABlown" 268 "d268_hvpInvalidFirmwareConfig" 267 "d267_batteryPackCellVoltageSenseHarnessFailure" 266 "d266_energyReserveVoltageLow" 265 "d265_replaceBatteryPack" 264 "d264_invalidFirmwareConfig" 263 "d263_batterySystemCurrentHigh" 262 "d262_batteryPackLowStateOfCharge" 261 "d261_batteryPackCellVoltageHigh" 260 "d260_chargePortInterlockFailure" 259 "d259_highVoltageInterlockFailure" 258 "d258_externalIsolationFault" 257 "d257_internalIsolationFault" 256 "a256_SW_Low_Power_Warning" 255 "a255_EstimatedRangeReduced" 254 "a254_LdcsCacImbalance" 227 "a227_ExcessChargeCurrentInCharge" 221 "a221_PcsEmergencyShutdownRequested" 214 "a214_AcChargeAborted" 204 "a204_AcCpEmergencyShutdownRequested" 202 "a202_AcChargeFaulted" 201 "a201_SW_Brick_OV_During_Charge" 200 "a200_GridFollowFaulted" 199 "a199_GridFollowAborted" 198 "a198_SW_SOC_Abrupt_Change" 197 "a197_SW_High_SOC_OV" 196 "a196_SW_PackVoltageUnderThreshold" 195 "a195_SW_DeltaTempOverThreshold" 194 "a194_PowershareLimitViolation" 193 "a193_PowershareMaxBrickVoltageViolation" 192 "a192_PowershareExternalChargeRegulation" 191 "a191_PowershareMinVoltageViolation" 190 "a190_PowershareMaxVoltageViolation" 189 "a189_PowershareDischargeCurrentViolation" 188 "a188_PowershareChargeCurrentViolation" 187 "a187_RippleHeatingEmergencyShutdown" 186 "a186_RippleHeatingChargeFault" 185 "a185_LifeModel_CyclingDcrGrowth_Change" 184 "a184_LifeModel_CyclingLoss_Change" 183 "a183_LifeModel_StoDcrGrowth_Change" 182 "a182_LifeModel_NoCurrentLoss_Change" 181 "a181_SW_Shunt_Over_Temperature" 180 "a180_SW_ECU_reset_blocked" 179 "a179_HvpGpoRequestActive" 178 "a178_SW_Uncontrolled_Regen_PwrB" 177 "a177_SW_Energy_Buffer_Size" 176 "a176_SW_GracefulPowerOff" 175 "a175_Charge_Failure_External" 174 "a174_SW_Charge_Failure" 173 "a173_FullPackEnergyDegraded" 172 "a172_SW_Isolation_Failure_In_Drive_Warning" 171 "a171_SW_Stack_Voltage_Sense" 170 "a170_SW_Limp_Mode" 169 "a169_SW_FC_Pack_Weld" 168 "a168_SW_FC_Full_Weld" 167 "a167_SW_FC_Partial_Weld" 166 "a166_SW_Pack_Full_Weld" 165 "a165_SW_Pack_Partial_Weld" 164 "a164_SW_Uncontrolled_Regen" 163 "a163_GridFormAborted" 162 "a162_SW_No_Power_For_Support" 161 "a161_SW_BMB_Vref_warning" 160 "a160_SW_FC_Ctr_Clean_Failed" 159 "a159_SW_HVP_ECU_Error" 158 "a158_SW_HVP_HVI_Comms" 157 "a157_SW_Hist_Update_Missed" 156 "a156_SW_BMB_Vref_bad" 155 "a155_SW_Weak_short_impedence" 154 "a154_SW_Brick_OV_Warning_Stop_Charge" 153 "a153_GridFormFaulted" 152 "a152_Isolation_In_Dc_Charge" 151 "a151_SW_external_isolation" 150 "a150_SW_Missing_Part_Number" 149 "a149_SW_Missing_Config_Block" 148 "a148_SW_Unsupported_BMB_ASIC_Type" 147 "a147_SW_SOC_High_Ah_Error" 146 "a146_SW_Brick_Overdischarged" 145 "a145_SW_SOC_Change" 144 "a144_Hvp_Config_Mismatch" 143 "a143_SW_CAC_Change" 142 "a142_SW_Isolation_Degradation" 141 "a141_SW_BMB_Status_Warning" 140 "a140_HW_BMB_Status_Fault" 139 "a139_SW_DC_Link_V_Irrational" 138 "a138_SW_Brick_OV_Warning" 137 "a137_SW_Brick_UV_Warning" 136 "a136_SW_Module_OT_Warning" 135 "a135_HW_BMB_Diagnostics_Failure" 134 "a134_SW_Delayed_Ctr_Off" 133 "a133_IO_CAN_Bus_Off" 132 "a132_HW_BMB_OTP_Uncorrctbl" 131 "a131_Bleed_FET_Failure" 130 "a130_IO_CAN_Error" 129 "a129_SW_VSH_Failure" 128 "a128_SW_shunt_MIA" 127 "a127_SW_shunt_SNA" 126 "a126_SW_Thermistor_Failure" 124 "a124_Battery_Coolant_Flood" 123 "a123_SW_Internal_Isolation" 122 "a122_SW_BMS_Therm_Irrational" 121 "a121_SW_NVRAM_Config_Error" 120 "a120_SW_Delta_SOC_User_Warning" 119 "a119_Fast_Open_Vsh_Detected" 118 "a118_SW_Delta_SOC_Weak_Short_Warning" 117 "a117_SW_Delta_SOC_Weak_Short" 115 "a115_Energy_Rubberbanding_Reset" 112 "a112_LifeModel_Discontinuity" 111 "a111_LifeModel_Spread_Change" 110 "a110_LifeModel_AvgOffset_Change" 109 "a109_HW_BMB_Mute_Status_Mismatch" 108 "a108_SW_BMB_Device_OT" 107 "a107_SW_Stack_Voltage_MIA" 106 "a106_SW_All_Module_Tsense" 105 "a105_SW_One_Module_Tsense" 100 "a100_ThermalEventSuspected" 99 "a099_SW_BMB_Communication" 98 "a098_SW_BMB_Data_Integrity_Loss" 97 "a097_SW_BMB_Over_CAN_Communication" 95 "a095_SW_UI_MIA" 94 "a094_SW_Drive_Inverter_MIA" 92 "a092_SW_ChargePort_Mia_On_Hvs" 91 "a091_SW_ChargePort_MIA" 90 "a090_SW_Gateway_MIA" 89 "a089_SW_VcFront_MIA" 88 "a088_SW_VcFront_MIA_InDrive" 87 "a087_SW_Feim_Test_Blocked" 86 "a086_SW_FC_Contactor_Mismatch" 85 "a085_SW_Pack_Contactor_Mismatch" 84 "a084_SW_Sleep_Wake_Aborted" 83 "a083_SW_Ctr_Close_Failure" 82 "a082_SW_Ctr_Force_Open" 81 "a081_SW_Ctr_Close_Blocked" 80 "a080_SW_Pack_Ctr_Impedance" 79 "a079_Max_Charge_Level_Exceeded" 78 "a078_Rapid_Dch_While_Charging" 77 "a077_SW_Charger_Regulation" 76 "a076_SW_Dch_While_Charging" 75 "a075_SW_Chg_Disable_Failure" 74 "a074_Max_Charge_Level_Reduced" 73 "a073_Unexpected_Loss_Of_Lv" 72 "a072_Module_Brick_Split" 71 "a071_SW_SM_TransCon_Not_Met" 70 "a070_BrickV_Imbalance_Limiting" 69 "a069_SW_Low_Power" 68 "a068_CAC_Imbalance_Limp" 67 "a067_CAC_Imbalance_Limiting" 66 "a066_SOC_Imbalance_Warning" 65 "a065_SW_CAC_Imbalance" 64 "a064_SW_SOC_Imbalance" 63 "a063_SW_ChargePort_Fault" 62 "a062_SW_BrickV_Imbalance" 61 "a061_SW_BrickV_Change" 60 "a060_SW_Leakage_Test_Failure" 59 "a059_SW_Pack_Voltage_Sensing" 58 "a058_SW_Bandolier_Model_Reset" 57 "a057_SW_Bandolier_Model_Warning" 56 "a056_SW_Standby_Supply_Fault" 55 "a055_SW_HvChain_Model_Fault" 54 "a054_SW_Ver_Supply_Fault" 52 "a052_SW_PCS_MIA" 51 "a051_SW_HVC_Vref_Bad" 50 "a050_SW_Brick_Voltage_MIA" 49 "a049_SW_Thermal_Event" 48 "a048_SW_Watch_Dog_Warning" 47 "a047_SW_Task_Stack_Overflow" 46 "a046_SW_Task_Stack_Usage" 45 "a045_SW_Exception" 44 "a044_SW_Assertion" 43 "a043_SW_Watch_Dog_Reset" 42 "a042_SW_MPU_Error" 41 "a041_SW_Destructive_Reset_Source" 40 "a040_SW_Watch_Dog_HW_Triggered" 39 "a039_SW_DC_Link_Over_Voltage" 37 "a037_SW_Flood_Port_Open" 36 "a036_SW_HvpHvilFault" 35 "a035_SW_Isolation" 34 "a034_SW_Passive_Isolation" 33 "a033_VoltageDeviation" 32 "a032_VoltageLoss" 31 "a031_AlertsSetDuringSleep" 30 "a030_Impedance_Deviation" 29 "a029_dSoc_Limiting" 28 "a028_ShuntAsicCurrentOffsetDeviation" 27 "a027_SW_Repeated_Isolation_Failure_In_Drive" 26 "a026_SW_HFCurrent_Anomaly" 25 "a025_SW_PwrBalance_Anomaly" 24 "a024_SW_Islanded_Brick" 23 "a023_SW_Stack_OV" 22 "a022_SW_Over_Current" 21 "a021_SW_Dr_Limits_Regulation" 20 "a020_SW_Brick_Instability" 19 "a019_SW_Module_OT" 18 "a018_SW_Brick_UV" 17 "a017_SW_Brick_OV" 16 "a016_Pack_Module_Id_Mismatch" 4 "a004_Cal_Vs_Serial_Birth_Date_Mismatch" 3 "a003_SW_Pack_Birth_Date_Missing" 2 "a002_Pack_Performance_Config_Mismatch" 1 "a001_Pack_Config_Mismatch" 0 "ALERT_DO_NOT_USE_ZERO" ;
VAL_ 1343 BMS_a082_secondAlertId 299 "a299_PowershareFailure" 291 "a291_SOC_Imbalance_By_Delta_Voltage_Over_Delta_SOC" 290 "d290_batteryPackTempSensorACircuitFailure" 289 "d289_batteryPackAOverTemperature" 288 "d288_batteryPackCellVoltageLow" 287 "d287_systemIsolationWarning" 286 "d286_dcLinkVoltageHigh" 285 "d285_packVoltageSensorACircuitFailure" 284 "d284_fastChargeNegContactorAStuckOpen" 283 "d283_fastChargeNegContactorAStuckClosed" 282 "d282_fastChargeNegContactorACircuitFailure" 281 "d281_fastChargePosContactorAStuckOpen" 280 "d280_fastChargePosContactorAStuckClosed" 279 "d279_fastChargePosContactorACircuitFailure" 278 "d278_packNegContactorAStuckClosed" 277 "d277_packNegContactorACircuitFailure" 276 "d276_packPosContactorAStuckClosed" 275 "d275_packPosContactorACircuitFailure" 274 "d274_packCurrentSensorACircuitFailure" 273 "d273_vcFrontCommsLost" 272 "d272_batteryPackSensorCommsLost" 271 "d271_batteryPackSensorFailure" 270 "d270_hvpCommsLost" 269 "d269_highVoltageFuseABlown" 268 "d268_hvpInvalidFirmwareConfig" 267 "d267_batteryPackCellVoltageSenseHarnessFailure" 266 "d266_energyReserveVoltageLow" 265 "d265_replaceBatteryPack" 264 "d264_invalidFirmwareConfig" 263 "d263_batterySystemCurrentHigh" 262 "d262_batteryPackLowStateOfCharge" 261 "d261_batteryPackCellVoltageHigh" 260 "d260_chargePortInterlockFailure" 259 "d259_highVoltageInterlockFailure" 258 "d258_externalIsolationFault" 257 "d257_internalIsolationFault" 256 "a256_SW_Low_Power_Warning" 255 "a255_EstimatedRangeReduced" 254 "a254_LdcsCacImbalance" 227 "a227_ExcessChargeCurrentInCharge" 221 "a221_PcsEmergencyShutdownRequested" 214 "a214_AcChargeAborted" 204 "a204_AcCpEmergencyShutdownRequested" 202 "a202_AcChargeFaulted" 201 "a201_SW_Brick_OV_During_Charge" 200 "a200_GridFollowFaulted" 199 "a199_GridFollowAborted" 198 "a198_SW_SOC_Abrupt_Change" 197 "a197_SW_High_SOC_OV" 196 "a196_SW_PackVoltageUnderThreshold" 195 "a195_SW_DeltaTempOverThreshold" 194 "a194_PowershareLimitViolation" 193 "a193_PowershareMaxBrickVoltageViolation" 192 "a192_PowershareExternalChargeRegulation" 191 "a191_PowershareMinVoltageViolation" 190 "a190_PowershareMaxVoltageViolation" 189 "a189_PowershareDischargeCurrentViolation" 188 "a188_PowershareChargeCurrentViolation" 187 "a187_RippleHeatingEmergencyShutdown" 186 "a186_RippleHeatingChargeFault" 185 "a185_LifeModel_CyclingDcrGrowth_Change" 184 "a184_LifeModel_CyclingLoss_Change" 183 "a183_LifeModel_StoDcrGrowth_Change" 182 "a182_LifeModel_NoCurrentLoss_Change" 181 "a181_SW_Shunt_Over_Temperature" 180 "a180_SW_ECU_reset_blocked" 179 "a179_HvpGpoRequestActive" 178 "a178_SW_Uncontrolled_Regen_PwrB" 177 "a177_SW_Energy_Buffer_Size" 176 "a176_SW_GracefulPowerOff" 175 "a175_Charge_Failure_External" 174 "a174_SW_Charge_Failure" 173 "a173_FullPackEnergyDegraded" 172 "a172_SW_Isolation_Failure_In_Drive_Warning" 171 "a171_SW_Stack_Voltage_Sense" 170 "a170_SW_Limp_Mode" 169 "a169_SW_FC_Pack_Weld" 168 "a168_SW_FC_Full_Weld" 167 "a167_SW_FC_Partial_Weld" 166 "a166_SW_Pack_Full_Weld" 165 "a165_SW_Pack_Partial_Weld" 164 "a164_SW_Uncontrolled_Regen" 163 "a163_GridFormAborted" 162 "a162_SW_No_Power_For_Support" 161 "a161_SW_BMB_Vref_warning" 160 "a160_SW_FC_Ctr_Clean_Failed" 159 "a159_SW_HVP_ECU_Error" 158 "a158_SW_HVP_HVI_Comms" 157 "a157_SW_Hist_Update_Missed" 156 "a156_SW_BMB_Vref_bad" 155 "a155_SW_Weak_short_impedence" 154 "a154_SW_Brick_OV_Warning_Stop_Charge" 153 "a153_GridFormFaulted" 152 "a152_Isolation_In_Dc_Charge" 151 "a151_SW_external_isolation" 150 "a150_SW_Missing_Part_Number" 149 "a149_SW_Missing_Config_Block" 148 "a148_SW_Unsupported_BMB_ASIC_Type" 147 "a147_SW_SOC_High_Ah_Error" 146 "a146_SW_Brick_Overdischarged" 145 "a145_SW_SOC_Change" 144 "a144_Hvp_Config_Mismatch" 143 "a143_SW_CAC_Change" 142 "a142_SW_Isolation_Degradation" 141 "a141_SW_BMB_Status_Warning" 140 "a140_HW_BMB_Status_Fault" 139 "a139_SW_DC_Link_V_Irrational" 138 "a138_SW_Brick_OV_Warning" 137 "a137_SW_Brick_UV_Warning" 136 "a136_SW_Module_OT_Warning" 135 "a135_HW_BMB_Diagnostics_Failure" 134 "a134_SW_Delayed_Ctr_Off" 133 "a133_IO_CAN_Bus_Off" 132 "a132_HW_BMB_OTP_Uncorrctbl" 131 "a131_Bleed_FET_Failure" 130 "a130_IO_CAN_Error" 129 "a129_SW_VSH_Failure" 128 "a128_SW_shunt_MIA" 127 "a127_SW_shunt_SNA" 126 "a126_SW_Thermistor_Failure" 124 "a124_Battery_Coolant_Flood" 123 "a123_SW_Internal_Isolation" 122 "a122_SW_BMS_Therm_Irrational" 121 "a121_SW_NVRAM_Config_Error" 120 "a120_SW_Delta_SOC_User_Warning" 119 "a119_Fast_Open_Vsh_Detected" 118 "a118_SW_Delta_SOC_Weak_Short_Warning" 117 "a117_SW_Delta_SOC_Weak_Short" 115 "a115_Energy_Rubberbanding_Reset" 112 "a112_LifeModel_Discontinuity" 111 "a111_LifeModel_Spread_Change" 110 "a110_LifeModel_AvgOffset_Change" 109 "a109_HW_BMB_Mute_Status_Mismatch" 108 "a108_SW_BMB_Device_OT" 107 "a107_SW_Stack_Voltage_MIA" 106 "a106_SW_All_Module_Tsense" 105 "a105_SW_One_Module_Tsense" 100 "a100_ThermalEventSuspected" 99 "a099_SW_BMB_Communication" 98 "a098_SW_BMB_Data_Integrity_Loss" 97 "a097_SW_BMB_Over_CAN_Communication" 95 "a095_SW_UI_MIA" 94 "a094_SW_Drive_Inverter_MIA" 92 "a092_SW_ChargePort_Mia_On_Hvs" 91 "a091_SW_ChargePort_MIA" 90 "a090_SW_Gateway_MIA" 89 "a089_SW_VcFront_MIA" 88 "a088_SW_VcFront_MIA_InDrive" 87 "a087_SW_Feim_Test_Blocked" 86 "a086_SW_FC_Contactor_Mismatch" 85 "a085_SW_Pack_Contactor_Mismatch" 84 "a084_SW_Sleep_Wake_Aborted" 83 "a083_SW_Ctr_Close_Failure" 82 "a082_SW_Ctr_Force_Open" 81 "a081_SW_Ctr_Close_Blocked" 80 "a080_SW_Pack_Ctr_Impedance" 79 "a079_Max_Charge_Level_Exceeded" 78 "a078_Rapid_Dch_While_Charging" 77 "a077_SW_Charger_Regulation" 76 "a076_SW_Dch_While_Charging" 75 "a075_SW_Chg_Disable_Failure" 74 "a074_Max_Charge_Level_Reduced" 73 "a073_Unexpected_Loss_Of_Lv" 72 "a072_Module_Brick_Split" 71 "a071_SW_SM_TransCon_Not_Met" 70 "a070_BrickV_Imbalance_Limiting" 69 "a069_SW_Low_Power" 68 "a068_CAC_Imbalance_Limp" 67 "a067_CAC_Imbalance_Limiting" 66 "a066_SOC_Imbalance_Warning" 65 "a065_SW_CAC_Imbalance" 64 "a064_SW_SOC_Imbalance" 63 "a063_SW_ChargePort_Fault" 62 "a062_SW_BrickV_Imbalance" 61 "a061_SW_BrickV_Change" 60 "a060_SW_Leakage_Test_Failure" 59 "a059_SW_Pack_Voltage_Sensing" 58 "a058_SW_Bandolier_Model_Reset" 57 "a057_SW_Bandolier_Model_Warning" 56 "a056_SW_Standby_Supply_Fault" 55 "a055_SW_HvChain_Model_Fault" 54 "a054_SW_Ver_Supply_Fault" 52 "a052_SW_PCS_MIA" 51 "a051_SW_HVC_Vref_Bad" 50 "a050_SW_Brick_Voltage_MIA" 49 "a049_SW_Thermal_Event" 48 "a048_SW_Watch_Dog_Warning" 47 "a047_SW_Task_Stack_Overflow" 46 "a046_SW_Task_Stack_Usage" 45 "a045_SW_Exception" 44 "a044_SW_Assertion" 43 "a043_SW_Watch_Dog_Reset" 42 "a042_SW_MPU_Error" 41 "a041_SW_Destructive_Reset_Source" 40 "a040_SW_Watch_Dog_HW_Triggered" 39 "a039_SW_DC_Link_Over_Voltage" 37 "a037_SW_Flood_Port_Open" 36 "a036_SW_HvpHvilFault" 35 "a035_SW_Isolation" 34 "a034_SW_Passive_Isolation" 33 "a033_VoltageDeviation" 32 "a032_VoltageLoss" 31 "a031_AlertsSetDuringSleep" 30 "a030_Impedance_Deviation" 29 "a029_dSoc_Limiting" 28 "a028_ShuntAsicCurrentOffsetDeviation" 27 "a027_SW_Repeated_Isolation_Failure_In_Drive" 26 "a026_SW_HFCurrent_Anomaly" 25 "a025_SW_PwrBalance_Anomaly" 24 "a024_SW_Islanded_Brick" 23 "a023_SW_Stack_OV" 22 "a022_SW_Over_Current" 21 "a021_SW_Dr_Limits_Regulation" 20 "a020_SW_Brick_Instability" 19 "a019_SW_Module_OT" 18 "a018_SW_Brick_UV" 17 "a017_SW_Brick_OV" 16 "a016_Pack_Module_Id_Mismatch" 4 "a004_Cal_Vs_Serial_Birth_Date_Mismatch" 3 "a003_SW_Pack_Birth_Date_Missing" 2 "a002_Pack_Performance_Config_Mismatch" 1 "a001_Pack_Config_Mismatch" 0 "ALERT_DO_NOT_USE_ZERO" ;
VAL_ 1343 BMS_a082_thirdAlertId 299 "a299_PowershareFailure" 291 "a291_SOC_Imbalance_By_Delta_Voltage_Over_Delta_SOC" 290 "d290_batteryPackTempSensorACircuitFailure" 289 "d289_batteryPackAOverTemperature" 288 "d288_batteryPackCellVoltageLow" 287 "d287_systemIsolationWarning" 286 "d286_dcLinkVoltageHigh" 285 "d285_packVoltageSensorACircuitFailure" 284 "d284_fastChargeNegContactorAStuckOpen" 283 "d283_fastChargeNegContactorAStuckClosed" 282 "d282_fastChargeNegContactorACircuitFailure" 281 "d281_fastChargePosContactorAStuckOpen" 280 "d280_fastChargePosContactorAStuckClosed" 279 "d279_fastChargePosContactorACircuitFailure" 278 "d278_packNegContactorAStuckClosed" 277 "d277_packNegContactorACircuitFailure" 276 "d276_packPosContactorAStuckClosed" 275 "d275_packPosContactorACircuitFailure" 274 "d274_packCurrentSensorACircuitFailure" 273 "d273_vcFrontCommsLost" 272 "d272_batteryPackSensorCommsLost" 271 "d271_batteryPackSensorFailure" 270 "d270_hvpCommsLost" 269 "d269_highVoltageFuseABlown" 268 "d268_hvpInvalidFirmwareConfig" 267 "d267_batteryPackCellVoltageSenseHarnessFailure" 266 "d266_energyReserveVoltageLow" 265 "d265_replaceBatteryPack" 264 "d264_invalidFirmwareConfig" 263 "d263_batterySystemCurrentHigh" 262 "d262_batteryPackLowStateOfCharge" 261 "d261_batteryPackCellVoltageHigh" 260 "d260_chargePortInterlockFailure" 259 "d259_highVoltageInterlockFailure" 258 "d258_externalIsolationFault" 257 "d257_internalIsolationFault" 256 "a256_SW_Low_Power_Warning" 255 "a255_EstimatedRangeReduced" 254 "a254_LdcsCacImbalance" 227 "a227_ExcessChargeCurrentInCharge" 221 "a221_PcsEmergencyShutdownRequested" 214 "a214_AcChargeAborted" 204 "a204_AcCpEmergencyShutdownRequested" 202 "a202_AcChargeFaulted" 201 "a201_SW_Brick_OV_During_Charge" 200 "a200_GridFollowFaulted" 199 "a199_GridFollowAborted" 198 "a198_SW_SOC_Abrupt_Change" 197 "a197_SW_High_SOC_OV" 196 "a196_SW_PackVoltageUnderThreshold" 195 "a195_SW_DeltaTempOverThreshold" 194 "a194_PowershareLimitViolation" 193 "a193_PowershareMaxBrickVoltageViolation" 192 "a192_PowershareExternalChargeRegulation" 191 "a191_PowershareMinVoltageViolation" 190 "a190_PowershareMaxVoltageViolation" 189 "a189_PowershareDischargeCurrentViolation" 188 "a188_PowershareChargeCurrentViolation" 187 "a187_RippleHeatingEmergencyShutdown" 186 "a186_RippleHeatingChargeFault" 185 "a185_LifeModel_CyclingDcrGrowth_Change" 184 "a184_LifeModel_CyclingLoss_Change" 183 "a183_LifeModel_StoDcrGrowth_Change" 182 "a182_LifeModel_NoCurrentLoss_Change" 181 "a181_SW_Shunt_Over_Temperature" 180 "a180_SW_ECU_reset_blocked" 179 "a179_HvpGpoRequestActive" 178 "a178_SW_Uncontrolled_Regen_PwrB" 177 "a177_SW_Energy_Buffer_Size" 176 "a176_SW_GracefulPowerOff" 175 "a175_Charge_Failure_External" 174 "a174_SW_Charge_Failure" 173 "a173_FullPackEnergyDegraded" 172 "a172_SW_Isolation_Failure_In_Drive_Warning" 171 "a171_SW_Stack_Voltage_Sense" 170 "a170_SW_Limp_Mode" 169 "a169_SW_FC_Pack_Weld" 168 "a168_SW_FC_Full_Weld" 167 "a167_SW_FC_Partial_Weld" 166 "a166_SW_Pack_Full_Weld" 165 "a165_SW_Pack_Partial_Weld" 164 "a164_SW_Uncontrolled_Regen" 163 "a163_GridFormAborted" 162 "a162_SW_No_Power_For_Support" 161 "a161_SW_BMB_Vref_warning" 160 "a160_SW_FC_Ctr_Clean_Failed" 159 "a159_SW_HVP_ECU_Error" 158 "a158_SW_HVP_HVI_Comms" 157 "a157_SW_Hist_Update_Missed" 156 "a156_SW_BMB_Vref_bad" 155 "a155_SW_Weak_short_impedence" 154 "a154_SW_Brick_OV_Warning_Stop_Charge" 153 "a153_GridFormFaulted" 152 "a152_Isolation_In_Dc_Charge" 151 "a151_SW_external_isolation" 150 "a150_SW_Missing_Part_Number" 149 "a149_SW_Missing_Config_Block" 148 "a148_SW_Unsupported_BMB_ASIC_Type" 147 "a147_SW_SOC_High_Ah_Error" 146 "a146_SW_Brick_Overdischarged" 145 "a145_SW_SOC_Change" 144 "a144_Hvp_Config_Mismatch" 143 "a143_SW_CAC_Change" 142 "a142_SW_Isolation_Degradation" 141 "a141_SW_BMB_Status_Warning" 140 "a140_HW_BMB_Status_Fault" 139 "a139_SW_DC_Link_V_Irrational" 138 "a138_SW_Brick_OV_Warning" 137 "a137_SW_Brick_UV_Warning" 136 "a136_SW_Module_OT_Warning" 135 "a135_HW_BMB_Diagnostics_Failure" 134 "a134_SW_Delayed_Ctr_Off" 133 "a133_IO_CAN_Bus_Off" 132 "a132_HW_BMB_OTP_Uncorrctbl" 131 "a131_Bleed_FET_Failure" 130 "a130_IO_CAN_Error" 129 "a129_SW_VSH_Failure" 128 "a128_SW_shunt_MIA" 127 "a127_SW_shunt_SNA" 126 "a126_SW_Thermistor_Failure" 124 "a124_Battery_Coolant_Flood" 123 "a123_SW_Internal_Isolation" 122 "a122_SW_BMS_Therm_Irrational" 121 "a121_SW_NVRAM_Config_Error" 120 "a120_SW_Delta_SOC_User_Warning" 119 "a119_Fast_Open_Vsh_Detected" 118 "a118_SW_Delta_SOC_Weak_Short_Warning" 117 "a117_SW_Delta_SOC_Weak_Short" 115 "a115_Energy_Rubberbanding_Reset" 112 "a112_LifeModel_Discontinuity" 111 "a111_LifeModel_Spread_Change" 110 "a110_LifeModel_AvgOffset_Change" 109 "a109_HW_BMB_Mute_Status_Mismatch" 108 "a108_SW_BMB_Device_OT" 107 "a107_SW_Stack_Voltage_MIA" 106 "a106_SW_All_Module_Tsense" 105 "a105_SW_One_Module_Tsense" 100 "a100_ThermalEventSuspected" 99 "a099_SW_BMB_Communication" 98 "a098_SW_BMB_Data_Integrity_Loss" 97 "a097_SW_BMB_Over_CAN_Communication" 95 "a095_SW_UI_MIA" 94 "a094_SW_Drive_Inverter_MIA" 92 "a092_SW_ChargePort_Mia_On_Hvs" 91 "a091_SW_ChargePort_MIA" 90 "a090_SW_Gateway_MIA" 89 "a089_SW_VcFront_MIA" 88 "a088_SW_VcFront_MIA_InDrive" 87 "a087_SW_Feim_Test_Blocked" 86 "a086_SW_FC_Contactor_Mismatch" 85 "a085_SW_Pack_Contactor_Mismatch" 84 "a084_SW_Sleep_Wake_Aborted" 83 "a083_SW_Ctr_Close_Failure" 82 "a082_SW_Ctr_Force_Open" 81 "a081_SW_Ctr_Close_Blocked" 80 "a080_SW_Pack_Ctr_Impedance" 79 "a079_Max_Charge_Level_Exceeded" 78 "a078_Rapid_Dch_While_Charging" 77 "a077_SW_Charger_Regulation" 76 "a076_SW_Dch_While_Charging" 75 "a075_SW_Chg_Disable_Failure" 74 "a074_Max_Charge_Level_Reduced" 73 "a073_Unexpected_Loss_Of_Lv" 72 "a072_Module_Brick_Split" 71 "a071_SW_SM_TransCon_Not_Met" 70 "a070_BrickV_Imbalance_Limiting" 69 "a069_SW_Low_Power" 68 "a068_CAC_Imbalance_Limp" 67 "a067_CAC_Imbalance_Limiting" 66 "a066_SOC_Imbalance_Warning" 65 "a065_SW_CAC_Imbalance" 64 "a064_SW_SOC_Imbalance" 63 "a063_SW_ChargePort_Fault" 62 "a062_SW_BrickV_Imbalance" 61 "a061_SW_BrickV_Change" 60 "a060_SW_Leakage_Test_Failure" 59 "a059_SW_Pack_Voltage_Sensing" 58 "a058_SW_Bandolier_Model_Reset" 57 "a057_SW_Bandolier_Model_Warning" 56 "a056_SW_Standby_Supply_Fault" 55 "a055_SW_HvChain_Model_Fault" 54 "a054_SW_Ver_Supply_Fault" 52 "a052_SW_PCS_MIA" 51 "a051_SW_HVC_Vref_Bad" 50 "a050_SW_Brick_Voltage_MIA" 49 "a049_SW_Thermal_Event" 48 "a048_SW_Watch_Dog_Warning" 47 "a047_SW_Task_Stack_Overflow" 46 "a046_SW_Task_Stack_Usage" 45 "a045_SW_Exception" 44 "a044_SW_Assertion" 43 "a043_SW_Watch_Dog_Reset" 42 "a042_SW_MPU_Error" 41 "a041_SW_Destructive_Reset_Source" 40 "a040_SW_Watch_Dog_HW_Triggered" 39 "a039_SW_DC_Link_Over_Voltage" 37 "a037_SW_Flood_Port_Open" 36 "a036_SW_HvpHvilFault" 35 "a035_SW_Isolation" 34 "a034_SW_Passive_Isolation" 33 "a033_VoltageDeviation" 32 "a032_VoltageLoss" 31 "a031_AlertsSetDuringSleep" 30 "a030_Impedance_Deviation" 29 "a029_dSoc_Limiting" 28 "a028_ShuntAsicCurrentOffsetDeviation" 27 "a027_SW_Repeated_Isolation_Failure_In_Drive" 26 "a026_SW_HFCurrent_Anomaly" 25 "a025_SW_PwrBalance_Anomaly" 24 "a024_SW_Islanded_Brick" 23 "a023_SW_Stack_OV" 22 "a022_SW_Over_Current" 21 "a021_SW_Dr_Limits_Regulation" 20 "a020_SW_Brick_Instability" 19 "a019_SW_Module_OT" 18 "a018_SW_Brick_UV" 17 "a017_SW_Brick_OV" 16 "a016_Pack_Module_Id_Mismatch" 4 "a004_Cal_Vs_Serial_Birth_Date_Mismatch" 3 "a003_SW_Pack_Birth_Date_Missing" 2 "a002_Pack_Performance_Config_Mismatch" 1 "a001_Pack_Config_Mismatch" 0 "ALERT_DO_NOT_USE_ZERO" ;
VAL_ 1343 BMS_a082_fourthAlertId 299 "a299_PowershareFailure" 291 "a291_SOC_Imbalance_By_Delta_Voltage_Over_Delta_SOC" 290 "d290_batteryPackTempSensorACircuitFailure" 289 "d289_batteryPackAOverTemperature" 288 "d288_batteryPackCellVoltageLow" 287 "d287_systemIsolationWarning" 286 "d286_dcLinkVoltageHigh" 285 "d285_packVoltageSensorACircuitFailure" 284 "d284_fastChargeNegContactorAStuckOpen" 283 "d283_fastChargeNegContactorAStuckClosed" 282 "d282_fastChargeNegContactorACircuitFailure" 281 "d281_fastChargePosContactorAStuckOpen" 280 "d280_fastChargePosContactorAStuckClosed" 279 "d279_fastChargePosContactorACircuitFailure" 278 "d278_packNegContactorAStuckClosed" 277 "d277_packNegContactorACircuitFailure" 276 "d276_packPosContactorAStuckClosed" 275 "d275_packPosContactorACircuitFailure" 274 "d274_packCurrentSensorACircuitFailure" 273 "d273_vcFrontCommsLost" 272 "d272_batteryPackSensorCommsLost" 271 "d271_batteryPackSensorFailure" 270 "d270_hvpCommsLost" 269 "d269_highVoltageFuseABlown" 268 "d268_hvpInvalidFirmwareConfig" 267 "d267_batteryPackCellVoltageSenseHarnessFailure" 266 "d266_energyReserveVoltageLow" 265 "d265_replaceBatteryPack" 264 "d264_invalidFirmwareConfig" 263 "d263_batterySystemCurrentHigh" 262 "d262_batteryPackLowStateOfCharge" 261 "d261_batteryPackCellVoltageHigh" 260 "d260_chargePortInterlockFailure" 259 "d259_highVoltageInterlockFailure" 258 "d258_externalIsolationFault" 257 "d257_internalIsolationFault" 256 "a256_SW_Low_Power_Warning" 255 "a255_EstimatedRangeReduced" 254 "a254_LdcsCacImbalance" 227 "a227_ExcessChargeCurrentInCharge" 221 "a221_PcsEmergencyShutdownRequested" 214 "a214_AcChargeAborted" 204 "a204_AcCpEmergencyShutdownRequested" 202 "a202_AcChargeFaulted" 201 "a201_SW_Brick_OV_During_Charge" 200 "a200_GridFollowFaulted" 199 "a199_GridFollowAborted" 198 "a198_SW_SOC_Abrupt_Change" 197 "a197_SW_High_SOC_OV" 196 "a196_SW_PackVoltageUnderThreshold" 195 "a195_SW_DeltaTempOverThreshold" 194 "a194_PowershareLimitViolation" 193 "a193_PowershareMaxBrickVoltageViolation" 192 "a192_PowershareExternalChargeRegulation" 191 "a191_PowershareMinVoltageViolation" 190 "a190_PowershareMaxVoltageViolation" 189 "a189_PowershareDischargeCurrentViolation" 188 "a188_PowershareChargeCurrentViolation" 187 "a187_RippleHeatingEmergencyShutdown" 186 "a186_RippleHeatingChargeFault" 185 "a185_LifeModel_CyclingDcrGrowth_Change" 184 "a184_LifeModel_CyclingLoss_Change" 183 "a183_LifeModel_StoDcrGrowth_Change" 182 "a182_LifeModel_NoCurrentLoss_Change" 181 "a181_SW_Shunt_Over_Temperature" 180 "a180_SW_ECU_reset_blocked" 179 "a179_HvpGpoRequestActive" 178 "a178_SW_Uncontrolled_Regen_PwrB" 177 "a177_SW_Energy_Buffer_Size" 176 "a176_SW_GracefulPowerOff" 175 "a175_Charge_Failure_External" 174 "a174_SW_Charge_Failure" 173 "a173_FullPackEnergyDegraded" 172 "a172_SW_Isolation_Failure_In_Drive_Warning" 171 "a171_SW_Stack_Voltage_Sense" 170 "a170_SW_Limp_Mode" 169 "a169_SW_FC_Pack_Weld" 168 "a168_SW_FC_Full_Weld" 167 "a167_SW_FC_Partial_Weld" 166 "a166_SW_Pack_Full_Weld" 165 "a165_SW_Pack_Partial_Weld" 164 "a164_SW_Uncontrolled_Regen" 163 "a163_GridFormAborted" 162 "a162_SW_No_Power_For_Support" 161 "a161_SW_BMB_Vref_warning" 160 "a160_SW_FC_Ctr_Clean_Failed" 159 "a159_SW_HVP_ECU_Error" 158 "a158_SW_HVP_HVI_Comms" 157 "a157_SW_Hist_Update_Missed" 156 "a156_SW_BMB_Vref_bad" 155 "a155_SW_Weak_short_impedence" 154 "a154_SW_Brick_OV_Warning_Stop_Charge" 153 "a153_GridFormFaulted" 152 "a152_Isolation_In_Dc_Charge" 151 "a151_SW_external_isolation" 150 "a150_SW_Missing_Part_Number" 149 "a149_SW_Missing_Config_Block" 148 "a148_SW_Unsupported_BMB_ASIC_Type" 147 "a147_SW_SOC_High_Ah_Error" 146 "a146_SW_Brick_Overdischarged" 145 "a145_SW_SOC_Change" 144 "a144_Hvp_Config_Mismatch" 143 "a143_SW_CAC_Change" 142 "a142_SW_Isolation_Degradation" 141 "a141_SW_BMB_Status_Warning" 140 "a140_HW_BMB_Status_Fault" 139 "a139_SW_DC_Link_V_Irrational" 138 "a138_SW_Brick_OV_Warning" 137 "a137_SW_Brick_UV_Warning" 136 "a136_SW_Module_OT_Warning" 135 "a135_HW_BMB_Diagnostics_Failure" 134 "a134_SW_Delayed_Ctr_Off" 133 "a133_IO_CAN_Bus_Off" 132 "a132_HW_BMB_OTP_Uncorrctbl" 131 "a131_Bleed_FET_Failure" 130 "a130_IO_CAN_Error" 129 "a129_SW_VSH_Failure" 128 "a128_SW_shunt_MIA" 127 "a127_SW_shunt_SNA" 126 "a126_SW_Thermistor_Failure" 124 "a124_Battery_Coolant_Flood" 123 "a123_SW_Internal_Isolation" 122 "a122_SW_BMS_Therm_Irrational" 121 "a121_SW_NVRAM_Config_Error" 120 "a120_SW_Delta_SOC_User_Warning" 119 "a119_Fast_Open_Vsh_Detected" 118 "a118_SW_Delta_SOC_Weak_Short_Warning" 117 "a117_SW_Delta_SOC_Weak_Short" 115 "a115_Energy_Rubberbanding_Reset" 112 "a112_LifeModel_Discontinuity" 111 "a111_LifeModel_Spread_Change" 110 "a110_LifeModel_AvgOffset_Change" 109 "a109_HW_BMB_Mute_Status_Mismatch" 108 "a108_SW_BMB_Device_OT" 107 "a107_SW_Stack_Voltage_MIA" 106 "a106_SW_All_Module_Tsense" 105 "a105_SW_One_Module_Tsense" 100 "a100_ThermalEventSuspected" 99 "a099_SW_BMB_Communication" 98 "a098_SW_BMB_Data_Integrity_Loss" 97 "a097_SW_BMB_Over_CAN_Communication" 95 "a095_SW_UI_MIA" 94 "a094_SW_Drive_Inverter_MIA" 92 "a092_SW_ChargePort_Mia_On_Hvs" 91 "a091_SW_ChargePort_MIA" 90 "a090_SW_Gateway_MIA" 89 "a089_SW_VcFront_MIA" 88 "a088_SW_VcFront_MIA_InDrive" 87 "a087_SW_Feim_Test_Blocked" 86 "a086_SW_FC_Contactor_Mismatch" 85 "a085_SW_Pack_Contactor_Mismatch" 84 "a084_SW_Sleep_Wake_Aborted" 83 "a083_SW_Ctr_Close_Failure" 82 "a082_SW_Ctr_Force_Open" 81 "a081_SW_Ctr_Close_Blocked" 80 "a080_SW_Pack_Ctr_Impedance" 79 "a079_Max_Charge_Level_Exceeded" 78 "a078_Rapid_Dch_While_Charging" 77 "a077_SW_Charger_Regulation" 76 "a076_SW_Dch_While_Charging" 75 "a075_SW_Chg_Disable_Failure" 74 "a074_Max_Charge_Level_Reduced" 73 "a073_Unexpected_Loss_Of_Lv" 72 "a072_Module_Brick_Split" 71 "a071_SW_SM_TransCon_Not_Met" 70 "a070_BrickV_Imbalance_Limiting" 69 "a069_SW_Low_Power" 68 "a068_CAC_Imbalance_Limp" 67 "a067_CAC_Imbalance_Limiting" 66 "a066_SOC_Imbalance_Warning" 65 "a065_SW_CAC_Imbalance" 64 "a064_SW_SOC_Imbalance" 63 "a063_SW_ChargePort_Fault" 62 "a062_SW_BrickV_Imbalance" 61 "a061_SW_BrickV_Change" 60 "a060_SW_Leakage_Test_Failure" 59 "a059_SW_Pack_Voltage_Sensing" 58 "a058_SW_Bandolier_Model_Reset" 57 "a057_SW_Bandolier_Model_Warning" 56 "a056_SW_Standby_Supply_Fault" 55 "a055_SW_HvChain_Model_Fault" 54 "a054_SW_Ver_Supply_Fault" 52 "a052_SW_PCS_MIA" 51 "a051_SW_HVC_Vref_Bad" 50 "a050_SW_Brick_Voltage_MIA" 49 "a049_SW_Thermal_Event" 48 "a048_SW_Watch_Dog_Warning" 47 "a047_SW_Task_Stack_Overflow" 46 "a046_SW_Task_Stack_Usage" 45 "a045_SW_Exception" 44 "a044_SW_Assertion" 43 "a043_SW_Watch_Dog_Reset" 42 "a042_SW_MPU_Error" 41 "a041_SW_Destructive_Reset_Source" 40 "a040_SW_Watch_Dog_HW_Triggered" 39 "a039_SW_DC_Link_Over_Voltage" 37 "a037_SW_Flood_Port_Open" 36 "a036_SW_HvpHvilFault" 35 "a035_SW_Isolation" 34 "a034_SW_Passive_Isolation" 33 "a033_VoltageDeviation" 32 "a032_VoltageLoss" 31 "a031_AlertsSetDuringSleep" 30 "a030_Impedance_Deviation" 29 "a029_dSoc_Limiting" 28 "a028_ShuntAsicCurrentOffsetDeviation" 27 "a027_SW_Repeated_Isolation_Failure_In_Drive" 26 "a026_SW_HFCurrent_Anomaly" 25 "a025_SW_PwrBalance_Anomaly" 24 "a024_SW_Islanded_Brick" 23 "a023_SW_Stack_OV" 22 "a022_SW_Over_Current" 21 "a021_SW_Dr_Limits_Regulation" 20 "a020_SW_Brick_Instability" 19 "a019_SW_Module_OT" 18 "a018_SW_Brick_UV" 17 "a017_SW_Brick_OV" 16 "a016_Pack_Module_Id_Mismatch" 4 "a004_Cal_Vs_Serial_Birth_Date_Mismatch" 3 "a003_SW_Pack_Birth_Date_Missing" 2 "a002_Pack_Performance_Config_Mismatch" 1 "a001_Pack_Config_Mismatch" 0 "ALERT_DO_NOT_USE_ZERO" ;
VAL_ 1343 BMS_a083_packContactorRequest 5 "FAULT_OPEN" 4 "OPEN" 3 "CLOSED" 2 "POS_CLOSED_NEG_OPEN" 1 "NEG_CLOSED_POS_OPEN" 0 "SNA" ;
VAL_ 1343 BMS_a085_packContactorSetStatePr 9 "NEGATIVE_CLOSED" 8 "POSITIVE_CLOSED" 7 "WELDED" 6 "PARTIAL_WELD" 5 "CLOSED" 4 "OPENING" 3 "BLOCKED" 2 "CLOSING" 1 "OPEN" 0 "SNA" ;
VAL_ 1343 BMS_a085_packContactorSetState 9 "NEGATIVE_CLOSED" 8 "POSITIVE_CLOSED" 7 "WELDED" 6 "PARTIAL_WELD" 5 "CLOSED" 4 "OPENING" 3 "BLOCKED" 2 "CLOSING" 1 "OPEN" 0 "SNA" ;
VAL_ 1343 BMS_a085_packContactorSetRe_0001 5 "CLOSE_POSITIVE_ONLY" 4 "CLOSE_NEGATIVE_ONLY" 3 "OPEN_IMMEDIATELY" 2 "OPEN" 1 "CLOSE" 0 "SNA" ;
VAL_ 1343 BMS_a085_packContactorSetRequest 5 "CLOSE_POSITIVE_ONLY" 4 "CLOSE_NEGATIVE_ONLY" 3 "OPEN_IMMEDIATELY" 2 "OPEN" 1 "CLOSE" 0 "SNA" ;
VAL_ 1343 BMS_a086_fcContactorSetStatePrev 9 "NEGATIVE_CLOSED" 8 "POSITIVE_CLOSED" 7 "WELDED" 6 "PARTIAL_WELD" 5 "CLOSED" 4 "OPENING" 3 "BLOCKED" 2 "CLOSING" 1 "OPEN" 0 "SNA" ;
VAL_ 1343 BMS_a086_fcContactorSetState 9 "NEGATIVE_CLOSED" 8 "POSITIVE_CLOSED" 7 "WELDED" 6 "PARTIAL_WELD" 5 "CLOSED" 4 "OPENING" 3 "BLOCKED" 2 "CLOSING" 1 "OPEN" 0 "SNA" ;
VAL_ 1343 BMS_a086_fcContactorSetRequestPr 5 "CLOSE_POSITIVE_ONLY" 4 "CLOSE_NEGATIVE_ONLY" 3 "OPEN_IMMEDIATELY" 2 "OPEN" 1 "CLOSE" 0 "SNA" ;
VAL_ 1343 BMS_a086_fcContactorSetRequest 5 "CLOSE_POSITIVE_ONLY" 4 "CLOSE_NEGATIVE_ONLY" 3 "OPEN_IMMEDIATELY" 2 "OPEN" 1 "CLOSE" 0 "SNA" ;
VAL_ 1343 BMS_a087_blockingAlert 299 "a299_PowershareFailure" 291 "a291_SOC_Imbalance_By_Delta_Voltage_Over_Delta_SOC" 290 "d290_batteryPackTempSensorACircuitFailure" 289 "d289_batteryPackAOverTemperature" 288 "d288_batteryPackCellVoltageLow" 287 "d287_systemIsolationWarning" 286 "d286_dcLinkVoltageHigh" 285 "d285_packVoltageSensorACircuitFailure" 284 "d284_fastChargeNegContactorAStuckOpen" 283 "d283_fastChargeNegContactorAStuckClosed" 282 "d282_fastChargeNegContactorACircuitFailure" 281 "d281_fastChargePosContactorAStuckOpen" 280 "d280_fastChargePosContactorAStuckClosed" 279 "d279_fastChargePosContactorACircuitFailure" 278 "d278_packNegContactorAStuckClosed" 277 "d277_packNegContactorACircuitFailure" 276 "d276_packPosContactorAStuckClosed" 275 "d275_packPosContactorACircuitFailure" 274 "d274_packCurrentSensorACircuitFailure" 273 "d273_vcFrontCommsLost" 272 "d272_batteryPackSensorCommsLost" 271 "d271_batteryPackSensorFailure" 270 "d270_hvpCommsLost" 269 "d269_highVoltageFuseABlown" 268 "d268_hvpInvalidFirmwareConfig" 267 "d267_batteryPackCellVoltageSenseHarnessFailure" 266 "d266_energyReserveVoltageLow" 265 "d265_replaceBatteryPack" 264 "d264_invalidFirmwareConfig" 263 "d263_batterySystemCurrentHigh" 262 "d262_batteryPackLowStateOfCharge" 261 "d261_batteryPackCellVoltageHigh" 260 "d260_chargePortInterlockFailure" 259 "d259_highVoltageInterlockFailure" 258 "d258_externalIsolationFault" 257 "d257_internalIsolationFault" 256 "a256_SW_Low_Power_Warning" 255 "a255_EstimatedRangeReduced" 254 "a254_LdcsCacImbalance" 227 "a227_ExcessChargeCurrentInCharge" 221 "a221_PcsEmergencyShutdownRequested" 214 "a214_AcChargeAborted" 204 "a204_AcCpEmergencyShutdownRequested" 202 "a202_AcChargeFaulted" 201 "a201_SW_Brick_OV_During_Charge" 200 "a200_GridFollowFaulted" 199 "a199_GridFollowAborted" 198 "a198_SW_SOC_Abrupt_Change" 197 "a197_SW_High_SOC_OV" 196 "a196_SW_PackVoltageUnderThreshold" 195 "a195_SW_DeltaTempOverThreshold" 194 "a194_PowershareLimitViolation" 193 "a193_PowershareMaxBrickVoltageViolation" 192 "a192_PowershareExternalChargeRegulation" 191 "a191_PowershareMinVoltageViolation" 190 "a190_PowershareMaxVoltageViolation" 189 "a189_PowershareDischargeCurrentViolation" 188 "a188_PowershareChargeCurrentViolation" 187 "a187_RippleHeatingEmergencyShutdown" 186 "a186_RippleHeatingChargeFault" 185 "a185_LifeModel_CyclingDcrGrowth_Change" 184 "a184_LifeModel_CyclingLoss_Change" 183 "a183_LifeModel_StoDcrGrowth_Change" 182 "a182_LifeModel_NoCurrentLoss_Change" 181 "a181_SW_Shunt_Over_Temperature" 180 "a180_SW_ECU_reset_blocked" 179 "a179_HvpGpoRequestActive" 178 "a178_SW_Uncontrolled_Regen_PwrB" 177 "a177_SW_Energy_Buffer_Size" 176 "a176_SW_GracefulPowerOff" 175 "a175_Charge_Failure_External" 174 "a174_SW_Charge_Failure" 173 "a173_FullPackEnergyDegraded" 172 "a172_SW_Isolation_Failure_In_Drive_Warning" 171 "a171_SW_Stack_Voltage_Sense" 170 "a170_SW_Limp_Mode" 169 "a169_SW_FC_Pack_Weld" 168 "a168_SW_FC_Full_Weld" 167 "a167_SW_FC_Partial_Weld" 166 "a166_SW_Pack_Full_Weld" 165 "a165_SW_Pack_Partial_Weld" 164 "a164_SW_Uncontrolled_Regen" 163 "a163_GridFormAborted" 162 "a162_SW_No_Power_For_Support" 161 "a161_SW_BMB_Vref_warning" 160 "a160_SW_FC_Ctr_Clean_Failed" 159 "a159_SW_HVP_ECU_Error" 158 "a158_SW_HVP_HVI_Comms" 157 "a157_SW_Hist_Update_Missed" 156 "a156_SW_BMB_Vref_bad" 155 "a155_SW_Weak_short_impedence" 154 "a154_SW_Brick_OV_Warning_Stop_Charge" 153 "a153_GridFormFaulted" 152 "a152_Isolation_In_Dc_Charge" 151 "a151_SW_external_isolation" 150 "a150_SW_Missing_Part_Number" 149 "a149_SW_Missing_Config_Block" 148 "a148_SW_Unsupported_BMB_ASIC_Type" 147 "a147_SW_SOC_High_Ah_Error" 146 "a146_SW_Brick_Overdischarged" 145 "a145_SW_SOC_Change" 144 "a144_Hvp_Config_Mismatch" 143 "a143_SW_CAC_Change" 142 "a142_SW_Isolation_Degradation" 141 "a141_SW_BMB_Status_Warning" 140 "a140_HW_BMB_Status_Fault" 139 "a139_SW_DC_Link_V_Irrational" 138 "a138_SW_Brick_OV_Warning" 137 "a137_SW_Brick_UV_Warning" 136 "a136_SW_Module_OT_Warning" 135 "a135_HW_BMB_Diagnostics_Failure" 134 "a134_SW_Delayed_Ctr_Off" 133 "a133_IO_CAN_Bus_Off" 132 "a132_HW_BMB_OTP_Uncorrctbl" 131 "a131_Bleed_FET_Failure" 130 "a130_IO_CAN_Error" 129 "a129_SW_VSH_Failure" 128 "a128_SW_shunt_MIA" 127 "a127_SW_shunt_SNA" 126 "a126_SW_Thermistor_Failure" 124 "a124_Battery_Coolant_Flood" 123 "a123_SW_Internal_Isolation" 122 "a122_SW_BMS_Therm_Irrational" 121 "a121_SW_NVRAM_Config_Error" 120 "a120_SW_Delta_SOC_User_Warning" 119 "a119_Fast_Open_Vsh_Detected" 118 "a118_SW_Delta_SOC_Weak_Short_Warning" 117 "a117_SW_Delta_SOC_Weak_Short" 115 "a115_Energy_Rubberbanding_Reset" 112 "a112_LifeModel_Discontinuity" 111 "a111_LifeModel_Spread_Change" 110 "a110_LifeModel_AvgOffset_Change" 109 "a109_HW_BMB_Mute_Status_Mismatch" 108 "a108_SW_BMB_Device_OT" 107 "a107_SW_Stack_Voltage_MIA" 106 "a106_SW_All_Module_Tsense" 105 "a105_SW_One_Module_Tsense" 100 "a100_ThermalEventSuspected" 99 "a099_SW_BMB_Communication" 98 "a098_SW_BMB_Data_Integrity_Loss" 97 "a097_SW_BMB_Over_CAN_Communication" 95 "a095_SW_UI_MIA" 94 "a094_SW_Drive_Inverter_MIA" 92 "a092_SW_ChargePort_Mia_On_Hvs" 91 "a091_SW_ChargePort_MIA" 90 "a090_SW_Gateway_MIA" 89 "a089_SW_VcFront_MIA" 88 "a088_SW_VcFront_MIA_InDrive" 87 "a087_SW_Feim_Test_Blocked" 86 "a086_SW_FC_Contactor_Mismatch" 85 "a085_SW_Pack_Contactor_Mismatch" 84 "a084_SW_Sleep_Wake_Aborted" 83 "a083_SW_Ctr_Close_Failure" 82 "a082_SW_Ctr_Force_Open" 81 "a081_SW_Ctr_Close_Blocked" 80 "a080_SW_Pack_Ctr_Impedance" 79 "a079_Max_Charge_Level_Exceeded" 78 "a078_Rapid_Dch_While_Charging" 77 "a077_SW_Charger_Regulation" 76 "a076_SW_Dch_While_Charging" 75 "a075_SW_Chg_Disable_Failure" 74 "a074_Max_Charge_Level_Reduced" 73 "a073_Unexpected_Loss_Of_Lv" 72 "a072_Module_Brick_Split" 71 "a071_SW_SM_TransCon_Not_Met" 70 "a070_BrickV_Imbalance_Limiting" 69 "a069_SW_Low_Power" 68 "a068_CAC_Imbalance_Limp" 67 "a067_CAC_Imbalance_Limiting" 66 "a066_SOC_Imbalance_Warning" 65 "a065_SW_CAC_Imbalance" 64 "a064_SW_SOC_Imbalance" 63 "a063_SW_ChargePort_Fault" 62 "a062_SW_BrickV_Imbalance" 61 "a061_SW_BrickV_Change" 60 "a060_SW_Leakage_Test_Failure" 59 "a059_SW_Pack_Voltage_Sensing" 58 "a058_SW_Bandolier_Model_Reset" 57 "a057_SW_Bandolier_Model_Warning" 56 "a056_SW_Standby_Supply_Fault" 55 "a055_SW_HvChain_Model_Fault" 54 "a054_SW_Ver_Supply_Fault" 52 "a052_SW_PCS_MIA" 51 "a051_SW_HVC_Vref_Bad" 50 "a050_SW_Brick_Voltage_MIA" 49 "a049_SW_Thermal_Event" 48 "a048_SW_Watch_Dog_Warning" 47 "a047_SW_Task_Stack_Overflow" 46 "a046_SW_Task_Stack_Usage" 45 "a045_SW_Exception" 44 "a044_SW_Assertion" 43 "a043_SW_Watch_Dog_Reset" 42 "a042_SW_MPU_Error" 41 "a041_SW_Destructive_Reset_Source" 40 "a040_SW_Watch_Dog_HW_Triggered" 39 "a039_SW_DC_Link_Over_Voltage" 37 "a037_SW_Flood_Port_Open" 36 "a036_SW_HvpHvilFault" 35 "a035_SW_Isolation" 34 "a034_SW_Passive_Isolation" 33 "a033_VoltageDeviation" 32 "a032_VoltageLoss" 31 "a031_AlertsSetDuringSleep" 30 "a030_Impedance_Deviation" 29 "a029_dSoc_Limiting" 28 "a028_ShuntAsicCurrentOffsetDeviation" 27 "a027_SW_Repeated_Isolation_Failure_In_Drive" 26 "a026_SW_HFCurrent_Anomaly" 25 "a025_SW_PwrBalance_Anomaly" 24 "a024_SW_Islanded_Brick" 23 "a023_SW_Stack_OV" 22 "a022_SW_Over_Current" 21 "a021_SW_Dr_Limits_Regulation" 20 "a020_SW_Brick_Instability" 19 "a019_SW_Module_OT" 18 "a018_SW_Brick_UV" 17 "a017_SW_Brick_OV" 16 "a016_Pack_Module_Id_Mismatch" 4 "a004_Cal_Vs_Serial_Birth_Date_Mismatch" 3 "a003_SW_Pack_Birth_Date_Missing" 2 "a002_Pack_Performance_Config_Mismatch" 1 "a001_Pack_Config_Mismatch" 0 "ALERT_DO_NOT_USE_ZERO" ;
VAL_ 1343 BMS_a090_GTWmessageTout 9 "UI_TRIPPLANNING" 8 "MCU_DRIVERLIMITS" 7 "GTW_CARCONFIG2" 6 "GTW_12VSTATUS" 5 "MCU_ODOMETER" 4 "GTW_CARCONFIG" 3 "GTW_PTNM" 2 "GTW_BODYSTATUS" 1 "MCU_POWER" 0 "GTW_COMMANDS" ;
VAL_ 1343 BMS_a098_bmbCommStatusTypeA 3 "BYPASSED" 2 "NOMINAL" 1 "BAD" 0 "MISSING" ;
VAL_ 1343 BMS_a098_bmbCommStatusTypeB 3 "BYPASSED" 2 "NOMINAL" 1 "BAD" 0 "MISSING" ;
VAL_ 1343 BMS_a099_bmbCommStatusTypeA 3 "BYPASSED" 2 "NOMINAL" 1 "BAD" 0 "MISSING" ;
VAL_ 1343 BMS_a099_bmbCommStatusTypeB 3 "BYPASSED" 2 "NOMINAL" 1 "BAD" 0 "MISSING" ;
VAL_ 1343 BMS_a099_bmbChainBreakType 5 "TAIL_BREAK" 4 "HEAD_BREAK" 3 "INVALID_BREAK" 2 "DOUBLE_BREAK" 1 "SINGLE_BREAK" 0 "NONE" ;
VAL_ 1343 BMS_a117_brickSoc2 1023 "SNA" ;
VAL_ 1343 BMS_a117_dSocAlpha 4095 "SNA" ;
VAL_ 1343 BMS_a118_brickSoc2 1023 "SNA" ;
VAL_ 1343 BMS_a118_dSocAlpha 4095 "SNA" ;
VAL_ 1343 BMS_a135_bmbDiagnosticsType 3 "UNUSED" 2 "BMB_DIAG_TEST5" 1 "BMB_DIAG_TESTA" 0 "BMB_DIAG_NONE" ;
VAL_ 1343 BMS_a140_faultType 162 "FAULT_COMM1_BY_UART_TR" 161 "FAULT_COMM1_BY_UART_RR" 160 "FAULT_COMM1_BY_COMMCLR_DET" 159 "FAULT_COMM1_BY_STOP_DET" 158 "FAULT_COMM2_BY_COML_TR" 157 "FAULT_COMM2_BY_COML_RR" 156 "FAULT_COMM2_BY_COML_RC" 155 "FAULT_COMM2_BY_COML_BIT" 154 "FAULT_COMM2_BY_COMH_TR" 153 "FAULT_COMM2_BY_COMH_RR" 152 "FAULT_COMM2_BY_COMH_RC" 151 "FAULT_COMM2_BY_COMH_BIT" 150 "FAULT_COMM3_BY_FCOMM_DET" 149 "FAULT_COMM3_BY_FTONE_DET" 148 "FAULT_COMM3_BY_HB_FAIL" 147 "FAULT_COMM3_BY_HB_FAST" 146 "FAULT_OTP_BY_DED_DET" 145 "FAULT_OTP_BY_SEC_DET" 144 "FAULT_OTP_BY_CUST_CRC" 143 "FAULT_OTP_BY_FACT_CRC" 142 "FAULT_OTP_BY_CUSTLDERR" 141 "FAULT_OTP_BY_FACTLDERR" 140 "FAULT_OTP_BY_GBLOVERR" 139 "FAULT_SYS_BY_LFO" 138 "FAULT_SYS_BY_SHUTDOWN_REC" 137 "FAULT_SYS_BY_GPIO" 136 "FAULT_SYS_BY_DRST" 135 "FAULT_SYS_BY_CTL" 134 "FAULT_SYS_BY_CTS" 133 "FAULT_SYS_BY_TSHUT" 132 "FAULT_SYS_BY_TWARN" 131 "FAULT_COMP_GPIO_BY_GPIO8_FAIL" 130 "FAULT_COMP_GPIO_BY_GPIO7_FAIL" 129 "FAULT_COMP_GPIO_BY_GPIO6_FAIL" 128 "FAULT_COMP_GPIO_BY_GPIO5_FAIL" 127 "FAULT_COMP_GPIO_BY_GPIO4_FAIL" 126 "FAULT_COMP_GPIO_BY_GPIO3_FAIL" 125 "FAULT_COMP_GPIO_BY_GPIO2_FAIL" 124 "FAULT_COMP_GPIO_BY_GPIO1_FAIL" 123 "FAULT_COMP_VCCB1_BY_CELL16_FAIL" 122 "FAULT_COMP_VCCB1_BY_CELL15_FAIL" 121 "FAULT_COMP_VCCB1_BY_CELL14_FAIL" 120 "FAULT_COMP_VCCB1_BY_CELL13_FAIL" 119 "FAULT_COMP_VCCB1_BY_CELL12_FAIL" 118 "FAULT_COMP_VCCB1_BY_CELL11_FAIL" 117 "FAULT_COMP_VCCB1_BY_CELL10_FAIL" 116 "FAULT_COMP_VCCB1_BY_CELL9_FAIL" 115 "FAULT_COMP_VCCB2_BY_CELL8_FAIL" 114 "FAULT_COMP_VCCB2_BY_CELL7_FAIL" 113 "FAULT_COMP_VCCB2_BY_CELL6_FAIL" 112 "FAULT_COMP_VCCB2_BY_CELL5_FAIL" 111 "FAULT_COMP_VCCB2_BY_CELL4_FAIL" 110 "FAULT_COMP_VCCB2_BY_CELL3_FAIL" 109 "FAULT_COMP_VCCB2_BY_CELL2_FAIL" 108 "FAULT_COMP_VCCB2_BY_CELL1_FAIL" 107 "FAULT_COMP_VCOW1_BY_VCOW16_FAIL" 106 "FAULT_COMP_VCOW1_BY_VCOW15_FAIL" 105 "FAULT_COMP_VCOW1_BY_VCOW14_FAIL" 104 "FAULT_COMP_VCOW1_BY_VCOW13_FAIL" 103 "FAULT_COMP_VCOW1_BY_VCOW12_FAIL" 102 "FAULT_COMP_VCOW1_BY_VCOW11_FAIL" 101 "FAULT_COMP_VCOW1_BY_VCOW10_FAIL" 100 "FAULT_COMP_VCOW1_BY_VCOW9_FAIL" 99 "FAULT_COMP_VCOW2_BY_VCOW8_FAIL" 98 "FAULT_COMP_VCOW2_BY_VCOW7_FAIL" 97 "FAULT_COMP_VCOW2_BY_VCOW6_FAIL" 96 "FAULT_COMP_VCOW2_BY_VCOW5_FAIL" 95 "FAULT_COMP_VCOW2_BY_VCOW4_FAIL" 94 "FAULT_COMP_VCOW2_BY_VCOW3_FAIL" 93 "FAULT_COMP_VCOW2_BY_VCOW2_FAIL" 92 "FAULT_COMP_VCOW2_BY_VCOW1_FAIL" 91 "FAULT_COMP_CBOW1_BY_CBOW16_FAIL" 90 "FAULT_COMP_CBOW1_BY_CBOW15_FAIL" 89 "FAULT_COMP_CBOW1_BY_CBOW14_FAIL" 88 "FAULT_COMP_CBOW1_BY_CBOW13_FAIL" 87 "FAULT_COMP_CBOW1_BY_CBOW12_FAIL" 86 "FAULT_COMP_CBOW1_BY_CBOW11_FAIL" 85 "FAULT_COMP_CBOW1_BY_CBOW10_FAIL" 84 "FAULT_COMP_CBOW1_BY_CBOW9_FAIL" 83 "FAULT_COMP_CBOW2_BY_CBOW8_FAIL" 82 "FAULT_COMP_CBOW2_BY_CBOW7_FAIL" 81 "FAULT_COMP_CBOW2_BY_CBOW6_FAIL" 80 "FAULT_COMP_CBOW2_BY_CBOW5_FAIL" 79 "FAULT_COMP_CBOW2_BY_CBOW4_FAIL" 78 "FAULT_COMP_CBOW2_BY_CBOW3_FAIL" 77 "FAULT_COMP_CBOW2_BY_CBOW2_FAIL" 76 "FAULT_COMP_CBOW2_BY_CBOW1_FAIL" 75 "FAULT_COMP_CBFET1_BY_CBFET16_FAIL" 74 "FAULT_COMP_CBFET1_BY_CBFET15_FAIL" 73 "FAULT_COMP_CBFET1_BY_CBFET14_FAIL" 72 "FAULT_COMP_CBFET1_BY_CBFET13_FAIL" 71 "FAULT_COMP_CBFET1_BY_CBFET12_FAIL" 70 "FAULT_COMP_CBFET1_BY_CBFET11_FAIL" 69 "FAULT_COMP_CBFET1_BY_CBFET10_FAIL" 68 "FAULT_COMP_CBFET1_BY_CBFET9_FAIL" 67 "FAULT_COMP_CBFET2_BY_CBFET8_FAIL" 66 "FAULT_COMP_CBFET2_BY_CBFET7_FAIL" 65 "FAULT_COMP_CBFET2_BY_CBFET6_FAIL" 64 "FAULT_COMP_CBFET2_BY_CBFET5_FAIL" 63 "FAULT_COMP_CBFET2_BY_CBFET4_FAIL" 62 "FAULT_COMP_CBFET2_BY_CBFET3_FAIL" 61 "FAULT_COMP_CBFET2_BY_CBFET2_FAIL" 60 "FAULT_COMP_CBFET2_BY_CBFET1_FAIL" 59 "FAULT_COMP_MISC_BY_COMP_ADC_ABORT" 58 "FAULT_COMP_MISC_BY_LPF_FAIL" 57 "FAULT_PWR1_BY_CVSS_OPEN" 56 "FAULT_PWR1_BY_DVSS_OPEN" 55 "FAULT_PWR1_BY_REFHM_OPEN" 54 "FAULT_PWR1_BY_CVDD_UV" 53 "FAULT_PWR1_BY_CVDD_OV" 52 "FAULT_PWR1_BY_DVDD_OV" 51 "FAULT_PWR1_BY_AVDD_OSC" 50 "FAULT_PWR1_BY_AVDD_OV" 49 "FAULT_PWR2_BY_PWRBIST_FAIL" 48 "FAULT_PWR2_BY_REFH_OSC" 47 "FAULT_PWR2_BY_NEG5V_UV" 46 "FAULT_PWR2_BY_TSREF_OSC" 45 "FAULT_PWR2_BY_TSREF_UV" 44 "FAULT_PWR2_BY_TSREF_OV" 43 "FAULT_PWR3_BY_AVDDUV_DRST" 42 "SEQ_ERROR_FAULT_CLEAR" 41 "SEQ_ERROR_FAULT_INJECT" 40 "SEQ_ERROR_CELL_RESUME" 39 "SEQ_ERROR_CELL_FREEZE" 38 "SEQ_ERROR_AUX_RESET" 37 "SEQ_ERROR_AUX_CLEAR" 36 "TEST_MODE" 35 "SUPPLY_RAIL" 34 "CLK_CHECK" 33 "DIGITAL_REF_OV" 32 "DIGITAL_REF_UV" 31 "ANALOG_REF_OV" 30 "ANALOG_REF_UV" 29 "POWER_BIST" 28 "GPIO_COMP" 27 "CBOW_COMP" 26 "VCOW_COMP" 25 "VCCB_COMP" 24 "VBG2_PLAUS" 23 "REFL_PLAUS" 22 "TSREF_PLAUS" 21 "VCM1_PLAUS" 20 "THERM_PLAUS" 19 "DIETEMP_PLAUS" 18 "STACKV_PLAUS" 17 "BRICKV_PLAUS" 16 "ADC_COMP_ABORT" 15 "LPF_FAULT_DET" 14 "AUX_MISC_DRDY" 13 "AUX_GPIO_DRDY" 12 "AUX_VCELL_DRDY" 11 "MAIN_ADC_DRDY" 10 "MAIN_ADC_LPF" 9 "POWER_FAULT" 8 "SYSTEM_FAULT" 7 "COMM_FAULT" 6 "OTP_FAULT" 5 "ADC_COMP_FAULT" 4 "ERROR_OTP_FAULT" 3 "ERROR_OTP_WARNING" 2 "ERROR_ADC_SEQUENCE" 1 "ERROR_POWER_RESET" 0 "ERROR_NONE" ;
VAL_ 1343 BMS_a142_mode 4 "VOLTAGE_SETTLING_MODE" 3 "FEIM_POSITIVE_MODE" 2 "FEIM_NEGATIVE_MODE" 1 "VEHICLE_ISOLATION_MODE" 0 "MODE_RESET" ;
VAL_ 1343 BMS_a145_brickChangeHystRatio 1023 "SNA" ;
VAL_ 1343 BMS_a146_state 10 "DIAG" 9 "SNA" 8 "TEST" 7 "WELD" 6 "FAULT" 5 "CLEAR_FAULT" 4 "FEIM" 3 "CHARGE" 2 "SUPPORT" 1 "DRIVE" 0 "STANDBY" ;
VAL_ 1343 BMS_a152_mode 4 "VOLTAGE_SETTLING_MODE" 3 "FEIM_POSITIVE_MODE" 2 "FEIM_NEGATIVE_MODE" 1 "VEHICLE_ISOLATION_MODE" 0 "MODE_RESET" ;
VAL_ 1343 BMS_a156_VrefStatus 3 "BYPASSED" 2 "NOMINAL" 1 "BAD" 0 "MISSING" ;
VAL_ 1343 BMS_a227_packCurrent -32768 "SNA" ;
VAL_ 1343 BMS_a227_dcChargeCurrentRequest -32768 "SNA" ;
